VERSION ""

NS_ :

BS_:

BU_: SMART_CORE

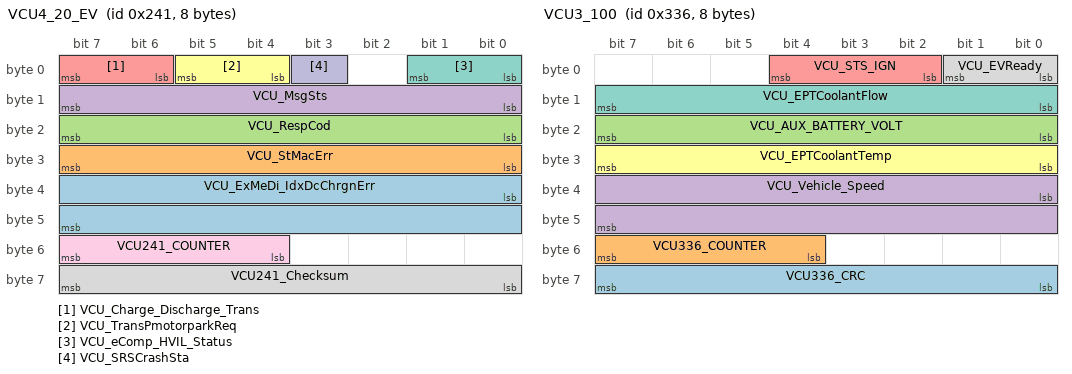
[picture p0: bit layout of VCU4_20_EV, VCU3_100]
BO_ 577 VCU4_20_EV: 8 Vector__XXX
 SG_ VCU_ExMeDi_IdxDcChrgnErr : 32|16@1+ (1,0) [0|65535] ""  SMART_CORE
 SG_ VCU_StMacErr : 24|8@1+ (1,0) [0|255] ""  SMART_CORE
 SG_ VCU_RespCod : 16|8@1+ (1,0) [0|255] ""  SMART_CORE
 SG_ VCU_MsgSts : 8|8@1+ (1,0) [0|255] ""  SMART_CORE
 SG_ VCU_Charge_Discharge_Trans : 6|2@1+ (1,0) [0|3] ""  SMART_CORE
 SG_ VCU_TransPmotorparkReq : 4|2@1+ (1,0) [0|3] "NA"  SMART_CORE
 SG_ VCU_eComp_HVIL_Status : 0|2@1+ (1,0) [0|3] ""  SMART_CORE
 SG_ VCU241_Checksum : 56|8@1+ (1,0) [0|255] ""  SMART_CORE
 SG_ VCU241_COUNTER : 52|4@1+ (1,0) [0|15] ""  SMART_CORE
 SG_ VCU_SRSCrashSta : 3|1@1+ (1,0) [0|1] ""  SMART_CORE

BO_ 822 VCU3_100: 8 Vector__XXX
 SG_ VCU336_CRC : 56|8@1+ (1,0) [0|255] "NA"  SMART_CORE
 SG_ VCU336_COUNTER : 52|4@1+ (1,0) [0|15] "NA"  SMART_CORE
 SG_ VCU_AUX_BATTERY_VOLT : 16|8@1+ (0.1,0) [0|16] "NA"  SMART_CORE
 SG_ VCU_Vehicle_Speed : 32|16@1+ (0.01,0) [0|300] "kmph"  SMART_CORE
 SG_ VCU_STS_IGN : 2|3@1+ (1,0) [0|7] ""  SMART_CORE
 SG_ VCU_EPTCoolantTemp : 24|8@1+ (1,-40) [-40|215] "deg C"  SMART_CORE
 SG_ VCU_EPTCoolantFlow : 8|8@1+ (0.5,0) [0|100] "%"  SMART_CORE
 SG_ VCU_EVReady : 0|2@1+ (1,0) [0|3] "NA"  SMART_CORE

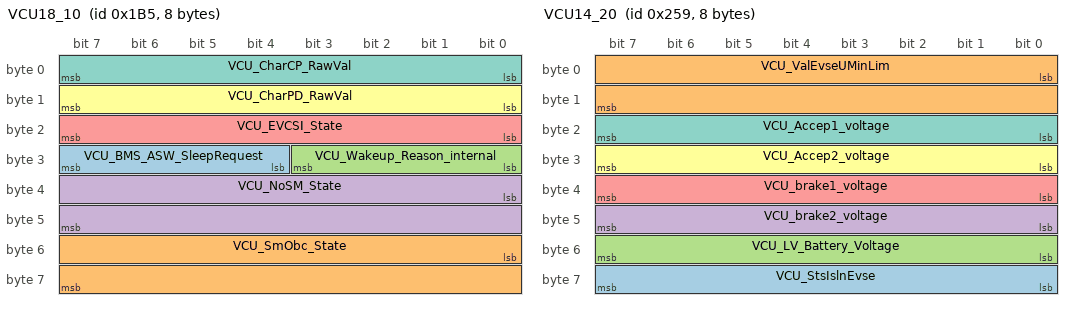
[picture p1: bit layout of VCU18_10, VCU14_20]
BO_ 437 VCU18_10: 8 Vector__XXX
 SG_ VCU_BMS_ASW_SleepRequest : 28|4@1+ (1,0) [0|7] "NA"  SMART_CORE
 SG_ VCU_SmObc_State : 48|16@1+ (1,0) [0|65535] ""  SMART_CORE
 SG_ VCU_Wakeup_Reason_internal : 24|4@1+ (1,0) [0|15] ""  SMART_CORE
 SG_ VCU_NoSM_State : 32|16@1+ (1,0) [0|65535] ""  SMART_CORE
 SG_ VCU_EVCSI_State : 16|8@1+ (1,0) [0|255] ""  SMART_CORE
 SG_ VCU_CharPD_RawVal : 8|8@1+ (0.1,0) [0|20] "V"  SMART_CORE
 SG_ VCU_CharCP_RawVal : 0|8@1+ (0.1,0) [0|20] "V"  SMART_CORE

BO_ 601 VCU14_20: 8 Vector__XXX
 SG_ VCU_StsIslnEvse : 56|8@1+ (1,0) [0|255] ""  SMART_CORE
 SG_ VCU_ValEvseUMinLim : 0|16@1+ (0.1,0) [0|1500] "V"  SMART_CORE
 SG_ VCU_LV_Battery_Voltage : 48|8@1+ (0.1,0) [0|25] "V"  SMART_CORE
 SG_ VCU_brake2_voltage : 40|8@1+ (0.1,0) [0|25] "V"  SMART_CORE
 SG_ VCU_brake1_voltage : 32|8@1+ (0.1,0) [0|25] "V"  SMART_CORE
 SG_ VCU_Accep2_voltage : 24|8@1+ (0.1,0) [0|25] "V"  SMART_CORE
 SG_ VCU_Accep1_voltage : 16|8@1+ (0.1,0) [0|25] "V"  SMART_CORE

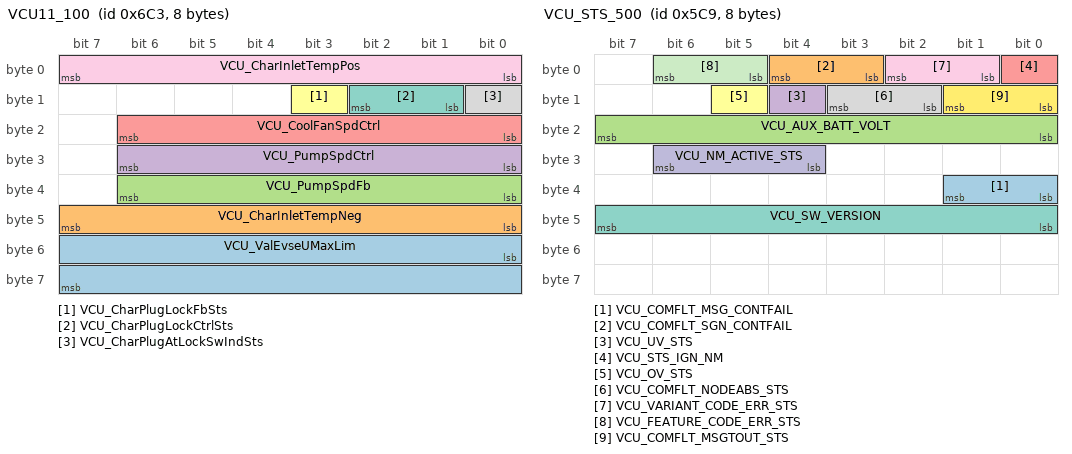
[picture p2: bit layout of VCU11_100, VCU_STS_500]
BO_ 1731 VCU11_100: 8 Vector__XXX
 SG_ VCU_ValEvseUMaxLim : 48|16@1+ (0.1,0) [0|1500] "V"  SMART_CORE
 SG_ VCU_CharInletTempNeg : 40|8@1+ (1,-40) [-40|215] "deg"  SMART_CORE
 SG_ VCU_PumpSpdFb : 32|7@1+ (1,0) [0|100] "%"  SMART_CORE
 SG_ VCU_PumpSpdCtrl : 24|7@1+ (1,0) [0|100] "%"  SMART_CORE
 SG_ VCU_CoolFanSpdCtrl : 16|7@1+ (1,0) [0|100] "%"  SMART_CORE
 SG_ VCU_CharPlugLockFbSts : 11|1@1+ (1,0) [0|1] ""  SMART_CORE
 SG_ VCU_CharPlugLockCtrlSts : 9|2@1+ (1,0) [0|2] ""  SMART_CORE
 SG_ VCU_CharPlugAtLockSwIndSts : 8|1@1+ (1,0) [0|1] ""  SMART_CORE
 SG_ VCU_CharInletTempPos : 0|8@1+ (1,-40) [-40|215] "deg"  SMART_CORE

BO_ 1481 VCU_STS_500: 8 Vector__XXX
 SG_ VCU_COMFLT_MSG_CONTFAIL : 32|2@1+ (1,0) [0|3] ""  SMART_CORE
 SG_ VCU_COMFLT_SGN_CONTFAIL : 3|2@1+ (1,0) [0|3] ""  SMART_CORE
 SG_ VCU_AUX_BATT_VOLT : 16|8@1+ (0.1,0) [0|16] ""  SMART_CORE
 SG_ VCU_UV_STS : 12|1@1+ (1,0) [0|1] ""  SMART_CORE
 SG_ VCU_STS_IGN_NM : 0|1@1+ (1,0) [0|1] ""  SMART_CORE
 SG_ VCU_OV_STS : 13|1@1+ (1,0) [0|1] ""  SMART_CORE
 SG_ VCU_SW_VERSION : 40|8@1+ (1,0) [0|255] ""  SMART_CORE
 SG_ VCU_COMFLT_NODEABS_STS : 10|2@1+ (1,0) [0|3] ""  SMART_CORE
 SG_ VCU_VARIANT_CODE_ERR_STS : 1|2@1+ (1,0) [0|3] ""  SMART_CORE
 SG_ VCU_NM_ACTIVE_STS : 28|3@1+ (1,0) [0|7] ""  SMART_CORE
 SG_ VCU_FEATURE_CODE_ERR_STS : 5|2@1+ (1,0) [0|3] ""  SMART_CORE
 SG_ VCU_COMFLT_MSGTOUT_STS : 8|2@1+ (1,0) [0|3] ""  SMART_CORE

BO_ 988 OBC6_100: 8 Vector__XXX
 SG_ OBC_VIN_MISMATCH_FAULT : 63|1@1+ (1,0) [0|1] ""  SMART_CORE
 SG_ OBC_ECU_RESET_FAULT : 62|1@1+ (1,0) [0|1] ""  SMART_CORE
 SG_ OBC_Low_Temp_Shutdown : 47|1@1+ (1,0) [0|1] ""  SMART_CORE
 SG_ OBC_HVDC_HW_OV : 35|1@1+ (1,0) [0|1] ""  SMART_CORE
 SG_ OBC_CPVol_Out_of_Range : 46|1@1+ (1,0) [0|1] ""  SMART_CORE
 SG_ OBC_CPDuty_Out_of_Range : 37|1@1+ (1,0) [0|1] ""  SMART_CORE
 SG_ OBC_HVDC_HW_OC : 36|1@1+ (1,0) [0|1] ""  SMART_CORE
 SG_ OBC_PRECHARGE_FAULT_CNT : 59|3@1+ (1,0) [0|7] ""  SMART_CORE
 SG_ OBC_PFC_BUS_FAULT_CNT : 56|3@1+ (1,0) [0|7] ""  SMART_CORE
 SG_ OBC_PFC_VOLT_CNTRL_IP : 48|8@1+ (1,-30) [-30|30] ""  SMART_CORE
 SG_ OBC_LIne_OC_SW : 16|1@1+ (1,0) [0|1] ""  SMART_CORE
 SG_ OBC_LLC_CONTROL_INPUT : 40|6@1+ (1,20) [-20|20] ""  SMART_CORE
 SG_ OBC_PLL_TIMELOCK_STS : 34|1@1+ (1,0) [0|1] ""  SMART_CORE
 SG_ OBC_CC_CV_STS : 33|1@1+ (1,0) [0|1] ""  SMART_CORE
 SG_ OBC_BURST_MODE_STS : 32|1@1+ (1,0) [0|1] ""  SMART_CORE
 SG_ OBC_STATE : 28|4@1+ (1,0) [0|1] ""  SMART_CORE
 SG_ OBC_LLC_OC_HW_FLAG : 18|1@1+ (1,0) [0|1] ""  SMART_CORE
 SG_ OBC_PFC_OC_HW_Flag : 17|1@1+ (1,0) [0|1] ""  SMART_CORE
 SG_ OBC_Inductr_current_L2_OC : 39|1@1+ (1,0) [0|1] ""  SMART_CORE
 SG_ OBC_Inductr_current_L1_OC : 38|1@1+ (1,0) [0|1] ""  SMART_CORE
 SG_ OBC_VPROG_OUT_OF_RANGE : 27|1@1+ (1,0) [0|1] ""  SMART_CORE
 SG_ OBC_TEMP_SENSOR_FAIL : 26|1@1+ (1,0) [0|1] ""  SMART_CORE
 SG_ OBC_OVER_TEMP : 25|1@1+ (1,0) [0|1] ""  SMART_CORE
 SG_ OBC_INTERNAL_FAIL : 24|1@1+ (1,0) [0|1] ""  SMART_CORE
 SG_ OBC_HIGH_TEMP : 23|1@1+ (1,0) [0|1] ""  SMART_CORE
 SG_ OBC_IPROG_OUT_OF_RANGE : 22|1@1+ (1,0) [0|1] ""  SMART_CORE
 SG_ OBC_EMI_IP_UV : 21|1@1+ (1,0) [0|1] ""  SMART_CORE
 SG_ OBC_EMI_IP_OV : 20|1@1+ (1,0) [0|1] ""  SMART_CORE
 SG_ OBC_EEPROM_FAIL : 19|1@1+ (1,0) [0|1] ""  SMART_CORE
 SG_ OBC_CAN_BUS_OFF : 15|1@1+ (1,0) [0|1] ""  SMART_CORE
 SG_ OBC_TEMP_DERATE : 14|1@1+ (1,0) [0|1] ""  SMART_CORE
 SG_ OBC_PRE_CHARGE_FAULT : 13|1@1+ (1,0) [0|1] ""  SMART_CORE
 SG_ OBC_PFV_OV : 12|1@1+ (1,0) [0|1] ""  SMART_CORE
 SG_ OBC_PFC_UV : 11|1@1+ (1,0) [0|1] ""  SMART_CORE
 SG_ OBC_PFC_OVER_TEMP : 10|1@1+ (1,0) [0|1] ""  SMART_CORE
 SG_ OBC_OP_UV : 9|1@1+ (1,0) [0|1] ""  SMART_CORE
 SG_ OBC_OP_OV : 8|1@1+ (1,0) [0|1] ""  SMART_CORE
 SG_ OBC_OP_OC : 7|1@1+ (1,0) [0|1] ""  SMART_CORE
 SG_ OBC_LV_UNDER_VOLT : 6|1@1+ (1,0) [0|1] ""  SMART_CORE
 SG_ OBC_LV_OVER_VOLT : 5|1@1+ (1,0) [0|1] ""  SMART_CORE
 SG_ OBC_LLC_OVER_TEMP : 4|1@1+ (1,0) [0|1] ""  SMART_CORE
 SG_ OBC_IP_UNDER_VOLT : 3|1@1+ (1,0) [0|1] ""  SMART_CORE
 SG_ OBC_IP_OVER_VOLT : 2|1@1+ (1,0) [0|1] ""  SMART_CORE
 SG_ OBC_IP_OVER_CURR : 1|1@1+ (1,0) [0|1] ""  SMART_CORE
 SG_ OBC_IP_DERATE : 0|1@1+ (1,0) [0|1] ""  SMART_CORE

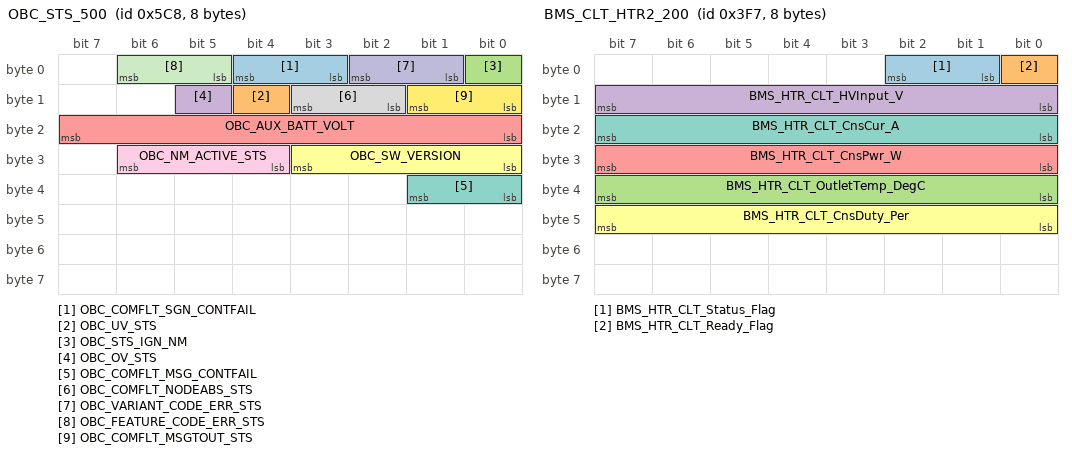
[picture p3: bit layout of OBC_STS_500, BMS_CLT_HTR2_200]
BO_ 1480 OBC_STS_500: 8 Vector__XXX
 SG_ OBC_COMFLT_SGN_CONTFAIL : 3|2@1+ (1,0) [0|3] ""  SMART_CORE
 SG_ OBC_UV_STS : 12|1@1+ (1,0) [0|1] ""  SMART_CORE
 SG_ OBC_STS_IGN_NM : 0|1@1+ (1,0) [0|1] ""  SMART_CORE
 SG_ OBC_OV_STS : 13|1@1+ (1,0) [0|1] ""  SMART_CORE
 SG_ OBC_AUX_BATT_VOLT : 16|8@1+ (0.1,0) [0|16] ""  SMART_CORE
 SG_ OBC_SW_VERSION : 24|4@1+ (1,0) [0|15] ""  SMART_CORE
 SG_ OBC_COMFLT_MSG_CONTFAIL : 32|2@1+ (1,0) [0|3] ""  SMART_CORE
 SG_ OBC_COMFLT_NODEABS_STS : 10|2@1+ (1,0) [0|3] ""  SMART_CORE
 SG_ OBC_NM_ACTIVE_STS : 28|3@1+ (1,0) [0|7] ""  SMART_CORE
 SG_ OBC_VARIANT_CODE_ERR_STS : 1|2@1+ (1,0) [0|3] ""  SMART_CORE
 SG_ OBC_FEATURE_CODE_ERR_STS : 5|2@1+ (1,0) [0|3] ""  SMART_CORE
 SG_ OBC_COMFLT_MSGTOUT_STS : 8|2@1+ (1,0) [0|3] ""  SMART_CORE

BO_ 983 MCU5_100: 8 Vector__XXX
 SG_ MCU_TPI : 8|8@1+ (0.01,0) [0|2] ""  SMART_CORE
 SG_ MCU_MotorCoolingFlowReq : 32|8@1+ (0.5,0) [0|100] "%"  SMART_CORE
 SG_ MCU_Motor_Temp_Indicator : 24|8@1+ (1,-50) [-50|200] "deg C"  SMART_CORE
 SG_ MCU_Inverter_Temp_Indicator : 16|8@1+ (1,-50) [-50|200] "deg C"  SMART_CORE
 SG_ MCU_Inverter_CoolingFlowReq : 0|8@1+ (0.5,0) [0|100] "%"  SMART_CORE

BO_ 280 MCU2_10: 8 Vector__XXX
 SG_ MCU118_COUNTER : 52|4@1+ (1,0) [0|15] ""  SMART_CORE
 SG_ MCU118_Checksum : 56|8@1+ (1,0) [0|255] ""  SMART_CORE
 SG_ MCU_MotorSpeed : 16|16@1+ (1,-32767) [-32760|32760] "RPM"  SMART_CORE
 SG_ MCU_MotorTorqueEstimated : 0|16@1+ (0.0625,-2048) [-2045|2045] "Nm"  SMART_CORE

BO_ 1016 BMS_CLT_HTR3_200: 8 Vector__XXX
 SG_ BMS_HTR_CLT_SoftwareVersion_Num : 56|8@1+ (1,0) [0|255] ""  SMART_CORE
 SG_ BMS_HTR_CLT_Fault_PCBTempSen : 28|1@1+ (1,0) [0|1] ""  SMART_CORE
 SG_ BMS_HTR_CLT_Fault_PCBTempOver : 14|1@1+ (1,0) [0|1] ""  SMART_CORE
 SG_ BMS_HTR_CLT_Fault_OutletTempSen : 27|1@1+ (1,0) [0|1] ""  SMART_CORE
 SG_ BMS_HTR_CLT_Fault_OutletTempOver : 13|1@1+ (1,0) [0|1] ""  SMART_CORE
 SG_ BMS_HTR_CLT_Fault_LVSen : 24|1@1+ (1,0) [0|1] ""  SMART_CORE
 SG_ BMS_HTR_CLT_Fault_LostCtrlMsg : 15|1@1+ (1,0) [0|1] ""  SMART_CORE
 SG_ BMS_HTR_CLT_Fault_IGBTShort : 30|1@1+ (1,0) [0|1] ""  SMART_CORE
 SG_ BMS_HTR_CLT_Fault_IGBTOpen : 29|1@1+ (1,0) [0|1] ""  SMART_CORE
 SG_ BMS_HTR_CLT_Fault_IGBTDriverIC : 31|1@1+ (1,0) [0|1] ""  SMART_CORE
 SG_ BMS_HTR_CLT_Fault_HVSen : 25|1@1+ (1,0) [0|1] ""  SMART_CORE
 SG_ BMS_HTR_CLT_Fault_HVOver : 11|1@1+ (1,0) [0|1] ""  SMART_CORE
 SG_ BMS_HTR_CLT_Fault_HVCurSen : 26|1@1+ (1,0) [0|1] ""  SMART_CORE
 SG_ BMS_HTR_CLT_LIN_Com_Err_Flag : 1|1@1+ (1,0) [0|1] ""  SMART_CORE
 SG_ BMS_HTR_CLT_Fault_LVUnder : 8|1@1+ (1,0) [0|1] ""  SMART_CORE
 SG_ BMS_HTR_CLT_Fault_LVOver : 9|1@1+ (1,0) [0|1] ""  SMART_CORE
 SG_ BMS_HTR_CLT_Fault_HVUnder : 10|1@1+ (1,0) [0|1] ""  SMART_CORE
 SG_ BMS_HTR_CLT_Fault_HVOverCur : 12|1@1+ (1,0) [0|1] ""  SMART_CORE
 SG_ BMS_HTR_CLT_Fault_Flag : 0|1@1+ (1,0) [0|1] ""  SMART_CORE

BO_ 1918 MGM_FOTA_DIAG_RES: 8 Vector__XXX
 SG_ DIAG_MGM_FOTA_RES_DATA : 0|64@1+ (1,0) [0|1.8446744074E+019] ""  SMART_CORE

BO_ 1910 MGM_FOTA_DIAG_REQ: 8 SMART_CORE
 SG_ DIAG_MGM_FOTA_REQ_DATA : 0|64@1+ (1,0) [0|1.8446744074E+019] "" Vector__XXX

BO_ 1015 BMS_CLT_HTR2_200: 8 Vector__XXX
 SG_ BMS_HTR_CLT_Status_Flag : 1|2@1+ (1,1) [0|2] ""  SMART_CORE
 SG_ BMS_HTR_CLT_Ready_Flag : 0|1@1+ (1,0) [0|1] ""  SMART_CORE
 SG_ BMS_HTR_CLT_OutletTemp_DegC : 32|8@1+ (1,0) [0|255] ""  SMART_CORE
 SG_ BMS_HTR_CLT_HVInput_V : 8|8@1+ (1,0) [0|255] ""  SMART_CORE
 SG_ BMS_HTR_CLT_CnsPwr_W : 24|8@1+ (1,0) [0|255] ""  SMART_CORE
 SG_ BMS_HTR_CLT_CnsDuty_Per : 40|8@1+ (1,0) [0|255] ""  SMART_CORE
 SG_ BMS_HTR_CLT_CnsCur_A : 16|8@1+ (1,0) [0|255] ""  SMART_CORE

BO_ 1014 BMS_CLT_HTR1_200: 8 Vector__XXX
 SG_ BMS_HTR_CltTemp_DegC : 16|8@1+ (1,0) [0|255] ""  SMART_CORE
 SG_ BMS_HTR_CltPerf_Perc : 8|8@1- (1,0) [0|255] ""  SMART_CORE
 SG_ BMS_HTR_CltAllowance_Flag : 0|1@1+ (1,0) [0|1] ""  SMART_CORE

BO_ 993 VCU_ACTIVE_EV: 8 Vector__XXX
 SG_ VCU_ACTIVE_RESERVED_EV : 0|64@1+ (1,0) [0|0] "NA"  SMART_CORE

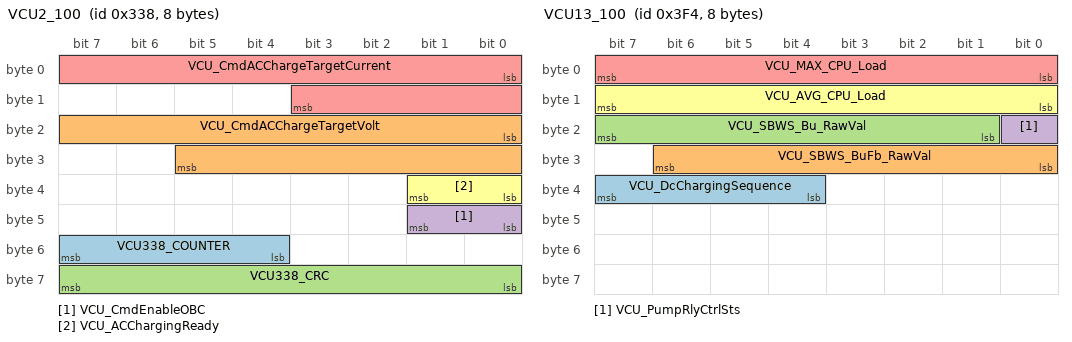
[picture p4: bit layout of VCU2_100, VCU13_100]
BO_ 824 VCU2_100: 8 Vector__XXX
 SG_ VCU338_COUNTER : 52|4@1+ (1,0) [0|15] "NA"  SMART_CORE
 SG_ VCU_CmdACChargeTargetVolt : 16|14@1+ (0.1,0) [0|500] "V"  SMART_CORE
 SG_ VCU338_CRC : 56|8@1+ (1,0) [0|255] "NA"  SMART_CORE
 SG_ VCU_CmdEnableOBC : 40|2@1+ (1,0) [0|3] "NA"  SMART_CORE
 SG_ VCU_CmdACChargeTargetCurrent : 0|12@1+ (0.01,0) [0|35] "A"  SMART_CORE
 SG_ VCU_ACChargingReady : 32|2@1+ (1,0) [0|3] ""  SMART_CORE

BO_ 1474 VCU17_500: 8 Vector__XXX
 SG_ VCU_AVAIL_BAT_HEATER_PWR : 48|8@1+ (50,0) [0|8000] "Watts"  SMART_CORE

BO_ 1736 VCU16_1000: 8 Vector__XXX
 SG_ VCU_EConsDistSample4 : 48|16@1+ (0.001,0) [0|65.535] "Kwh"  SMART_CORE
 SG_ VCU_EConsDistSample3 : 32|16@1+ (0.001,0) [0|65.535] "Kwh"  SMART_CORE
 SG_ VCU_EConsDistSample2 : 16|16@1+ (0.001,0) [0|65.535] "Kwh"  SMART_CORE
 SG_ VCU_EConsDistSample1 : 0|16@1+ (0.001,0) [0|65.535] "Kwh"  SMART_CORE

BO_ 1012 VCU13_100: 8 Vector__XXX
 SG_ VCU_DcChargingSequence : 36|4@1+ (1,0) [0|15] ""  SMART_CORE
 SG_ VCU_SBWS_BuFb_RawVal : 24|7@1+ (1,0) [0|100] "%"  SMART_CORE
 SG_ VCU_SBWS_Bu_RawVal : 17|7@1+ (1,0) [0|100] "%"  SMART_CORE
 SG_ VCU_PumpRlyCtrlSts : 16|1@1+ (1,0) [0|1] ""  SMART_CORE
 SG_ VCU_MAX_CPU_Load : 0|8@1+ (1,0) [0|200] ""  SMART_CORE
 SG_ VCU_AVG_CPU_Load : 8|8@1+ (1,0) [0|200] ""  SMART_CORE

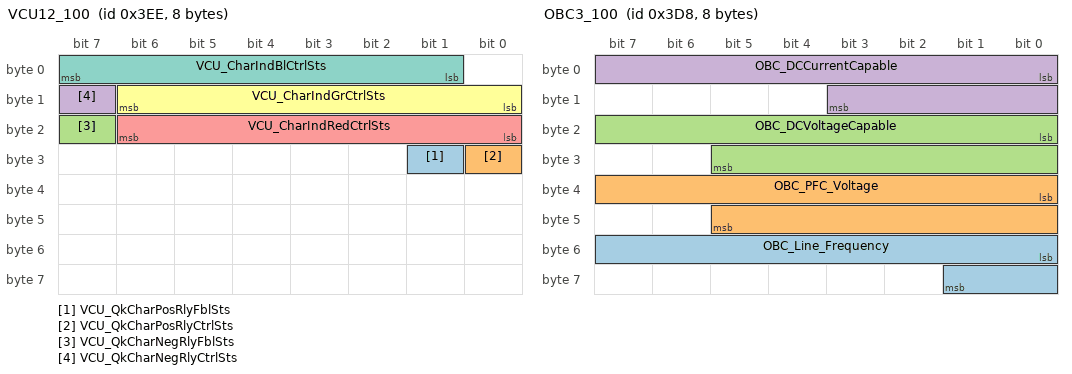
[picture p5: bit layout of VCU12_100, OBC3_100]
BO_ 1006 VCU12_100: 8 Vector__XXX
 SG_ VCU_QkCharPosRlyFblSts : 25|1@1+ (1,0) [0|1] ""  SMART_CORE
 SG_ VCU_QkCharPosRlyCtrlSts : 24|1@1+ (1,0) [0|1] ""  SMART_CORE
 SG_ VCU_QkCharNegRlyFblSts : 23|1@1+ (1,0) [0|1] ""  SMART_CORE
 SG_ VCU_QkCharNegRlyCtrlSts : 15|1@1+ (1,0) [0|1] ""  SMART_CORE
 SG_ VCU_CharIndRedCtrlSts : 16|7@1+ (1,0) [0|100] "%"  SMART_CORE
 SG_ VCU_CharIndGrCtrlSts : 8|7@1+ (1,0) [0|100] "%"  SMART_CORE
 SG_ VCU_CharIndBlCtrlSts : 1|7@1+ (1,0) [0|100] "%"  SMART_CORE

BO_ 984 OBC3_100: 8 Vector__XXX
 SG_ OBC_Line_Frequency : 48|10@1+ (1,0) [40|65] ""  SMART_CORE
 SG_ OBC_PFC_Voltage : 32|14@1+ (0.1,0) [0|500] ""  SMART_CORE
 SG_ OBC_DCVoltageCapable : 16|14@1+ (0.1,0) [0|500] "V"  SMART_CORE
 SG_ OBC_DCCurrentCapable : 0|12@1+ (0.01,0) [0|30] "A"  SMART_CORE

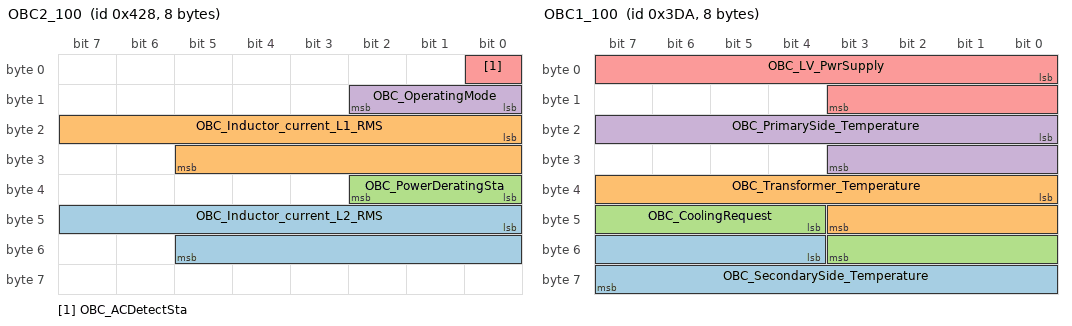
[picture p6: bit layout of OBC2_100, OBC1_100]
BO_ 1064 OBC2_100: 8 Vector__XXX
 SG_ OBC_Inductor_current_L2_RMS : 40|14@1+ (0.01,0) [0|20] ""  SMART_CORE
 SG_ OBC_Inductor_current_L1_RMS : 16|14@1+ (0.01,0) [0|20] ""  SMART_CORE
 SG_ OBC_PowerDeratingSta : 32|3@1+ (1,0) [0|7] "NA"  SMART_CORE
 SG_ OBC_OperatingMode : 8|3@1+ (1,0) [0|7] "NA"  SMART_CORE
 SG_ OBC_ACDetectSta : 0|1@1+ (1,0) [0|1] "NA"  SMART_CORE

BO_ 986 OBC1_100: 8 Vector__XXX
 SG_ OBC_SecondarySide_Temperature : 52|12@1+ (0.1,-55) [-55|150] ""  SMART_CORE
 SG_ OBC_Transformer_Temperature : 32|12@1+ (0.1,-55) [-55|150] "deg C"  SMART_CORE
 SG_ OBC_CoolingRequest : 44|8@1+ (0.5,0) [0|100] "%"  SMART_CORE
 SG_ OBC_PrimarySide_Temperature : 16|12@1+ (0.1,-55) [-55|150] "deg C"  SMART_CORE
 SG_ OBC_LV_PwrSupply : 0|12@1+ (0.01,0) [0|25] ""  SMART_CORE

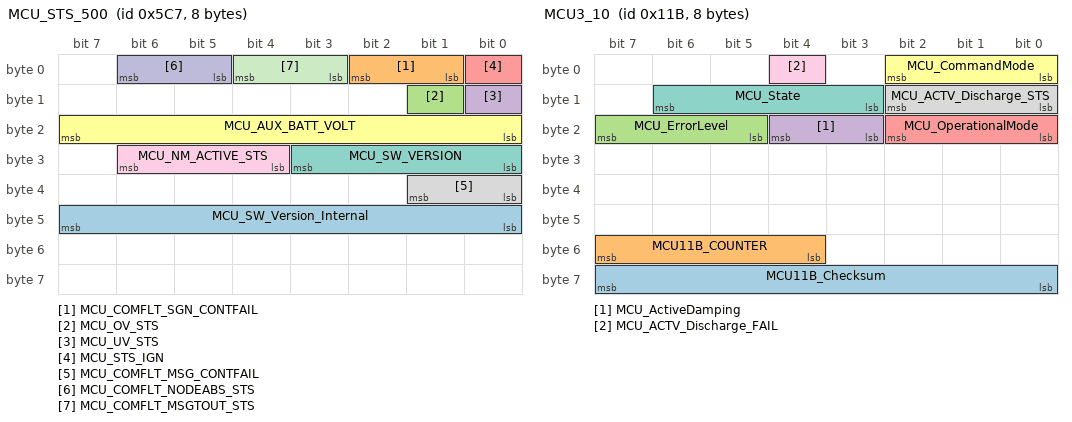
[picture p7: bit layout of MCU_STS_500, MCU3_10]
BO_ 1479 MCU_STS_500: 8 Vector__XXX
 SG_ MCU_SW_Version_Internal : 40|8@1+ (1,0) [0|255] ""  SMART_CORE
 SG_ MCU_COMFLT_SGN_CONTFAIL : 1|2@1+ (1,0) [0|3] ""  SMART_CORE
 SG_ MCU_OV_STS : 9|1@1+ (1,0) [0|1] ""  SMART_CORE
 SG_ MCU_UV_STS : 8|1@1+ (1,0) [0|1] ""  SMART_CORE
 SG_ MCU_STS_IGN : 0|1@1+ (1,0) [0|1] ""  SMART_CORE
 SG_ MCU_AUX_BATT_VOLT : 16|8@1+ (0.1,0) [0|16] ""  SMART_CORE
 SG_ MCU_SW_VERSION : 24|4@1+ (1,0) [0|15] ""  SMART_CORE
 SG_ MCU_COMFLT_MSG_CONTFAIL : 32|2@1+ (1,0) [0|3] ""  SMART_CORE
 SG_ MCU_NM_ACTIVE_STS : 28|3@1+ (1,0) [0|7] ""  SMART_CORE
 SG_ MCU_COMFLT_NODEABS_STS : 5|2@1+ (1,0) [0|3] ""  SMART_CORE
 SG_ MCU_COMFLT_MSGTOUT_STS : 3|2@1+ (1,0) [0|3] ""  SMART_CORE

BO_ 283 MCU3_10: 8 Vector__XXX
 SG_ MCU11B_Checksum : 56|8@1+ (1,0) [0|255] ""  SMART_CORE
 SG_ MCU11B_COUNTER : 52|4@1+ (1,0) [0|15] ""  SMART_CORE
 SG_ MCU_ErrorLevel : 21|3@1+ (1,0) [0|7] "NA"  SMART_CORE
 SG_ MCU_ActiveDamping : 19|2@1+ (1,0) [0|3] "NA"  SMART_CORE
 SG_ MCU_OperationalMode : 16|3@1+ (1,0) [0|7] "NA"  SMART_CORE
 SG_ MCU_CommandMode : 0|3@1+ (1,0) [0|7] "NA"  SMART_CORE
 SG_ MCU_State : 11|4@1+ (1,0) [0|15] ""  SMART_CORE
 SG_ MCU_ACTV_Discharge_STS : 8|3@1+ (1,0) [0|3] ""  SMART_CORE
 SG_ MCU_ACTV_Discharge_FAIL : 4|1@1+ (1,0) [0|1] ""  SMART_CORE

BO_ 982 MCU1_100: 8 Vector__XXX
 SG_ MCU_HighPowerCurrent : 48|14@1+ (0.25,-2046) [-2046|2048] "A"  SMART_CORE
 SG_ MCU_HighPowerVoltage : 32|11@1+ (1,0) [0|2046] "V"  SMART_CORE
 SG_ MCU_TractionTorqueAvail_quasi : 16|15@1+ (0.0625,0) [0|2045] "Nm"  SMART_CORE
 SG_ MCU_RegenTorqueAvail_quasi : 0|15@1+ (0.0625,0) [0|2045] "Nm"  SMART_CORE

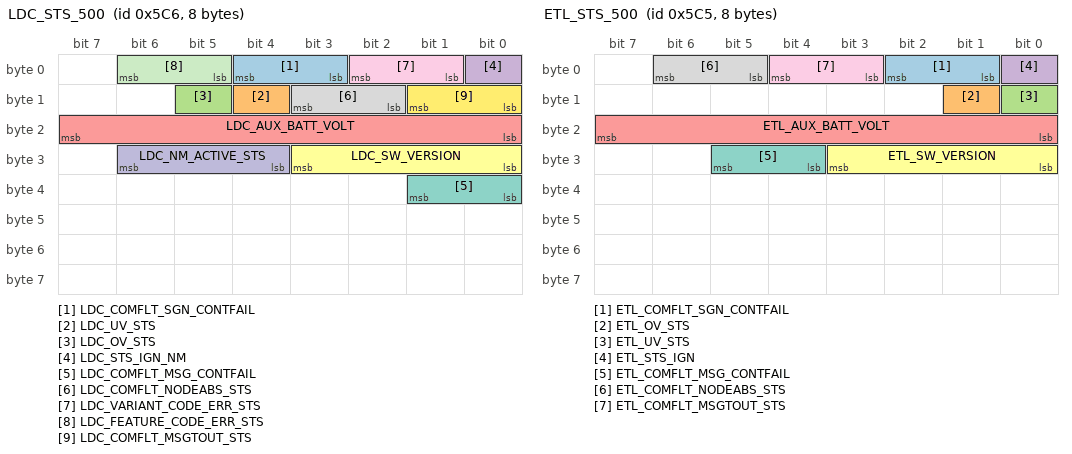
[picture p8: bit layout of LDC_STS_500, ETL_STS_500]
BO_ 1478 LDC_STS_500: 8 Vector__XXX
 SG_ LDC_COMFLT_SGN_CONTFAIL : 3|2@1+ (1,0) [0|3] ""  SMART_CORE
 SG_ LDC_UV_STS : 12|1@1+ (1,0) [0|1] ""  SMART_CORE
 SG_ LDC_OV_STS : 13|1@1+ (1,0) [0|1] ""  SMART_CORE
 SG_ LDC_STS_IGN_NM : 0|1@1+ (1,0) [0|1] ""  SMART_CORE
 SG_ LDC_AUX_BATT_VOLT : 16|8@1+ (0.1,0) [0|16] ""  SMART_CORE
 SG_ LDC_SW_VERSION : 24|4@1+ (1,0) [0|15] ""  SMART_CORE
 SG_ LDC_COMFLT_MSG_CONTFAIL : 32|2@1+ (1,0) [0|3] ""  SMART_CORE
 SG_ LDC_COMFLT_NODEABS_STS : 10|2@1+ (1,0) [0|3] ""  SMART_CORE
 SG_ LDC_VARIANT_CODE_ERR_STS : 1|2@1+ (1,0) [0|3] ""  SMART_CORE
 SG_ LDC_NM_ACTIVE_STS : 28|3@1+ (1,0) [0|7] ""  SMART_CORE
 SG_ LDC_FEATURE_CODE_ERR_STS : 5|2@1+ (1,0) [0|3] ""  SMART_CORE
 SG_ LDC_COMFLT_MSGTOUT_STS : 8|2@1+ (1,0) [0|3] ""  SMART_CORE

BO_ 1477 ETL_STS_500: 8 Vector__XXX
 SG_ ETL_COMFLT_SGN_CONTFAIL : 1|2@1+ (1,0) [0|3] ""  SMART_CORE
 SG_ ETL_OV_STS : 9|1@1+ (1,0) [0|1] ""  SMART_CORE
 SG_ ETL_UV_STS : 8|1@1+ (1,0) [0|1] ""  SMART_CORE
 SG_ ETL_STS_IGN : 0|1@1+ (1,0) [0|1] ""  SMART_CORE
 SG_ ETL_AUX_BATT_VOLT : 16|8@1+ (0.1,0) [0|16] ""  SMART_CORE
 SG_ ETL_SW_VERSION : 24|4@1+ (1,0) [0|15] ""  SMART_CORE
 SG_ ETL_COMFLT_MSG_CONTFAIL : 28|2@1+ (1,0) [0|3] ""  SMART_CORE
 SG_ ETL_COMFLT_NODEABS_STS : 5|2@1+ (1,0) [0|3] ""  SMART_CORE
 SG_ ETL_COMFLT_MSGTOUT_STS : 3|2@1+ (1,0) [0|3] ""  SMART_CORE

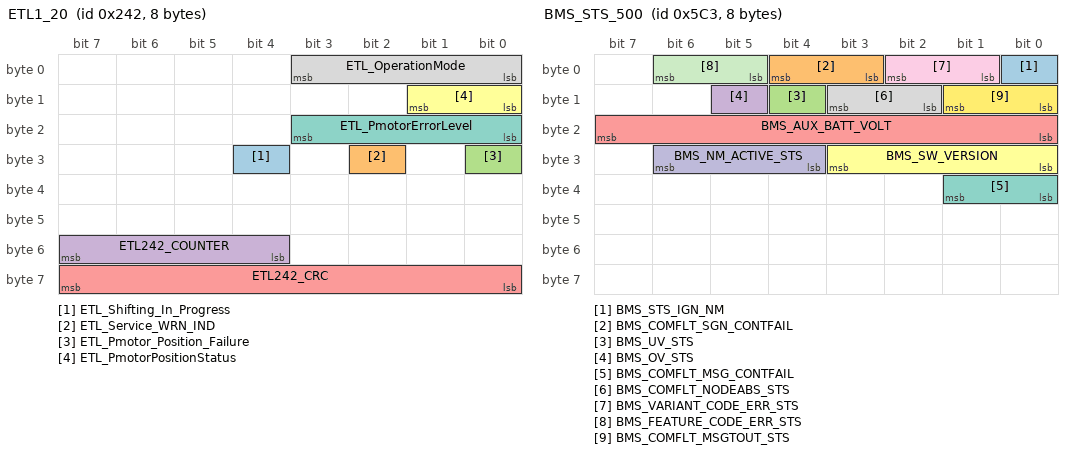
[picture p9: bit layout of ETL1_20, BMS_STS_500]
BO_ 578 ETL1_20: 8 Vector__XXX
 SG_ ETL_Shifting_In_Progress : 28|1@1+ (1,0) [0|1] ""  SMART_CORE
 SG_ ETL_Service_WRN_IND : 26|1@1+ (1,0) [0|1] ""  SMART_CORE
 SG_ ETL_Pmotor_Position_Failure : 24|1@1+ (1,0) [0|1] ""  SMART_CORE
 SG_ ETL242_COUNTER : 52|4@1+ (1,0) [0|14] "NA"  SMART_CORE
 SG_ ETL242_CRC : 56|8@1+ (1,0) [0|255] "NA"  SMART_CORE
 SG_ ETL_PmotorPositionStatus : 8|2@1+ (1,0) [0|3] "NA"  SMART_CORE
 SG_ ETL_PmotorErrorLevel : 16|4@1+ (1,0) [0|15] "NA"  SMART_CORE
 SG_ ETL_OperationMode : 0|4@1+ (1,0) [0|15] "NA"  SMART_CORE

BO_ 1475 BMS_STS_500: 8 Vector__XXX
 SG_ BMS_STS_IGN_NM : 0|1@1+ (1,0) [0|1] ""  SMART_CORE
 SG_ BMS_COMFLT_SGN_CONTFAIL : 3|2@1+ (1,0) [0|3] ""  SMART_CORE
 SG_ BMS_UV_STS : 12|1@1+ (1,0) [0|1] ""  SMART_CORE
 SG_ BMS_OV_STS : 13|1@1+ (1,0) [0|1] ""  SMART_CORE
 SG_ BMS_AUX_BATT_VOLT : 16|8@1+ (0.1,0) [0|16] ""  SMART_CORE
 SG_ BMS_SW_VERSION : 24|4@1+ (1,0) [0|15] ""  SMART_CORE
 SG_ BMS_COMFLT_MSG_CONTFAIL : 32|2@1+ (1,0) [0|3] ""  SMART_CORE
 SG_ BMS_COMFLT_NODEABS_STS : 10|2@1+ (1,0) [0|3] ""  SMART_CORE
 SG_ BMS_VARIANT_CODE_ERR_STS : 1|2@1+ (1,0) [0|3] ""  SMART_CORE
 SG_ BMS_NM_ACTIVE_STS : 28|3@1+ (1,0) [0|7] ""  SMART_CORE
 SG_ BMS_FEATURE_CODE_ERR_STS : 5|2@1+ (1,0) [0|3] ""  SMART_CORE
 SG_ BMS_COMFLT_MSGTOUT_STS : 8|2@1+ (1,0) [0|3] ""  SMART_CORE

BO_ 1002 BMS17_100: 8 Vector__XXX
 SG_ BMS_Regen_AH : 32|16@1+ (0.01,0) [0|300] "AH"  SMART_CORE
 SG_ BMS_KiloWattHour : 16|16@1+ (0.01,0) [0|50] "KWH"  SMART_CORE
 SG_ BMS_AmpereHour : 0|16@1+ (0.01,0) [0|300] "Ah"  SMART_CORE

BO_ 980 BMS7_100: 8 Vector__XXX
 SG_ BMS_Batt_Overcurrent_Sta : 48|2@1+ (1,0) [0|3] "NA"  SMART_CORE
 SG_ BMS_DischargePowerAvailable_2 : 16|16@1+ (0.01,0) [0|200] "Kw"  SMART_CORE
 SG_ BMS_DischargePowerAvailable_10 : 0|16@1+ (0.01,0) [0|200] "Kw"  SMART_CORE
 SG_ BMS_BatteryPackSOE : 32|12@1+ (0.01,0) [0|45] "Kwh"  SMART_CORE

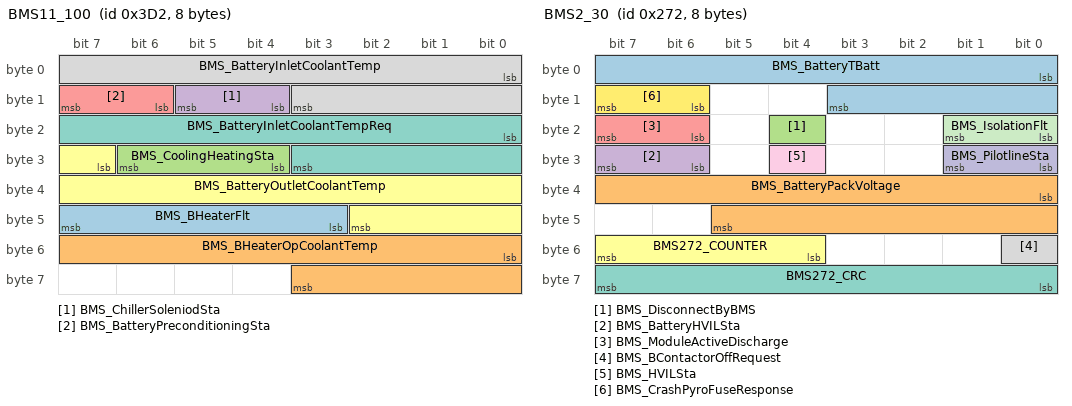
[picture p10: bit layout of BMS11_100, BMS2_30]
BO_ 978 BMS11_100: 8 Vector__XXX
 SG_ BMS_BHeaterFlt : 43|5@1+ (1,0) [0|32] ""  SMART_CORE
 SG_ BMS_BHeaterOpCoolantTemp : 48|12@1+ (0.1,-40) [-40|200] "deg C"  SMART_CORE
 SG_ BMS_CoolingHeatingSta : 28|3@1+ (1,0) [0|7] ""  SMART_CORE
 SG_ BMS_ChillerSoleniodSta : 12|2@1+ (1,0) [0|3] ""  SMART_CORE
 SG_ BMS_BatteryPreconditioningSta : 14|2@1+ (1,0) [0|3] ""  SMART_CORE
 SG_ BMS_BatteryOutletCoolantTemp : 31|12@1+ (0.1,-40) [-40|125] "deg C"  SMART_CORE
 SG_ BMS_BatteryInletCoolantTempReq : 16|12@1+ (0.1,-40) [-40|125] "deg C"  SMART_CORE
 SG_ BMS_BatteryInletCoolantTemp : 0|12@1+ (0.1,-40) [-40|125] "deg C"  SMART_CORE

BO_ 626 BMS2_30: 8 Vector__XXX
 SG_ BMS_BatteryTBatt : 0|12@1+ (0.1,-40) [-40|125] "deg C"  SMART_CORE
 SG_ BMS_BatteryPackVoltage : 32|14@1+ (0.1,0) [0|460] "V"  SMART_CORE
 SG_ BMS_DisconnectByBMS : 20|1@1+ (1,0) [0|1] ""  SMART_CORE
 SG_ BMS_BatteryHVILSta : 30|2@1+ (1,0) [0|3] "NA"  SMART_CORE
 SG_ BMS_ModuleActiveDischarge : 22|2@1+ (1,0) [0|3] ""  SMART_CORE
 SG_ BMS272_COUNTER : 52|4@1+ (1,0) [0|0] "NA"  SMART_CORE
 SG_ BMS272_CRC : 56|8@1+ (1,0) [0|0] "NA"  SMART_CORE
 SG_ BMS_BContactorOffRequest : 48|1@1+ (1,0) [0|1] "NA"  SMART_CORE
 SG_ BMS_HVILSta : 28|1@1+ (1,0) [0|1] "NA"  SMART_CORE
 SG_ BMS_PilotlineSta : 24|2@1+ (1,0) [0|3] "NA"  SMART_CORE
 SG_ BMS_IsolationFlt : 16|2@1+ (1,0) [0|3] "NA"  SMART_CORE
 SG_ BMS_CrashPyroFuseResponse : 14|2@1+ (1,0) [0|3] ""  SMART_CORE

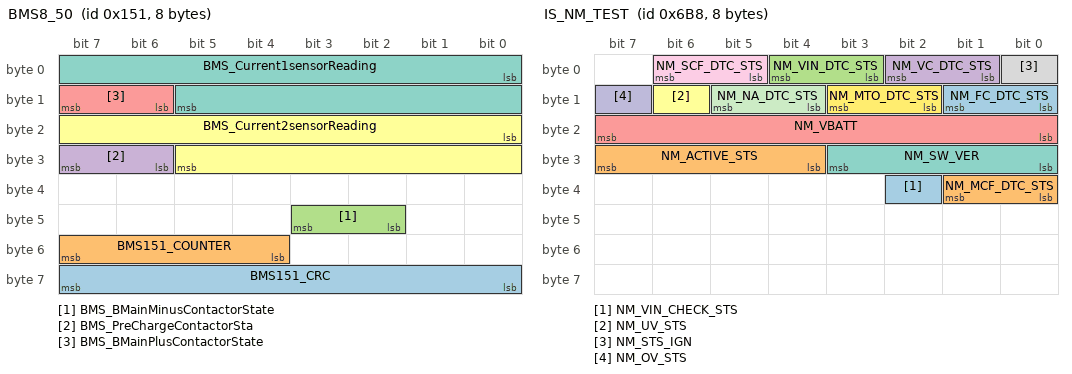
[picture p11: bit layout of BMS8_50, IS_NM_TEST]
BO_ 337 BMS8_50: 8 Vector__XXX
 SG_ BMS151_CRC : 56|8@1+ (1,0) [0|0] "NA"  SMART_CORE
 SG_ BMS151_COUNTER : 52|4@1+ (1,0) [0|0] "NA"  SMART_CORE
 SG_ BMS_BMainMinusContactorState : 42|2@1+ (1,0) [0|3] "NA"  SMART_CORE
 SG_ BMS_PreChargeContactorSta : 30|2@1+ (1,0) [0|3] ""  SMART_CORE
 SG_ BMS_BMainPlusContactorState : 14|2@1+ (1,0) [0|3] "NA"  SMART_CORE
 SG_ BMS_Current2sensorReading : 16|14@1+ (0.1,-600) [-600|600] "A"  SMART_CORE
 SG_ BMS_Current1sensorReading : 0|14@1+ (0.1,-600) [-600|600] "A"  SMART_CORE

BO_ 1720 IS_NM_TEST: 8 SMART_CORE
 SG_ NM_VIN_CHECK_STS : 34|1@1+ (1,0) [0|1] "" Vector__XXX
 SG_ NM_MCF_DTC_STS : 32|2@1+ (1,0) [0|3] "" Vector__XXX
 SG_ NM_VIN_DTC_STS : 3|2@1+ (1,0) [0|3] "" Vector__XXX
 SG_ NM_VC_DTC_STS : 1|2@1+ (1,0) [0|3] "" Vector__XXX
 SG_ NM_VBATT : 16|8@1+ (0.1,0) [0|25] "Volt" Vector__XXX
 SG_ NM_UV_STS : 14|1@1+ (1,0) [0|1] "" Vector__XXX
 SG_ NM_SW_VER : 24|4@1+ (1,0) [0|15] "" Vector__XXX
 SG_ NM_STS_IGN : 0|1@1+ (1,0) [0|1] "" Vector__XXX
 SG_ NM_SCF_DTC_STS : 5|2@1+ (1,0) [0|3] "" Vector__XXX
 SG_ NM_OV_STS : 15|1@1+ (1,0) [0|1] "" Vector__XXX
 SG_ NM_NA_DTC_STS : 12|2@1+ (1,0) [0|3] "" Vector__XXX
 SG_ NM_MTO_DTC_STS : 10|2@1+ (1,0) [0|3] "" Vector__XXX
 SG_ NM_FC_DTC_STS : 8|2@1+ (1,0) [0|3] "" Vector__XXX
 SG_ NM_ACTIVE_STS : 28|4@1+ (1,0) [0|15] "" Vector__XXX

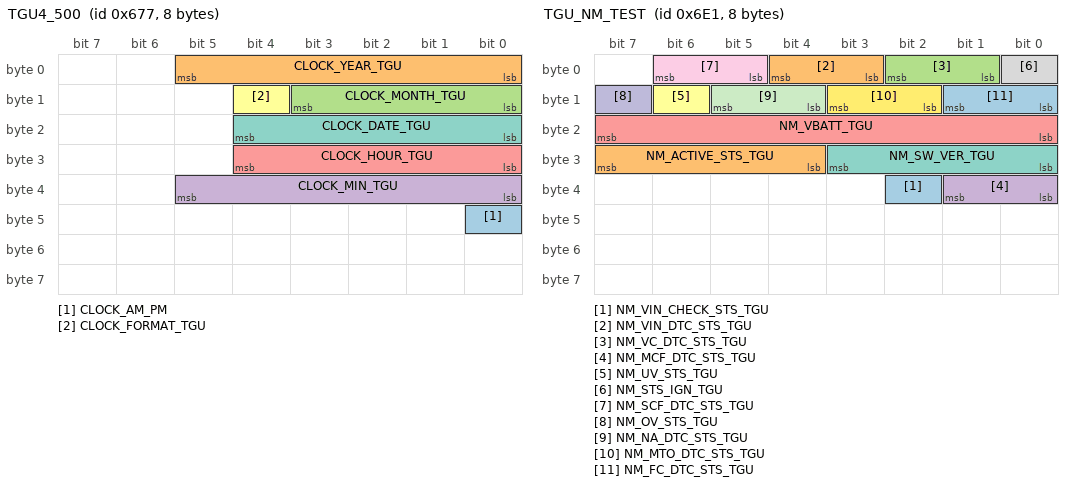
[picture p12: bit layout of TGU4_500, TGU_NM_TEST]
BO_ 1655 TGU4_500: 8 SMART_CORE
 SG_ CLOCK_AM_PM : 40|1@1+ (1,0) [0|1] "" Vector__XXX
 SG_ CLOCK_YEAR_TGU : 0|6@1+ (1,2000) [2016|2063] "" Vector__XXX
 SG_ CLOCK_MONTH_TGU : 8|4@1+ (1,0) [0|12] "" Vector__XXX
 SG_ CLOCK_MIN_TGU : 32|6@1+ (1,0) [0|59] "Minute" Vector__XXX
 SG_ CLOCK_HOUR_TGU : 24|5@1+ (1,0) [0|23] "Hour" Vector__XXX
 SG_ CLOCK_FORMAT_TGU : 12|1@1+ (1,0) [0|1] "" Vector__XXX
 SG_ CLOCK_DATE_TGU : 16|5@1+ (1,0) [0|31] "" Vector__XXX

BO_ 339 TGU2_100: 8 SMART_CORE
 SG_ TGU_CHARGINGENDTIME_FORMAT m1 : 3|1@1+ (1,0) [-1|0] "" Vector__XXX
 SG_ TGU_CHARGINGSTARTTIME_FORMAT m0 : 4|1@1+ (1,0) [0|1] "" Vector__XXX
 SG_ TGU_CHRG_STRT_TIME_HOURS m0 : 5|5@1+ (1,0) [0|24] "" Vector__XXX
 SG_ TGU_ENERGYCONS m0 : 48|8@1+ (1,0) [0|255] "" Vector__XXX
 SG_ TGU_EV_CHRG_PARAM_INDEX M : 0|2@1+ (1,0) [0|3] "" Vector__XXX
 SG_ TGU_CHARGINGSTARTTIME_DATE m0 : 16|16@1+ (1,0) [0|31] "" Vector__XXX
 SG_ TGU_CHRG_START_TIME_MIN m0 : 10|6@1+ (1,0) [0|59] "" Vector__XXX
 SG_ TGU_CHARGINGSTARTTIME_MONTH m0 : 32|8@1+ (1,0) [0|12] "" Vector__XXX
 SG_ TGU_CHARGINGSTARTTIME_YEAR m0 : 40|6@1+ (1,2000) [2016|2063] "" Vector__XXX
 SG_ TGU_CHARGINGENDTIME_DATE m1 : 16|16@1+ (1,0) [0|31] "" Vector__XXX
 SG_ TGU_CHARGINGENDTIME_HOURS m1 : 5|5@1+ (1,0) [0|23] "" Vector__XXX
 SG_ TGU_CHARGINGENDTIME_MIN m1 : 10|6@1+ (1,0) [0|59] "" Vector__XXX
 SG_ TGU_CHARGINGENDTIME_MONTH m1 : 32|8@1+ (1,0) [0|12] "" Vector__XXX
 SG_ TGU_CHRGING_DURATION_MIN m1 : 56|6@1+ (1,0) [0|59] "" Vector__XXX
 SG_ TGU_CHARGINGENDTIME_YEAR m1 : 40|6@1+ (1,2000) [2016|2063] "" Vector__XXX
 SG_ TGU_CHRGING_DURATION_HOURS m1 : 48|5@1+ (1,0) [0|24] "" Vector__XXX

BO_ 338 TGU1_100: 8 SMART_CORE
 SG_ TGU_TRIPSTARTTIME_FORMAT m3 : 4|1@1+ (1,0) [0|1] "" Vector__XXX
 SG_ TGU_TRIPENDTIME_FORMAT m4 : 4|1@1+ (1,0) [0|1] "" Vector__XXX
 SG_ TGU_TRIPSTARTTIME_YEAR m3 : 40|6@1+ (1,2000) [2016|2063] "" Vector__XXX
 SG_ TGU_TRIPSTARTTIME_MIN m3 : 10|6@1+ (1,0) [0|59] "" Vector__XXX
 SG_ TGU_TRIP_START_TIME_HOURS m3 : 5|5@1+ (1,0) [0|24] "" Vector__XXX
 SG_ TGU_TRIPENDTIME_YEAR m4 : 40|6@1+ (1,2000) [2016|2063] "" Vector__XXX
 SG_ TGU_TRIPENDTIME_MONTH m4 : 32|8@1+ (1,0) [0|12] "" Vector__XXX
 SG_ TGU_TRIPENDTIME_MIN m4 : 10|6@1+ (1,0) [0|59] "" Vector__XXX
 SG_ TGU_TRIPENDTIME_DATE m4 : 16|16@1+ (1,0) [0|31] "" Vector__XXX
 SG_ TGU_TRIPEFFICIENCY m1 : 6|2@1+ (1,0) [0|3] "" Vector__XXX
 SG_ TGU_TRIPAVGVEHICLESPEED m1 : 24|8@1+ (1,0) [0|255] "" Vector__XXX
 SG_ TGU_TRIP_TOP_SPEED m1 : 32|8@1+ (1,0) [0|254] "" Vector__XXX
 SG_ TGU_TRIP_START_TIME_MONTH m3 : 32|8@1+ (1,0) [0|12] "" Vector__XXX
 SG_ TGU_TRIP_START_TIME_DATE m3 : 16|16@1+ (1,0) [0|31] "" Vector__XXX
 SG_ TGU_TRIP_END_TIME_HOURS m4 : 5|5@1+ (1,0) [0|24] "" Vector__XXX
 SG_ TGU_TRIP_DURATION_MIN m4 : 51|6@1- (1,0) [0|59] "" Vector__XXX
 SG_ TGU_TRIP_DURATION_HOURS m4 : 46|5@1+ (1,0) [0|24] "" Vector__XXX
 SG_ TGU_TRIP_DISTANCE m1 : 8|16@1+ (1,0) [0|650] "" Vector__XXX
 SG_ TGU_TREES_SAVED m0 : 40|16@1+ (1,0) [0|9999] "" Vector__XXX
 SG_ TGU_CO2 m2 : 8|32@1+ (1,0) [0|999999] "" Vector__XXX
 SG_ TGU_EV_KILOMETERS m0 : 8|32@1+ (1,0) [0|999999] "" Vector__XXX
 SG_ TGU_FRESHDATAFLAG m0 : 4|1@1+ (1,0) [0|1] "" Vector__XXX
 SG_ TGU_EV_PARAM_INDEX M : 0|3@1+ (1,0) [-4|3] "" Vector__XXX

BO_ 1761 TGU_NM_TEST: 8 SMART_CORE
 SG_ NM_VIN_CHECK_STS_TGU : 34|1@1+ (1,0) [0|1] "" Vector__XXX
 SG_ NM_VIN_DTC_STS_TGU : 3|2@1+ (1,0) [0|3] "" Vector__XXX
 SG_ NM_VC_DTC_STS_TGU : 1|2@1+ (1,0) [0|3] "" Vector__XXX
 SG_ NM_MCF_DTC_STS_TGU : 32|2@1+ (1,0) [0|3] "" Vector__XXX
 SG_ NM_VBATT_TGU : 16|8@1+ (0.1,0) [0|25] "Volt" Vector__XXX
 SG_ NM_UV_STS_TGU : 14|1@1+ (1,0) [0|1] "" Vector__XXX
 SG_ NM_SW_VER_TGU : 24|4@1+ (1,0) [0|15] "" Vector__XXX
 SG_ NM_STS_IGN_TGU : 0|1@1+ (1,0) [0|1] "" Vector__XXX
 SG_ NM_SCF_DTC_STS_TGU : 5|2@1+ (1,0) [0|3] "" Vector__XXX
 SG_ NM_OV_STS_TGU : 15|1@1+ (1,0) [0|1] "" Vector__XXX
 SG_ NM_NA_DTC_STS_TGU : 12|2@1+ (1,0) [0|3] "" Vector__XXX
 SG_ NM_MTO_DTC_STS_TGU : 10|2@1+ (1,0) [0|3] "" Vector__XXX
 SG_ NM_FC_DTC_STS_TGU : 8|2@1+ (1,0) [0|3] "" Vector__XXX
 SG_ NM_ACTIVE_STS_TGU : 28|4@1+ (1,0) [0|15] "" Vector__XXX

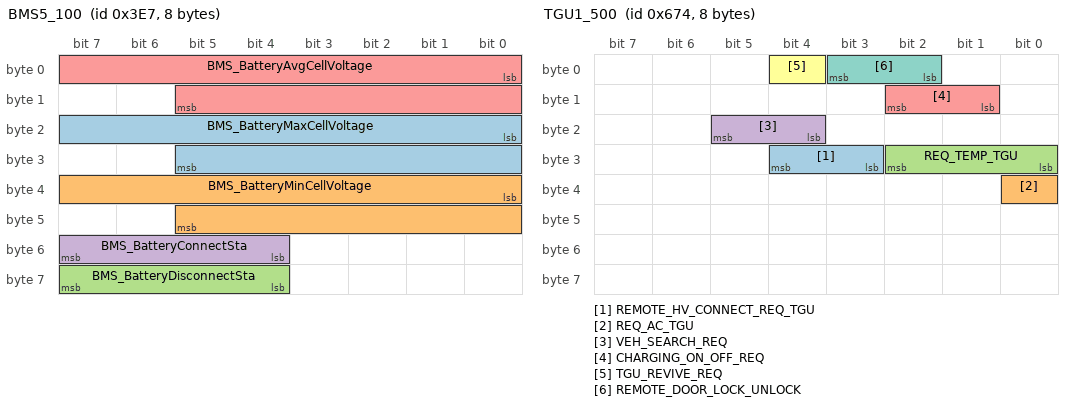
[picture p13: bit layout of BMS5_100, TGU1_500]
BO_ 999 BMS5_100: 8 Vector__XXX
 SG_ BMS_BatteryMaxCellVoltage : 16|14@1+ (1,0) [0|5000] "mV"  SMART_CORE
 SG_ BMS_BatteryMinCellVoltage : 32|14@1+ (1,0) [0|5000] "mV"  SMART_CORE
 SG_ BMS_BatteryDisconnectSta : 60|4@1+ (1,0) [0|15] ""  SMART_CORE
 SG_ BMS_BatteryConnectSta : 52|4@1+ (1,0) [0|15] "NA"  SMART_CORE
 SG_ BMS_BatteryAvgCellVoltage : 0|14@1+ (1,0) [0|5000] "mV"  SMART_CORE

BO_ 1000 BMS4_100: 8 Vector__XXX
 SG_ BMS_BatteryPackSOH : 32|10@1+ (0.1,0) [0|100] "%"  SMART_CORE
 SG_ BMS_BatteryPackRSOC : 16|10@1+ (0.1,0) [0|100] "%"  SMART_CORE
 SG_ BMS_BatteryPackASOC : 0|10@1+ (0.1,0) [0|100] "%"  SMART_CORE

BO_ 2005 TGU_DIAG_REQ: 8 Vector__XXX
 SG_ DIAG_TGU_REQ_DATA : 0|64@1+ (1,0) [0|1.8446744074E+019] ""  SMART_CORE

BO_ 2013 TGU_DIAG_RES: 8 SMART_CORE
 SG_ DIAG_TGU_RES_DATA : 0|64@1+ (1,0) [0|1.8446744074E+019] "" Vector__XXX

BO_ 1652 TGU1_500: 8 SMART_CORE
 SG_ REMOTE_HV_CONNECT_REQ_TGU : 27|2@1+ (1,0) [0|3] "" Vector__XXX
 SG_ REQ_AC_TGU : 32|1@1+ (1,0) [0|1] "" Vector__XXX
 SG_ REQ_TEMP_TGU : 24|3@1+ (1,0) [0|7] "" Vector__XXX
 SG_ VEH_SEARCH_REQ : 20|2@1+ (1,0) [0|3] "" Vector__XXX
 SG_ CHARGING_ON_OFF_REQ : 9|2@1+ (1,0) [0|3] "" Vector__XXX
 SG_ TGU_REVIVE_REQ : 4|1@1+ (1,0) [0|1] "" Vector__XXX
 SG_ REMOTE_DOOR_LOCK_UNLOCK : 2|2@1+ (1,0) [0|3] "" Vector__XXX

BO_ 374 AMT5_20: 8 Vector__XXX
 SG_ ENGINE_STOP_AMT : 14|1@1+ (1,0) [0|1] ""  SMART_CORE
 SG_ TGS_MODE_AMT : 10|2@1+ (1,0) [0|3] ""  SMART_CORE
 SG_ TCU_SHIFT_MODE : 8|2@1+ (1,0) [0|3] ""  SMART_CORE
 SG_ GEAR_ACTUAL_AMT : 0|4@1+ (1,0) [0|15] ""  SMART_CORE

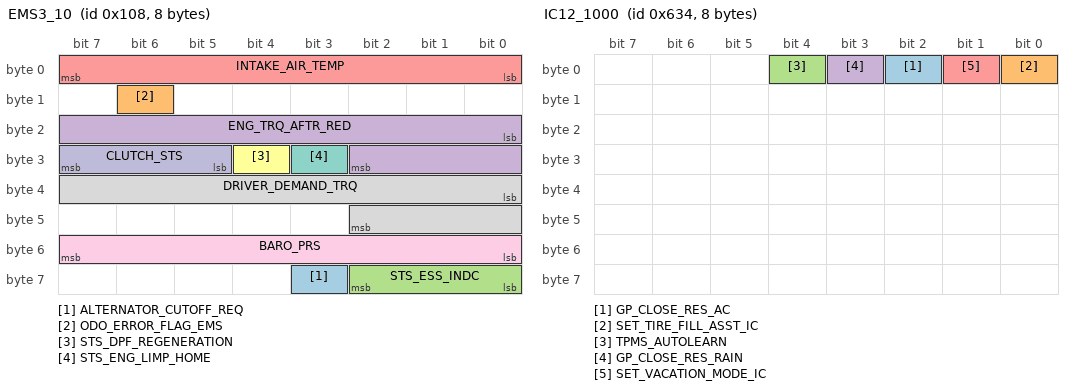
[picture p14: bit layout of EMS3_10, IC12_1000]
BO_ 264 EMS3_10: 8 Vector__XXX
 SG_ ALTERNATOR_CUTOFF_REQ : 59|1@1+ (1,0) [0|1] ""  SMART_CORE
 SG_ ODO_ERROR_FLAG_EMS : 14|1@1+ (1,0) [0|1] ""  SMART_CORE
 SG_ STS_ESS_INDC : 56|3@1+ (1,0) [0|7] ""  SMART_CORE
 SG_ ENG_TRQ_AFTR_RED : 16|11@1+ (1,-1024) [-1024|1022] "Nm"  SMART_CORE
 SG_ INTAKE_AIR_TEMP : 0|8@1+ (1,-40) [-40|214] "DegC"  SMART_CORE
 SG_ STS_DPF_REGENERATION : 28|1@1+ (1,0) [0|1] ""  SMART_CORE
 SG_ STS_ENG_LIMP_HOME : 27|1@1+ (1,0) [0|1] ""  SMART_CORE
 SG_ DRIVER_DEMAND_TRQ : 32|11@1+ (1,-1024) [-1024|1022] "Nm"  SMART_CORE
 SG_ BARO_PRS : 48|8@1+ (1,0) [0|254] "Kpa"  SMART_CORE
 SG_ CLUTCH_STS : 29|3@1+ (1,0) [0|7] ""  SMART_CORE

BO_ 1919 MGM_DIAG_RES: 8 Vector__XXX
 SG_ DIAG_MGM_RES_DATA : 0|64@1+ (1,0) [0|1.8446744074E+019] ""  SMART_CORE

BO_ 1911 MGM_DIAG_REQ: 8 SMART_CORE
 SG_ DIAG_MGM_REQ_DATA : 0|64@1+ (1,0) [0|1.8446744074E+019] ""  SMART_CORE

BO_ 1980 LDC_DIAG_RES: 8 Vector__XXX
 SG_ DIAG_LDC_RES_DATA : 0|64@1+ (1,0) [0|1.8446744074E+019] "NA"  SMART_CORE

BO_ 2008 MCU_DIAG_RES: 8 Vector__XXX
 SG_ DIAG_MCU_RES_DATA : 0|64@1+ (1,0) [0|0] ""  SMART_CORE

BO_ 579 VCU_EVCAN_WAKEUP: 8 Vector__XXX
 SG_ VCU_EVCAN_WAKEUPREASONRESERVED2 : 24|40@1+ (1,0) [0|5] "NA"  SMART_CORE
 SG_ VCU_EVCAN_WAKEUPREASONRESERVED1 : 0|8@1+ (1,0) [0|5] "NA"  SMART_CORE
 SG_ VCU_EVCAN_WAKEUPREASON : 8|16@1+ (1,0) [0|5] "NA"  SMART_CORE

BO_ 936 VCU_EVCAN_SLEEP: 8 Vector__XXX
 SG_ VCU_EVCAN_SLEEPRESERVED : 0|64@1+ (1,0) [0|0] "NA"  SMART_CORE

BO_ 1933 ETL_DIAG_RES: 8 Vector__XXX
 SG_ DIAG_ETL_RES_DATA : 0|64@1+ (1,0) [0|1.8446744074E+019] "NA"  SMART_CORE

BO_ 1981 OBC_DIAG_RES: 8 Vector__XXX
 SG_ DIAG_OBC_RES_DATA : 0|64@1+ (1,0) [0|1.8446744074E+019] "NA"  SMART_CORE

BO_ 1976 BMS_DIAG_RES: 8 Vector__XXX
 SG_ DIAG_BMS_RES_DATA : 0|64@1+ (1,0) [0|1.8446744074E+019] "NA"  SMART_CORE

BO_ 1972 LDC_DIAG_REQ: 8 SMART_CORE
 SG_ DIAG_LDC_REQ_DATA : 0|64@1+ (1,0) [0|1.8446744074E+019] "NA" Vector__XXX

BO_ 1925 ETL_DIAG_REQ: 8 SMART_CORE
 SG_ DIAG_ETL_REQ_DATA : 0|64@1+ (1,0) [0|1.8446744074E+019] "NA" Vector__XXX

BO_ 1973 OBC_DIAG_REQ: 8 SMART_CORE
 SG_ DIAG_OBC_REQ_DATA : 0|64@1+ (1,0) [0|1.8446744074E+019] "NA" Vector__XXX

BO_ 2000 MCU_DIAG_REQ: 8 SMART_CORE
 SG_ DIAG_MCU_REQ_DATA : 0|64@1+ (1,0) [0|1.8446744074E+019] "NA" Vector__XXX

BO_ 1968 BMS_DIAG_REQ: 8 SMART_CORE
 SG_ DIAG_BMS_REQ_DATA : 0|64@1+ (1,0) [0|1.8446744074E+019] "NA" Vector__XXX

BO_ 336 BMS18_50: 8 Vector__XXX
 SG_ BMS_TotalCycle_Time : 48|16@1+ (1,0) [0|65535] "Min"  SMART_CORE
 SG_ BMS_DischargeCycle_Time : 32|16@1+ (1,0) [0|65535] "Min"  SMART_CORE
 SG_ BMS_ChargeCycle_Time : 16|16@1+ (1,0) [0|65535] "Min"  SMART_CORE
 SG_ BMS_CycleNumber : 0|16@1+ (1,0) [0|65534] ""  SMART_CORE

BO_ 285 BMS16_10: 8 Vector__XXX
 SG_ BMS_BattPack_PwrLimitErr_Common : 39|1@1+ (1,0) [0|1] ""  SMART_CORE
 SG_ BMS_Bat_I_OvrExtCurr_Flt_Dischrg : 41|1@1+ (1,0) [0|1] ""  SMART_CORE
 SG_ BMS_Bat_I_OverCurr_Flt_Discharge : 42|1@1+ (1,0) [0|1] ""  SMART_CORE
 SG_ BMS_BattOverVolt_Cutoff_Charge : 6|1@1+ (1,0) [0|1] ""  SMART_CORE
 SG_ BMS_ClntInlet_High_Temp_Charge : 15|1@1+ (1,0) [0|1] ""  SMART_CORE
 SG_ BMS_ClntInlet_Low_Temp_Charge : 14|1@1+ (1,0) [0|1] ""  SMART_CORE
 SG_ BMS_ClntOutlet_Low_Temp_Charge : 22|1@1+ (1,0) [0|1] ""  SMART_CORE
 SG_ BMS_Clntoutlet_High_Temp_Charge : 23|1@1+ (1,0) [0|1] ""  SMART_CORE
 SG_ BMS_BattOver_Temp_Cutoff_common : 31|1@1+ (1,0) [0|1] ""  SMART_CORE
 SG_ BMS_BattUnder_Temp_Cutoff_common : 30|1@1+ (1,0) [0|1] ""  SMART_CORE
 SG_ BMS_ClntSen_Thres_Fault_Charge : 21|1@1+ (1,0) [0|1] ""  SMART_CORE
 SG_ BMS_ReverseCurrDetect_Charge : 20|1@1+ (1,0) [0|1] ""  SMART_CORE
 SG_ BMS_PLP_Stop_Charge : 19|1@1+ (1,0) [0|1] ""  SMART_CORE
 SG_ BMS_CellUnderVolt_Cutoff_Common : 29|1@1+ (1,0) [0|1] ""  SMART_CORE
 SG_ BMS_BattUnderVolt_Cutoff_Common : 28|1@1+ (1,0) [0|1] ""  SMART_CORE
 SG_ BMS_ModuleOverTemp_Cutoff_Common : 27|1@1+ (1,0) [0|1] ""  SMART_CORE
 SG_ BMS_MdleUnderTemp_Cutoff_Common : 26|1@1+ (1,0) [0|1] ""  SMART_CORE
 SG_ BMS_ShortCircuitCurr_Flt_Common : 38|1@1+ (1,0) [0|1] ""  SMART_CORE
 SG_ BMS_Sensor_Failure_Common : 37|1@1+ (1,0) [0|1] ""  SMART_CORE
 SG_ BMS_Ibatt_392_25sec_Common : 36|1@1+ (1,0) [0|1] ""  SMART_CORE
 SG_ BMS_PilotLine_Detect_Common : 35|1@1+ (1,0) [0|1] ""  SMART_CORE
 SG_ BMS_Revive_Common : 34|1@1+ (1,0) [0|1] ""  SMART_CORE
 SG_ BMS_HeaterSys_Flt_Common : 47|1@1+ (1,0) [0|1] ""  SMART_CORE
 SG_ BMS_Clnt_TempSens_Flt_Common : 46|1@1+ (1,0) [0|1] ""  SMART_CORE
 SG_ BMS_Heater_Flt_Common : 45|1@1+ (1,0) [0|1] ""  SMART_CORE
 SG_ BMS_IsoFLt_Red_Discharge : 44|1@1+ (1,0) [0|1] ""  SMART_CORE
 SG_ BMS_LowSOC_Cutoff_Discharge : 43|1@1+ (1,0) [0|1] ""  SMART_CORE
 SG_ BMS_Bat_I_ExtCurr_Flt_Dischrg : 40|1@1+ (1,0) [0|1] ""  SMART_CORE
 SG_ BMS_MTM_ActvLimit_Common : 33|1@1+ (1,0) [0|1] ""  SMART_CORE
 SG_ BMS_ClntSys_Flt_Common : 32|1@1+ (1,0) [0|1] ""  SMART_CORE
 SG_ BMS_Pump_DryRun_Err_Common : 25|1@1+ (1,0) [0|1] ""  SMART_CORE
 SG_ BMS_CrashDtct_P_F_Open_Common : 24|1@1+ (1,0) [0|1] ""  SMART_CORE
 SG_ BMS_HVIL_Err_Dischrg : 55|1@1+ (1,0) [0|1] ""  SMART_CORE
 SG_ BMS_No_Cntctr_Close : 54|1@1+ (1,0) [0|1] ""  SMART_CORE
 SG_ BMS_CntctrOpen_Rqst_VCU_Dischrg : 52|1@1+ (1,0) [0|1] ""  SMART_CORE
 SG_ BMS_CntctrOpen_Rqst_VCU_Chrg : 53|1@1+ (1,0) [0|1] ""  SMART_CORE
 SG_ BMS_InitCntctrOpen_Dischrg : 51|1@1+ (1,0) [0|1] ""  SMART_CORE
 SG_ BMS_InitCntctrOpen_Charge : 50|1@1+ (1,0) [0|1] ""  SMART_CORE
 SG_ BMS_FSBIM_bAcvDrtdMode : 49|1@1+ (1,0) [0|1] ""  SMART_CORE
 SG_ BMS_FSPLP_bAcvDrtdMode : 48|1@1+ (1,0) [0|1] ""  SMART_CORE
 SG_ BMS_ILC_AcvDrtdCdn : 60|1@1+ (1,0) [0|1] ""  SMART_CORE
 SG_ BMS_IDMStsIsInErr_Yellow : 61|1@1+ (1,0) [0|1] ""  SMART_CORE
 SG_ BMS_FSPLP_bAcvPackOverUDrtd : 63|1@1+ (1,0) [0|1] ""  SMART_CORE
 SG_ BMS_BIM_bAcvHighRateDchaDrdt2 : 59|1@1+ (1,0) [0|1] ""  SMART_CORE
 SG_ BMS_FSPLP_bAcvPackUnderUDrtd : 62|1@1+ (1,0) [0|1] ""  SMART_CORE
 SG_ BMS_BIMbAcvReqDrtdMode : 58|1@1+ (1,0) [0|1] ""  SMART_CORE
 SG_ BMS_BTFD_bAcvReqDrtdMode : 57|1@1+ (1,0) [0|1] ""  SMART_CORE
 SG_ BMS_CUM_bAcvOwDrtd : 56|1@1+ (1,0) [0|1] ""  SMART_CORE
 SG_ BMS_CellOverVolt_Cutoff_Charge : 7|1@1+ (1,0) [0|1] ""  SMART_CORE
 SG_ BMS_Reason_HV_Disconnected : 16|3@1+ (1,0) [0|7] ""  SMART_CORE
 SG_ BMS_Reason_HV_Disconnect_Request : 8|6@1+ (1,0) [0|28] ""  SMART_CORE
 SG_ BMS_Reason_Derating : 0|6@1+ (1,0) [0|30] ""  SMART_CORE

BO_ 1954 ESCL_DIAG_REQ: 8 SMART_CORE
 SG_ DIAG_ESCL_REQ_DATA : 0|64@1+ (1,0) [0|1.84467440737096E+019] "" Vector__XXX

BO_ 1962 ESCL_DIAG_RES: 8 Vector__XXX
 SG_ DIAG_ESCL_RES_DATA : 0|64@1+ (1,0) [0|1.84467440737096E+019] ""  SMART_CORE

BO_ 920 HLCU1_100: 8 Vector__XXX
 SG_ STS_HIGHBEAM_BOOSTER : 0|1@1+ (1,0) [0|1] ""  SMART_CORE
 SG_ HEADLAMP_AUTO_LEVEL : 1|1@1+ (1,0) [0|1] ""  SMART_CORE

BO_ 921 HLCU2_100: 8 Vector__XXX
 SG_ STS_HIGHBEAM_BOOSTER_1 : 0|1@1+ (1,0) [0|1] ""  SMART_CORE

BO_ 667 HLCU2_NSM: 8 Vector__XXX
 SG_ RESERVED_HLCU : 0|64@1+ (1,0) [0|0] ""  SMART_CORE

BO_ 654 IS_NSM: 8 SMART_CORE
 SG_ RESERVED_IS : 0|64@1+ (1,0) [0|0] "" Vector__XXX

BO_ 662 APA_NSM: 8 Vector__XXX
 SG_ RESERVED_APA : 0|64@1+ (1,0) [0|0] ""  SMART_CORE

BO_ 771 FATC2_200: 8 Vector__XXX
 SG_ PASSIVE_VENT_FATC_STS : 36|1@1+ (1,0) [0|1] ""  SMART_CORE
 SG_ DISP_AMBT_TEMP_FATC : 0|8@1+ (1,-40) [-40|215] "deg C."  SMART_CORE

BO_ 809 WLC_NSM: 8 Vector__XXX
 SG_ RESERVED_WLC : 0|64@1+ (1,0) [0|0] ""  SMART_CORE

BO_ 1711 WLC3_2000: 8 Vector__XXX
 SG_ FOD_ALERT : 8|1@1+ (1,0) [0|1] ""  SMART_CORE
 SG_ TIME_TO_CHARGE : 0|8@1+ (1,0) [0|255] "min"  SMART_CORE

BO_ 768 FATC1_200: 8 Vector__XXX
 SG_ STS_IONIZER : 60|1@1+ (1,0) [0|1] ""  SMART_CORE
 SG_ AC_SWT_STS : 48|1@1+ (1,0) [0|1] ""  SMART_CORE
 SG_ AUTO_RECIRC : 46|1@1+ (1,0) [0|1] ""  SMART_CORE
 SG_ AUTO_DEFROST : 63|1@1+ (1,0) [0|1] ""  SMART_CORE
 SG_ STS_REAR_AC : 51|1@1+ (1,0) [0|1] ""  SMART_CORE
 SG_ MEM_DISP : 8|4@1+ (1,0) [0|15] ""  SMART_CORE
 SG_ FRONT_LEFT_SET_TEMP : 32|8@1+ (0.5,-40) [-40|87.5] "Deg C"  SMART_CORE
 SG_ FRESH_RECIRC : 54|2@1+ (1,0) [0|3] ""  SMART_CORE
 SG_ FATC_ECON : 44|2@1+ (1,0) [0|3] ""  SMART_CORE
 SG_ FATC_AUTO : 40|2@1+ (1,0) [0|3] ""  SMART_CORE
 SG_ FRONT_RIGHT_SET_TEMP : 24|8@1+ (0.5,-40) [-40|87] "Deg C"  SMART_CORE
 SG_ DISP_OFF : 56|2@1+ (1,0) [0|3] ""  SMART_CORE
 SG_ DISP_MODE : 16|4@1+ (1,0) [0|15] ""  SMART_CORE
 SG_ DISP_DUAL : 42|2@1+ (1,0) [0|3] ""  SMART_CORE
 SG_ DISP_AC : 49|2@1+ (1,0) [0|3] ""  SMART_CORE
 SG_ INCAR_TEMP : 0|8@1+ (1,-40) [-40|214] "Deg C"  SMART_CORE
 SG_ DISP_BLOWER : 20|4@1+ (1,0) [0|15] ""  SMART_CORE

BO_ 1588 IC12_1000: 8 SMART_CORE
 SG_ GP_CLOSE_RES_AC : 2|1@1+ (1,0) [0|1] "" Vector__XXX
 SG_ SET_TIRE_FILL_ASST_IC : 0|1@1+ (1,0) [0|1] "" Vector__XXX
 SG_ TPMS_AUTOLEARN : 4|1@1+ (1,0) [0|1] "" Vector__XXX
 SG_ GP_CLOSE_RES_RAIN : 3|1@1+ (1,0) [0|1] "" Vector__XXX
 SG_ SET_VACATION_MODE_IC : 1|1@1+ (1,0) [0|1] "" Vector__XXX

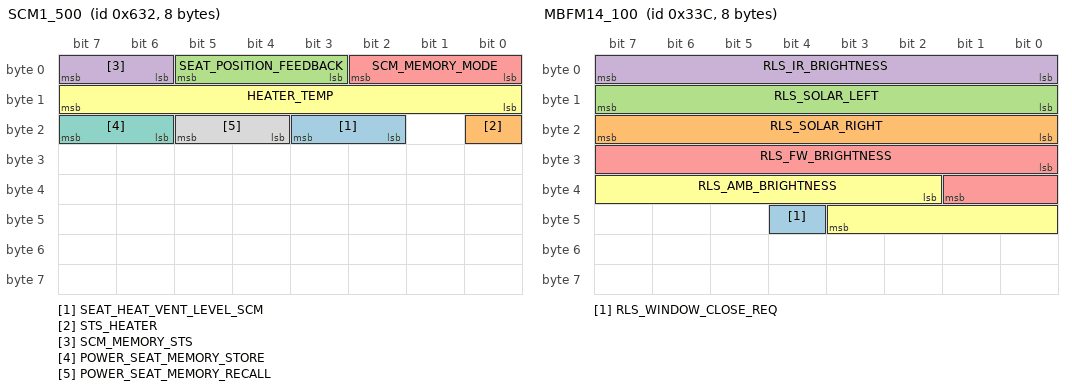
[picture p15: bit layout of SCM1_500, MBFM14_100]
BO_ 1586 SCM1_500: 8 Vector__XXX
 SG_ SEAT_HEAT_VENT_LEVEL_SCM : 18|2@1+ (1,0) [0|3] ""  SMART_CORE
 SG_ STS_HEATER : 16|1@1+ (1,0) [0|1] ""  SMART_CORE
 SG_ SEAT_POSITION_FEEDBACK : 3|3@1+ (1,0) [0|7] ""  SMART_CORE
 SG_ SCM_MEMORY_STS : 6|2@1+ (1,0) [0|3] ""  SMART_CORE
 SG_ SCM_MEMORY_MODE : 0|3@1+ (1,0) [0|7] ""  SMART_CORE
 SG_ HEATER_TEMP : 8|8@1+ (1,-40) [-40|214] "deg C."  SMART_CORE
 SG_ POWER_SEAT_MEMORY_STORE : 22|2@1+ (1,0) [0|3] ""  SMART_CORE
 SG_ POWER_SEAT_MEMORY_RECALL : 20|2@1+ (1,0) [0|3] ""  SMART_CORE

BO_ 828 MBFM14_100: 8 Vector__XXX
 SG_ RLS_WINDOW_CLOSE_REQ : 44|1@1+ (1,0) [0|1] ""  SMART_CORE
 SG_ RLS_SOLAR_RIGHT : 16|8@1+ (5,0) [0|1200] "w/m2"  SMART_CORE
 SG_ RLS_SOLAR_LEFT : 8|8@1+ (5,0) [0|1200] "w/m2"  SMART_CORE
 SG_ RLS_IR_BRIGHTNESS : 0|8@1+ (400,0) [0|101200] "Lux"  SMART_CORE
 SG_ RLS_FW_BRIGHTNESS : 24|10@1+ (6,0) [0|6126] "Lux"  SMART_CORE
 SG_ RLS_AMB_BRIGHTNESS : 34|10@1+ (20,0) [0|20460] "Lux"  SMART_CORE

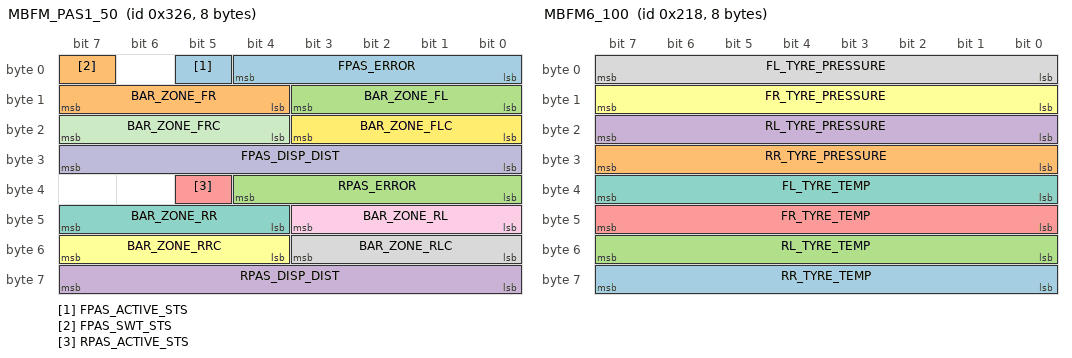
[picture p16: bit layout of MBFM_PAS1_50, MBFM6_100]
BO_ 806 MBFM_PAS1_50: 8 Vector__XXX
 SG_ FPAS_ACTIVE_STS : 5|1@1+ (1,0) [0|1] ""  SMART_CORE
 SG_ FPAS_SWT_STS : 7|1@1+ (1,0) [0|0] "NA"  SMART_CORE
 SG_ RPAS_ERROR : 32|5@1+ (1,0) [0|31] ""  SMART_CORE
 SG_ RPAS_DISP_DIST : 56|8@1+ (1,0) [0|255] ""  SMART_CORE
 SG_ RPAS_ACTIVE_STS : 37|1@1+ (1,0) [0|1] ""  SMART_CORE
 SG_ BAR_ZONE_RRC : 52|4@1+ (1,0) [0|15] ""  SMART_CORE
 SG_ BAR_ZONE_RR : 44|4@1+ (1,0) [0|15] ""  SMART_CORE
 SG_ BAR_ZONE_RLC : 48|4@1+ (1,0) [0|15] ""  SMART_CORE
 SG_ BAR_ZONE_RL : 40|4@1+ (1,0) [0|15] ""  SMART_CORE
 SG_ FPAS_DISP_DIST : 24|8@1+ (1,0) [0|255] ""  SMART_CORE
 SG_ BAR_ZONE_FRC : 20|4@1+ (1,0) [0|15] ""  SMART_CORE
 SG_ BAR_ZONE_FLC : 16|4@1+ (1,0) [0|15] ""  SMART_CORE
 SG_ FPAS_ERROR : 0|5@1+ (1,0) [0|31] ""  SMART_CORE
 SG_ BAR_ZONE_FR : 12|4@1+ (1,0) [0|15] ""  SMART_CORE
 SG_ BAR_ZONE_FL : 8|4@1+ (1,0) [0|15] ""  SMART_CORE

BO_ 2029 MBFM_DIAG_RES: 8 Vector__XXX
 SG_ DIAG_MBFM_RES_DATA : 0|64@1+ (1,0) [0|1.8446744074E+019] ""  SMART_CORE

BO_ 536 MBFM6_100: 8 Vector__XXX
 SG_ RR_TYRE_TEMP : 56|8@1+ (1,-40) [-40|214] "deg C"  SMART_CORE
 SG_ RR_TYRE_PRESSURE : 24|8@1+ (0.25,0) [0|63.5] "Psi"  SMART_CORE
 SG_ RL_TYRE_TEMP : 48|8@1+ (1,-40) [-40|214] "deg C"  SMART_CORE
 SG_ RL_TYRE_PRESSURE : 16|8@1+ (0.25,0) [0|63.5] "Psi"  SMART_CORE
 SG_ FR_TYRE_TEMP : 40|8@1+ (1,-40) [-40|214] "deg C"  SMART_CORE
 SG_ FR_TYRE_PRESSURE : 8|8@1+ (0.25,0) [0|63.5] "Psi"  SMART_CORE
 SG_ FL_TYRE_TEMP : 32|8@1+ (1,-40) [-40|214] "deg C"  SMART_CORE
 SG_ FL_TYRE_PRESSURE : 0|8@1+ (0.25,0) [0|63.5] "Psi"  SMART_CORE

BO_ 1056 CCM3_200: 8 Vector__XXX
 SG_ CABIN_HVAC_STS_CCM : 34|2@1+ (1,0) [0|3] ""  SMART_CORE
 SG_ HEATER_INPUT_DC_VOLT : 48|16@1+ (1,0) [0|510] "V"  SMART_CORE
 SG_ CABIN_HEATER_POWER_CONSUMPTION : 24|8@1+ (50,0) [0|10000] "watts"  SMART_CORE
 SG_ AC_OFF_CODE : 0|8@1+ (1,0) [0|202] ""  SMART_CORE
 SG_ REMOTE_HVAC_STS_CCM : 32|2@1+ (1,0) [0|3] ""  SMART_CORE

BO_ 940 CCM_ACTIVE: 8 Vector__XXX
 SG_ RESERVED_CCM_ACTIVE : 0|64@1+ (1,0) [0|1.8446744074E+019] ""  SMART_CORE

BO_ 1001 BMS3_100: 8 Vector__XXX
 SG_ BMS_ChargeVoltageLimit : 48|14@1+ (0.1,0) [0|430] "V"  SMART_CORE
 SG_ BMS_ChargeCurrentLimit : 32|14@1+ (0.1,0) [0|400] "A"  SMART_CORE
 SG_ BMS_DischargeCurrentlimit : 0|14@1+ (0.1,0) [0|500] "A"  SMART_CORE

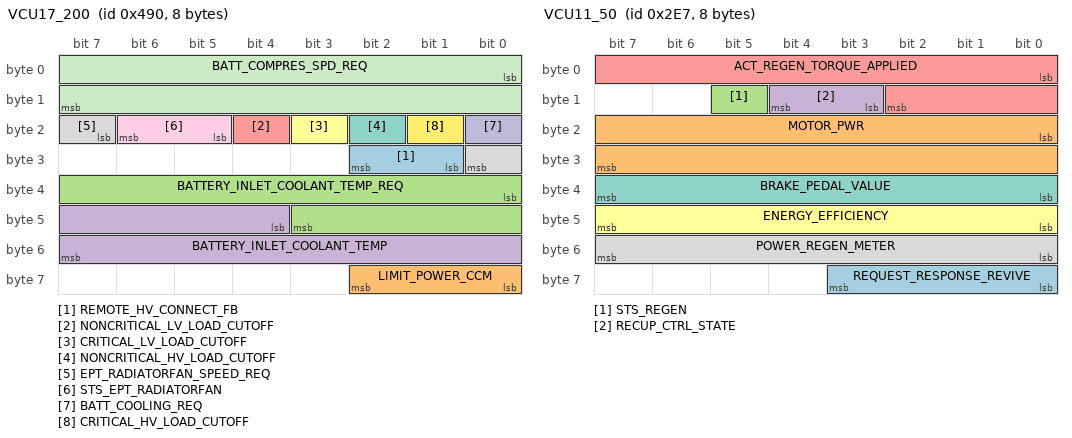
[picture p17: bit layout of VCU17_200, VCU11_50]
BO_ 1168 VCU17_200: 8 Vector__XXX
 SG_ REMOTE_HV_CONNECT_FB : 25|2@1+ (1,0) [0|3] ""  SMART_CORE
 SG_ LIMIT_POWER_CCM : 56|3@1+ (1,0) [0|7] ""  SMART_CORE
 SG_ BATTERY_INLET_COOLANT_TEMP_REQ : 32|12@1+ (0.1,-40) [-40|125] "Deg C"  SMART_CORE
 SG_ BATTERY_INLET_COOLANT_TEMP : 44|12@1+ (0.1,-40) [-40|125] "Deg C"  SMART_CORE
 SG_ NONCRITICAL_LV_LOAD_CUTOFF : 20|1@1+ (1,0) [0|1] ""  SMART_CORE
 SG_ CRITICAL_LV_LOAD_CUTOFF : 19|1@1+ (1,0) [0|1] ""  SMART_CORE
 SG_ NONCRITICAL_HV_LOAD_CUTOFF : 18|1@1+ (1,0) [0|1] ""  SMART_CORE
 SG_ EPT_RADIATORFAN_SPEED_REQ : 23|2@1+ (1,0) [0|3] "NA"  SMART_CORE
 SG_ STS_EPT_RADIATORFAN : 21|2@1+ (1,0) [0|3] "NA"  SMART_CORE
 SG_ BATT_COOLING_REQ : 16|1@1+ (1,0) [0|1] ""  SMART_CORE
 SG_ BATT_COMPRES_SPD_REQ : 0|16@1+ (1,0) [0|65534] "RPM"  SMART_CORE
 SG_ CRITICAL_HV_LOAD_CUTOFF : 17|1@1+ (1,0) [0|1] ""  SMART_CORE

BO_ 1865 CCM_DIAG_RES: 8 Vector__XXX
 SG_ DIAG_CCM_RES_DATA : 0|64@1+ (1,0) [0|1.8446744074E+019] ""  SMART_CORE

BO_ 1857 CCM_DIAG_REQ: 8 SMART_CORE
 SG_ DIAG_CCM_REQ_DATA : 0|64@1+ (1,0) [0|1.8446744074E+019] "" Vector__XXX

BO_ 965 IS_ACTIVE: 8 SMART_CORE
 SG_ RESERVED_2 : 0|64@1+ (1,0) [0|1.84467440737096E+019] "" Vector__XXX

BO_ 159 VCU_WAKEUP: 8 Vector__XXX
 SG_ VCU_WAKEUP_REASON : 8|16@1+ (1,0) [0|65535] ""  SMART_CORE

BO_ 942 VCU_SLEEP: 8 Vector__XXX
 SG_ RESERVED_2 : 0|64@1+ (1,0) [0|1.84467440737096E+019] ""  SMART_CORE

BO_ 943 VCU_ACTIVE: 8 Vector__XXX
 SG_ VCU_ACTIVE_RESERVED : 0|64@1+ (1,0) [0|0] "NA"  SMART_CORE

BO_ 954 FATC_ACTIVE: 8 Vector__XXX
 SG_ RESERVED_4 : 0|64@1+ (1,0) [0|1.8446744074E+019] ""  SMART_CORE

BO_ 564 IC_ACTIVE: 8 SMART_CORE
 SG_ RESERVED_2 : 0|64@1+ (1,0) [0|1.84467440737096E+019] "" Vector__XXX

BO_ 743 VCU11_50: 8 Vector__XXX
 SG_ REQUEST_RESPONSE_REVIVE : 56|4@1+ (1,0) [0|15] ""  SMART_CORE
 SG_ MOTOR_PWR : 16|16@1+ (5,-163840) [-163840|163835] "W"  SMART_CORE
 SG_ STS_REGEN : 13|1@1+ (1,0) [0|1] ""  SMART_CORE
 SG_ RECUP_CTRL_STATE : 11|2@1+ (1,0) [0|3] ""  SMART_CORE
 SG_ ACT_REGEN_TORQUE_APPLIED : 0|11@1+ (1,-1023) [-1023|1024] "Nm"  SMART_CORE
 SG_ ENERGY_EFFICIENCY : 40|8@1+ (0.1,0) [0|25] "km/kWh"  SMART_CORE
 SG_ BRAKE_PEDAL_VALUE : 32|8@1+ (1,0) [0|100] "%"  SMART_CORE
 SG_ POWER_REGEN_METER : 48|8@1+ (1,-100) [-100|100] "%"  SMART_CORE

BO_ 1416 IS6_500: 8 SMART_CORE
 SG_ WLC_ENABLE_SETTING_IS : 23|1@1+ (1,0) [0|1] "" Vector__XXX
 SG_ IRVM_AUTO_DIMMING_IS : 41|1@1+ (1,0) [0|1] "" Vector__XXX
 SG_ SUNROOF_WINDOW_OPEN_IS : 18|1@1+ (1,0) [0|1] "" Vector__XXX
 SG_ POWER_SEAT_RECALL_IS : 10|2@1+ (1,0) [0|3] "" Vector__XXX
 SG_ SET_AUTO_BRAKE_LAMP_IS : 24|2@1+ (1,0) [0|0] "" Vector__XXX
 SG_ DYNAMIC_TRAJ_LINES_RPAS : 22|1@1+ (1,0) [0|0] "" Vector__XXX
 SG_ DYNAMIC_TRAJ_LINE_FPAS_APA : 21|1@1+ (1,0) [0|0] "" Vector__XXX
 SG_ AUTO_TOPVIEW_ON_PAS_FRONT : 20|1@1+ (1,0) [0|0] "" Vector__XXX
 SG_ RVC_TTS : 17|1@1+ (1,0) [0|0] "" Vector__XXX
 SG_ SET_PARKBRAKE_AUTO_ACT_IS : 13|1@1+ (1,0) [0|0] "" Vector__XXX
 SG_ AVM_CONTROL_IS : 12|1@1+ (1,0) [0|0] "" Vector__XXX
 SG_ FOGLAMP_CONTROL_IS : 6|2@1+ (1,0) [0|0] "" Vector__XXX
 SG_ AUTO_TOPVIEW_ON_PAS_REAR : 19|1@1+ (1,0) [0|0] "" Vector__XXX
 SG_ SET_SERVICE_MODE_IS : 48|1@1+ (1,0) [0|0] "" Vector__XXX
 SG_ STS_PROFILE_LOCK_IS : 15|1@1+ (1,0) [0|1] "" Vector__XXX
 SG_ SET_SMART_ENERGY_IS : 32|2@1+ (1,0) [0|3] "" Vector__XXX
 SG_ HEADLAMP_CONTROL_IS : 4|2@1+ (1,0) [0|0] "" Vector__XXX
 SG_ AMBIENT_LIGHT_CONTROL_IS : 2|2@1+ (1,0) [0|0] "" Vector__XXX
 SG_ SUNROOF_CONTROL_IS : 0|2@1+ (1,0) [0|0] "" Vector__XXX
 SG_ PWR_WINDOW_CONTROL_IS : 26|2@1+ (1,0) [0|3] "" Vector__XXX
 SG_ DOOR_LOCK_CONTROL_IS : 8|2@1+ (1,0) [0|0] "" Vector__XXX
 SG_ SET_REMOTE_ENG_STARTSTOP : 40|1@1+ (1,0) [0|1] "" Vector__XXX
 SG_ SET_WALK_AWAY_LCK_IS : 16|1@1+ (1,0) [0|1] "" Vector__XXX
 SG_ SET_APPROACH_UNLCK_IS : 14|1@1+ (1,0) [0|1] "" Vector__XXX

BO_ 812 MCM_NSM: 8 SMART_CORE
 SG_ RESERVED_MCM : 0|64@1+ (1,0) [0|0] ""  SMART_CORE

BO_ 250 MCM_PKE_SP: 8 SMART_CORE
 SG_ IMMOVAL6 : 0|64@1+ (1,0) [0|1.8446744074] "" Vector__XXX

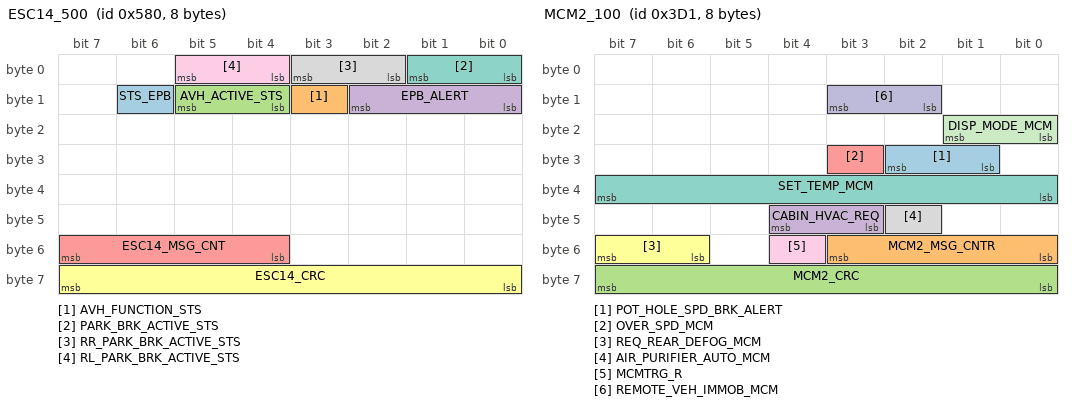
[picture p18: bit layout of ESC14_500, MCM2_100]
BO_ 1408 ESC14_500: 8 Vector__XXX
 SG_ STS_EPB : 14|1@1+ (1,0) [0|1] ""  SMART_CORE
 SG_ AVH_FUNCTION_STS : 11|1@1+ (1,0) [0|1] ""  SMART_CORE
 SG_ AVH_ACTIVE_STS : 12|2@1+ (1,0) [0|3] ""  SMART_CORE
 SG_ EPB_ALERT : 8|3@1+ (1,0) [0|7] ""  SMART_CORE
 SG_ ESC14_MSG_CNT : 52|4@1+ (1,0) [0|15] ""  SMART_CORE
 SG_ ESC14_CRC : 56|8@1+ (1,0) [0|255] ""  SMART_CORE
 SG_ PARK_BRK_ACTIVE_STS : 0|2@1+ (1,0) [0|3] ""  SMART_CORE
 SG_ RR_PARK_BRK_ACTIVE_STS : 2|2@1+ (1,0) [0|3] ""  SMART_CORE
 SG_ RL_PARK_BRK_ACTIVE_STS : 4|2@1+ (1,0) [0|3] ""  SMART_CORE

BO_ 977 MCM2_100: 8 SMART_CORE
 SG_ POT_HOLE_SPD_BRK_ALERT : 25|2@1+ (1,0) [0|3] "" Vector__XXX
 SG_ MCM2_MSG_CNTR : 48|4@1+ (1,0) [0|0] "" Vector__XXX
 SG_ MCM2_CRC : 56|8@1+ (1,0) [0|0] "" Vector__XXX
 SG_ CABIN_HVAC_REQ : 43|2@1+ (1,0) [0|3] "" Vector__XXX
 SG_ OVER_SPD_MCM : 27|1@1+ (1,0) [0|1] "" Vector__XXX
 SG_ REQ_REAR_DEFOG_MCM : 54|2@1+ (1,0) [0|3] "" Vector__XXX
 SG_ SET_TEMP_MCM : 32|8@1+ (0.5,-40) [-40|87] "" Vector__XXX
 SG_ AIR_PURIFIER_AUTO_MCM : 42|1@1+ (1,0) [0|0] "" Vector__XXX
 SG_ MCMTRG_R : 52|1@1+ (1,0) [0|1] "" Vector__XXX
 SG_ REMOTE_VEH_IMMOB_MCM : 10|2@1+ (1,0) [0|0] "" Vector__XXX
 SG_ DISP_MODE_MCM : 16|2@1+ (1,0) [0|3] "" Vector__XXX

BO_ 958 ESCL_ACTIVE: 8 Vector__XXX
 SG_ RESERVED_2 : 0|64@1+ (1,0) [0|1.84467440737096E+019] ""  SMART_CORE

BO_ 976 ESCL_NSM: 8 Vector__XXX
 SG_ RESERVED_ESCL : 0|64@1+ (1,0) [0|1.84467440737096E+019] ""  SMART_CORE

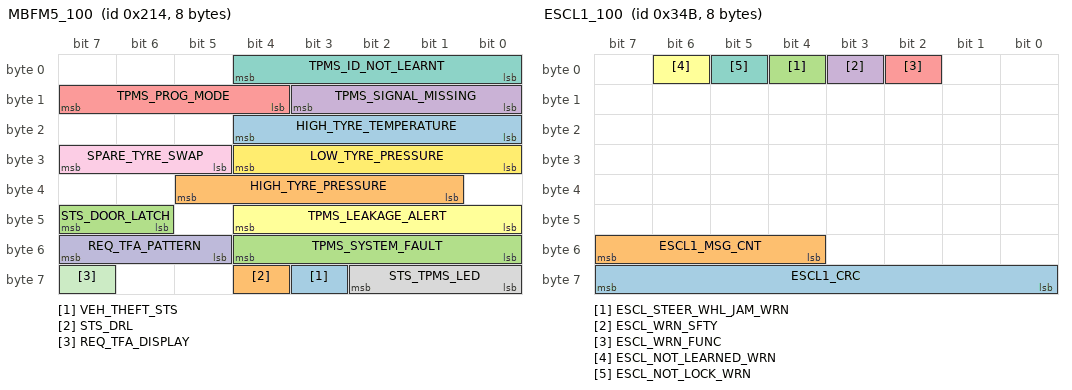
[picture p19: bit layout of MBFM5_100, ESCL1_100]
BO_ 532 MBFM5_100: 8 Vector__XXX
 SG_ VEH_THEFT_STS : 59|1@1+ (1,0) [0|1] ""  SMART_CORE
 SG_ STS_DRL : 60|1@1+ (1,0) [0|1] ""  SMART_CORE
 SG_ TPMS_SYSTEM_FAULT : 48|5@1+ (1,0) [0|31] ""  SMART_CORE
 SG_ TPMS_SIGNAL_MISSING : 8|4@1+ (1,0) [0|15] ""  SMART_CORE
 SG_ TPMS_PROG_MODE : 12|4@1+ (1,0) [0|15] ""  SMART_CORE
 SG_ TPMS_LEAKAGE_ALERT : 40|5@1+ (1,0) [0|31] ""  SMART_CORE
 SG_ TPMS_ID_NOT_LEARNT : 0|5@1+ (1,0) [0|31] ""  SMART_CORE
 SG_ STS_TPMS_LED : 56|3@1+ (1,0) [0|3] ""  SMART_CORE
 SG_ SPARE_TYRE_SWAP : 29|3@1+ (1,0) [0|4] ""  SMART_CORE
 SG_ REQ_TFA_PATTERN : 53|3@1+ (1,0) [0|5] ""  SMART_CORE
 SG_ REQ_TFA_DISPLAY : 63|1@1+ (1,0) [0|1] ""  SMART_CORE
 SG_ LOW_TYRE_PRESSURE : 24|5@1+ (1,0) [0|31] ""  SMART_CORE
 SG_ HIGH_TYRE_TEMPERATURE : 16|5@1+ (1,0) [0|31] ""  SMART_CORE
 SG_ HIGH_TYRE_PRESSURE : 33|5@1+ (1,0) [0|31] ""  SMART_CORE
 SG_ STS_DOOR_LATCH : 46|2@1+ (1,0) [0|3] ""  SMART_CORE

BO_ 843 ESCL1_100: 8 Vector__XXX
 SG_ ESCL1_CRC : 56|8@1+ (1,0) [0|255] ""  SMART_CORE
 SG_ ESCL1_MSG_CNT : 52|4@1+ (1,0) [0|15] ""  SMART_CORE
 SG_ ESCL_STEER_WHL_JAM_WRN : 4|1@1+ (1,0) [0|1] ""  SMART_CORE
 SG_ ESCL_WRN_SFTY : 3|1@1+ (1,0) [0|1] ""  SMART_CORE
 SG_ ESCL_WRN_FUNC : 2|1@1+ (1,0) [0|1] ""  SMART_CORE
 SG_ ESCL_NOT_LEARNED_WRN : 6|1@1+ (1,0) [0|1] ""  SMART_CORE
 SG_ ESCL_NOT_LOCK_WRN : 5|1@1+ (1,0) [0|1] ""  SMART_CORE

CM_ BO_ 577 "CGW Critical Signals 01";
CM_ SG_ 577 VCU_ExMeDi_IdxDcChrgnErr "For diagnostic and troubleshooting purposes the ExMeDi component computes an error index.
Information given in Value description contains only bit level information,  not exact value";
CM_ SG_ 577 VCU_StMacErr "State Machine Error";
CM_ SG_ 577 VCU_RespCod "Response Code";
CM_ SG_ 577 VCU_MsgSts "Message Status";
CM_ SG_ 577 VCU_Charge_Discharge_Trans "Signal for telling transition from charge to discharge and vice versa";
CM_ SG_ 577 VCU_TransPmotorparkReq "transmission parking request";
CM_ SG_ 577 VCU_eComp_HVIL_Status "Compressor HVIL Status";
CM_ SG_ 577 VCU241_Checksum "Checksum";
CM_ SG_ 577 VCU241_COUNTER "Message Counter";
CM_ SG_ 577 VCU_SRSCrashSta "Crash Information from SRS Unit";
CM_ BO_ 822 "VCU Normal Signals 01";
CM_ SG_ 822 VCU336_CRC "CRC, CHECKSUM ERROR as per SAEJ1850";
CM_ SG_ 822 VCU336_COUNTER "Message Counter";
CM_ SG_ 822 VCU_AUX_BATTERY_VOLT "Aux Battery voltage";
CM_ SG_ 822 VCU_Vehicle_Speed "Vehicle Speed";
CM_ SG_ 822 VCU_STS_IGN "Status of Ignition Key KL15";
CM_ SG_ 822 VCU_EPTCoolantTemp "EPT Coolant Temp";
CM_ SG_ 822 VCU_EPTCoolantFlow "Actual EPT Coolant Flow";
CM_ SG_ 822 VCU_EVReady "Electric Powertrain System Ready for driving.";
CM_ SG_ 437 VCU_BMS_ASW_SleepRequest "This signal will be used for initiating sleep for BMS after VCU triggers MCU , ETL relay off";
CM_ SG_ 437 VCU_SmObc_State "State manager of OBC- Internal state for AC Charging";
CM_ SG_ 437 VCU_Wakeup_Reason_internal "VCU wake up source(Purpose)";
CM_ SG_ 437 VCU_NoSM_State "VCU Normal state- Internal PUPD State";
CM_ SG_ 437 VCU_EVCSI_State "Electric vehicle charging state identifier -- Internal state for DC Charging";
CM_ SG_ 437 VCU_CharPD_RawVal "Porximity detection Raw Value";
CM_ SG_ 437 VCU_CharCP_RawVal "Charging Control Pilot Raw Value";
CM_ SG_ 601 VCU_StsIslnEvse "EVSE Isolation Status";
CM_ SG_ 601 VCU_ValEvseUMinLim "EVSE Minimum Voltage value from EVSE Station";
CM_ SG_ 601 VCU_LV_Battery_Voltage "LV battery voltage measurement";
CM_ SG_ 601 VCU_brake2_voltage "Brake pedal2 volttge";
CM_ SG_ 601 VCU_brake1_voltage "Brake pedal1 voltage";
CM_ SG_ 601 VCU_Accep2_voltage "Accelerator pedal2 voltage";
CM_ SG_ 601 VCU_Accep1_voltage "Accelerator pedal1 voltage";
CM_ SG_ 1731 VCU_ValEvseUMaxLim "EVSE Maximum Voltage limit value from Station";
CM_ SG_ 1731 VCU_CharInletTempNeg "Charging Inlet Temperature at DC Negative";
CM_ SG_ 1731 VCU_PumpSpdFb "VCU Cooling Pump Feedback";
CM_ SG_ 1731 VCU_PumpSpdCtrl "VCU Cooling Pump Control speed";
CM_ SG_ 1731 VCU_CoolFanSpdCtrl "VCU Cooling Fan Control speed";
CM_ SG_ 1731 VCU_CharPlugLockFbSts "Charging Plug Lock Feedback Status";
CM_ SG_ 1731 VCU_CharPlugLockCtrlSts "Charing Plug Lock Control Status";
CM_ SG_ 1731 VCU_CharPlugAtLockSwIndSts "Charging Plug Auto Lock Switch indication Lamp Status";
CM_ SG_ 1731 VCU_CharInletTempPos "Charging Inlet Temperature at DC Positive";
CM_ SG_ 1481 VCU_COMFLT_MSG_CONTFAIL "Message Content Failure";
CM_ SG_ 1481 VCU_COMFLT_SGN_CONTFAIL "Signal Content failure";
CM_ SG_ 1481 VCU_AUX_BATT_VOLT "Aux Battery Voltage";
CM_ SG_ 1481 VCU_UV_STS "NM Undervoltage STS";
CM_ SG_ 1481 VCU_STS_IGN_NM "This is NM IGN status not the actual KL15. It will come with delay of approx 500ms";
CM_ SG_ 1481 VCU_OV_STS "NM Overvoltage STS";
CM_ SG_ 1481 VCU_SW_VERSION "VCU Software Version";
CM_ SG_ 1481 VCU_COMFLT_NODEABS_STS "Node Absent";
CM_ SG_ 1481 VCU_VARIANT_CODE_ERR_STS "VCU Variant Code DTC Status";
CM_ SG_ 1481 VCU_NM_ACTIVE_STS "MCU NM Status";
CM_ SG_ 1481 VCU_FEATURE_CODE_ERR_STS "MCU Feature Code DTC Status";
CM_ SG_ 1481 VCU_COMFLT_MSGTOUT_STS "Key Message Timeout";
CM_ SG_ 988 OBC_Low_Temp_Shutdown "OBC_Low_Temp_Shutdown";
CM_ SG_ 988 OBC_HVDC_HW_OV "OBC Hardware Over Voltage fault";
CM_ SG_ 988 OBC_CPVol_Out_of_Range "OBC_Control Pilot Voltage Out of Range";
CM_ SG_ 988 OBC_CPDuty_Out_of_Range "Hardware Output Over voltage fault";
CM_ SG_ 988 OBC_HVDC_HW_OC "Hardware Output Over Current fault";
CM_ SG_ 988 OBC_PFC_BUS_FAULT_CNT "PFC bus fault count";
CM_ SG_ 988 OBC_PFC_VOLT_CNTRL_IP "PFC Voltage control input";
CM_ SG_ 988 OBC_LIne_OC_SW "Line Overcurrent flag
";
CM_ SG_ 988 OBC_Inductr_current_L2_OC "Inductor2_overcurrent flag";
CM_ SG_ 988 OBC_Inductr_current_L1_OC "Inductor1_overcurrent flag";
CM_ SG_ 988 OBC_VPROG_OUT_OF_RANGE "VPROG Out of Range";
CM_ SG_ 988 OBC_TEMP_SENSOR_FAIL "OBC temperature sensor failure";
CM_ SG_ 988 OBC_OVER_TEMP "OBC Over Temperature";
CM_ SG_ 988 OBC_INTERNAL_FAIL "OBC Internal Failure";
CM_ SG_ 988 OBC_HIGH_TEMP "OBC High Temperature";
CM_ SG_ 988 OBC_IPROG_OUT_OF_RANGE "IPROG Out of Range";
CM_ SG_ 988 OBC_EMI_IP_UV "EMI input under voltage";
CM_ SG_ 988 OBC_EMI_IP_OV "IPC Communication Error";
CM_ SG_ 988 OBC_EEPROM_FAIL "EEPROM Fail";
CM_ SG_ 988 OBC_CAN_BUS_OFF "OBC CAN BUS OFF";
CM_ SG_ 988 OBC_TEMP_DERATE "Temperature Derate";
CM_ SG_ 988 OBC_PRE_CHARGE_FAULT "Precharge Fault";
CM_ SG_ 988 OBC_PFV_OV "PFC Over Voltage";
CM_ SG_ 988 OBC_PFC_UV "PFC Under Voltage";
CM_ SG_ 988 OBC_PFC_OVER_TEMP "PFC Over Temperature";
CM_ SG_ 988 OBC_OP_UV "output Undervoltage";
CM_ SG_ 988 OBC_OP_OV "output Overvoltage";
CM_ SG_ 988 OBC_OP_OC "Output Overcurrent";
CM_ SG_ 988 OBC_LV_UNDER_VOLT "LV Under Voltage";
CM_ SG_ 988 OBC_LV_OVER_VOLT "LV Over Voltage";
CM_ SG_ 988 OBC_LLC_OVER_TEMP "LLC Over Temperature";
CM_ SG_ 988 OBC_IP_UNDER_VOLT "IP Under Voltage";
CM_ SG_ 988 OBC_IP_OVER_VOLT "IP Over Voltage";
CM_ SG_ 988 OBC_IP_OVER_CURR "IP Over Current";
CM_ SG_ 988 OBC_IP_DERATE "Input Derate";
CM_ SG_ 1480 OBC_COMFLT_SGN_CONTFAIL "Signal Content Failure";
CM_ SG_ 1480 OBC_UV_STS "NM Undervoltage STS";
CM_ SG_ 1480 OBC_STS_IGN_NM "Status of IGN";
CM_ SG_ 1480 OBC_OV_STS "NM Overvoltage STS";
CM_ SG_ 1480 OBC_AUX_BATT_VOLT "Aux Battery Voltage";
CM_ SG_ 1480 OBC_SW_VERSION "OBC Software Version";
CM_ SG_ 1480 OBC_COMFLT_MSG_CONTFAIL "Message Content Failure";
CM_ SG_ 1480 OBC_COMFLT_NODEABS_STS "Node Absent";
CM_ SG_ 1480 OBC_NM_ACTIVE_STS "NM Status";
CM_ SG_ 1480 OBC_VARIANT_CODE_ERR_STS "Variant Code DTC Status";
CM_ SG_ 1480 OBC_FEATURE_CODE_ERR_STS "Feature Code DTC Status";
CM_ SG_ 1480 OBC_COMFLT_MSGTOUT_STS "Key Message Timeout";
CM_ BO_ 983 "MCU Normal Signals 04";
CM_ SG_ 983 MCU_TPI "Thermal performance indicator for MCU.
TPI=2 -> No derating
TPI>=1 & TPI <2 -> derating warning 
TPI < 1 -> derating in progress";
CM_ SG_ 983 MCU_MotorCoolingFlowReq "Flow Request from motor.";
CM_ SG_ 983 MCU_Motor_Temp_Indicator "Temperature from different points of motor 
(coil etc) will be converted that to percentage format";
CM_ SG_ 983 MCU_Inverter_Temp_Indicator "MCU Thermal Indicator Inverter.";
CM_ SG_ 983 MCU_Inverter_CoolingFlowReq "Pump Flow request from MCU based on MCU cooling requirements";
CM_ BO_ 280 "MCU Critical Signals 02";
CM_ SG_ 280 MCU118_COUNTER "Message Counter";
CM_ SG_ 280 MCU118_Checksum "Checksum";
CM_ SG_ 280 MCU_MotorSpeed "MCU Motor Speed in RPM";
CM_ SG_ 280 MCU_MotorTorqueEstimated "Motorization estimated electric torque at the motor output shaft with higher resolution
";
CM_ SG_ 1016 BMS_HTR_CLT_SoftwareVersion_Num "Software Version of the CLT Heater
";
CM_ SG_ 1016 BMS_HTR_CLT_Fault_PCBTempSen "PCB Temperature Sensor Failure
";
CM_ SG_ 1016 BMS_HTR_CLT_Fault_PCBTempOver "PCB Over Temperature Protection - Condition : PCB Temperature = 90?(TBD) ( Rlease : PCB Temperature = 85?(TBD))
";
CM_ SG_ 1016 BMS_HTR_CLT_Fault_OutletTempSen "Outlet Temperature Sensor Failure
";
CM_ SG_ 1016 BMS_HTR_CLT_Fault_OutletTempOver "Outlet Over Temperature Protection - Condition : Outlet Temperature = 70?(TBD) ( Rlease : Outlet Temperature = 45?(TBD)) - The reason why the outlet temp warning is 70 ? is that the outlet temp target is 60 ? at the maximum.
";
CM_ SG_ 1016 BMS_HTR_CLT_Fault_LVSen "LV Sensor Failure
";
CM_ SG_ 1016 BMS_HTR_CLT_Fault_LostCtrlMsg "Receiving 'ECU_CLT_Ctrl_Msg' frame (ID 0x22) delayed over 4 sec(TBD)
";
CM_ SG_ 1016 BMS_HTR_CLT_Fault_IGBTShort "IGBT Short Failure (Short Load)
";
CM_ SG_ 1016 BMS_HTR_CLT_Fault_IGBTOpen "IGBT Open Failure ( Open Load)
";
CM_ SG_ 1016 BMS_HTR_CLT_Fault_IGBTDriverIC "Detected fault signal from the IGBT Driver
";
CM_ SG_ 1016 BMS_HTR_CLT_Fault_HVSen "HV Sensor Failure
";
CM_ SG_ 1016 BMS_HTR_CLT_Fault_HVOver "HV Over Voltage Protection - Condition : HV = 460V( Release : HV = 450V)
";
CM_ SG_ 1016 BMS_HTR_CLT_Fault_HVCurSen "HV Current Sensor Failure
";
CM_ SG_ 1016 BMS_HTR_CLT_LIN_Com_Err_Flag "Checksum, PID, DATA .Framing errs on LIN(Sticky flag)
";
CM_ SG_ 1016 BMS_HTR_CLT_Fault_LVUnder "LV Under Voltage Protection - Condition : LV = 8V ( Release : LV = 9V)
";
CM_ SG_ 1016 BMS_HTR_CLT_Fault_LVOver "LV Over Voltage Protection - Condition : LV = 17V( Release : LV = 16V)
";
CM_ SG_ 1016 BMS_HTR_CLT_Fault_HVUnder "HV Under Voltage Protection - Condition : HV = 90V ( Release : HV = 100V)
";
CM_ SG_ 1016 BMS_HTR_CLT_Fault_HVOverCur "HV Over Current Protection - Condition : HV Current = 40A (heater stops heating and retries operation again after 30
";
CM_ SG_ 1016 BMS_HTR_CLT_Fault_Flag "Heater has a fault or failure code(Sum of bit#8 ~ bit#31)
";
CM_ BO_ 993 "VCU EVCAN Active Frame";
CM_ SG_ 993 VCU_ACTIVE_RESERVED_EV "VCU EVCAN Active Reserved";
CM_ BO_ 824 "VCU Critical Signals 03";
CM_ SG_ 824 VCU338_COUNTER "Message Counter";
CM_ SG_ 824 VCU_CmdACChargeTargetVolt "Charging Target Voltage (from VCU Request to OBC / Charging Stand)";
CM_ SG_ 824 VCU338_CRC "CRC, CHECKSUM ERROR as per SAEJ1850";
CM_ SG_ 824 VCU_CmdEnableOBC "VCU sends Enable signal to OBC to start power delivery";
CM_ SG_ 824 VCU_CmdACChargeTargetCurrent "Charging Target Current (from VCU Request to OBC / Charging Stand)";
CM_ SG_ 824 VCU_ACChargingReady "This message provides VCU status for charging.";
CM_ SG_ 1474 VCU_AVAIL_BAT_HEATER_PWR "Available battery heater power";
CM_ SG_ 1736 VCU_EConsDistSample4 "Energy consumption for sample distance 4";
CM_ SG_ 1736 VCU_EConsDistSample3 "Energy consumption for sample distance 3";
CM_ SG_ 1736 VCU_EConsDistSample2 "Energy consumption for sample distance 2";
CM_ SG_ 1736 VCU_EConsDistSample1 "Energy consumption for sample distance 1";
CM_ SG_ 1012 VCU_DcChargingSequence "DC Charging Sequence Status";
CM_ SG_ 1012 VCU_SBWS_BuFb_RawVal "SBWS back up feedback(PWM) raw value";
CM_ SG_ 1012 VCU_SBWS_Bu_RawVal "SBWS back up(PWM) raw value";
CM_ SG_ 1012 VCU_PumpRlyCtrlSts "Cooling Pump relay control status";
CM_ SG_ 1012 VCU_MAX_CPU_Load "Internal test signal for maximum CPU load";
CM_ SG_ 1012 VCU_AVG_CPU_Load "Test signal for average CPU Load";
CM_ SG_ 1006 VCU_QkCharPosRlyFblSts "VCU Qick Charging Positive Relay Feedback Status";
CM_ SG_ 1006 VCU_QkCharPosRlyCtrlSts "VCU Qick Charging Positive Relay Control Status";
CM_ SG_ 1006 VCU_QkCharNegRlyFblSts "VCU Qick Charging Negative Relay Feedback Status";
CM_ SG_ 1006 VCU_QkCharNegRlyCtrlSts "VCU Qick Charging Negative Relay Control Status";
CM_ SG_ 1006 VCU_CharIndRedCtrlSts "Charging Indicaiton Lamp(Red Led) Control Status(PWM)";
CM_ SG_ 1006 VCU_CharIndGrCtrlSts "Charging Indicaiton Lamp(Green Led) Control Status(PWM)";
CM_ SG_ 1006 VCU_CharIndBlCtrlSts "Charging Indicaiton Lamp(Blue Led) Control Status(PWM)";
CM_ BO_ 984 "OBC Normal Signals 02";
CM_ SG_ 984 OBC_PFC_Voltage "OBC PFC Voltage";
CM_ SG_ 984 OBC_DCVoltageCapable "OBC Voltage capability";
CM_ SG_ 984 OBC_DCCurrentCapable "OBC DC Current capability";
CM_ BO_ 1064 "OBC Normal Signals 01";
CM_ SG_ 1064 OBC_PowerDeratingSta "OBV Power Derating Status";
CM_ SG_ 1064 OBC_OperatingMode "OBC System controller status information";
CM_ SG_ 1064 OBC_ACDetectSta "OBC Main (AC) Source Detection";
CM_ SG_ 986 OBC_Transformer_Temperature "OBC Temperature value";
CM_ SG_ 986 OBC_CoolingRequest "OBC Cooling Request signal";
CM_ SG_ 986 OBC_PrimarySide_Temperature "OBC temperature";
CM_ SG_ 986 OBC_LV_PwrSupply "LV power Supply";
CM_ SG_ 1479 MCU_SW_Version_Internal "MCU software version internal";
CM_ SG_ 1479 MCU_COMFLT_SGN_CONTFAIL "Signal Content Failure";
CM_ SG_ 1479 MCU_OV_STS "NM Overvoltage STS";
CM_ SG_ 1479 MCU_UV_STS "NM Undervoltage STS";
CM_ SG_ 1479 MCU_STS_IGN "Status of IGN";
CM_ SG_ 1479 MCU_AUX_BATT_VOLT "Aux Battery Voltage";
CM_ SG_ 1479 MCU_SW_VERSION "MCU Software Version";
CM_ SG_ 1479 MCU_COMFLT_MSG_CONTFAIL "Message Content Failure";
CM_ SG_ 1479 MCU_NM_ACTIVE_STS "MCU NM Status";
CM_ SG_ 1479 MCU_COMFLT_NODEABS_STS "NODE ABSENT Status";
CM_ SG_ 1479 MCU_COMFLT_MSGTOUT_STS "Key Message Timeout";
CM_ SG_ 283 MCU11B_Checksum "Checksum";
CM_ SG_ 283 MCU11B_COUNTER "Message Counter";
CM_ SG_ 283 MCU_ErrorLevel "MCU Error Levels";
CM_ SG_ 283 MCU_ActiveDamping "Active Damping ";
CM_ SG_ 283 MCU_OperationalMode "Operation mode of MCU";
CM_ SG_ 283 MCU_CommandMode "Input command mode of MCU";
CM_ SG_ 283 MCU_State "MCU state";
CM_ SG_ 283 MCU_ACTV_Discharge_STS "HV Active Discharging Status";
CM_ SG_ 283 MCU_ACTV_Discharge_FAIL "HV Active Discharging Failure Status";
CM_ BO_ 982 "MCU Critical Signals 01";
CM_ SG_ 982 MCU_HighPowerCurrent "Motor High Power current";
CM_ SG_ 982 MCU_HighPowerVoltage "Motor High Power Voltage";
CM_ SG_ 982 MCU_TractionTorqueAvail_quasi "Available quasistatic traction torque";
CM_ SG_ 982 MCU_RegenTorqueAvail_quasi "Available quasistatic regen torque";
CM_ SG_ 1478 LDC_COMFLT_SGN_CONTFAIL "Signal Content Failure";
CM_ SG_ 1478 LDC_UV_STS "NM Undervoltage STS";
CM_ SG_ 1478 LDC_OV_STS "NM Overrvoltage STS";
CM_ SG_ 1478 LDC_STS_IGN_NM "Status of IGN";
CM_ SG_ 1478 LDC_AUX_BATT_VOLT "Aux Battery Voltage";
CM_ SG_ 1478 LDC_SW_VERSION "LDC Software Version";
CM_ SG_ 1478 LDC_COMFLT_MSG_CONTFAIL "Message Content Failure";
CM_ SG_ 1478 LDC_COMFLT_NODEABS_STS "Node Abssent";
CM_ SG_ 1478 LDC_VARIANT_CODE_ERR_STS "Variant Code DTC Status";
CM_ SG_ 1478 LDC_NM_ACTIVE_STS "NM Status";
CM_ SG_ 1478 LDC_FEATURE_CODE_ERR_STS "Feature Code DTC Status";
CM_ SG_ 1478 LDC_COMFLT_MSGTOUT_STS "Key Message Timeout";
CM_ SG_ 1477 ETL_COMFLT_SGN_CONTFAIL "Signal Content Failure";
CM_ SG_ 1477 ETL_OV_STS "NM Overrvoltage STS";
CM_ SG_ 1477 ETL_UV_STS "NM Undervoltage STS";
CM_ SG_ 1477 ETL_STS_IGN "Status of IGN";
CM_ SG_ 1477 ETL_AUX_BATT_VOLT "Aux Battery Voltage";
CM_ SG_ 1477 ETL_SW_VERSION "ETL Software Version";
CM_ SG_ 1477 ETL_COMFLT_MSG_CONTFAIL "Message Content Failure";
CM_ SG_ 1477 ETL_COMFLT_NODEABS_STS "Node Absent";
CM_ SG_ 1477 ETL_COMFLT_MSGTOUT_STS "Key Message Timeout";
CM_ BO_ 578 "ETL Critical Signals 01";
CM_ SG_ 578 ETL_Shifting_In_Progress "Shifting in Progress";
CM_ SG_ 578 ETL_Service_WRN_IND "Service warning";
CM_ SG_ 578 ETL_Pmotor_Position_Failure "Parking Motor Position Failure Status";
CM_ SG_ 578 ETL242_COUNTER "Message Counter";
CM_ SG_ 578 ETL242_CRC "CRC, CHECKSUM ERROR as per SAEJ1850";
CM_ SG_ 578 ETL_PmotorPositionStatus "Parking Motor Position Status";
CM_ SG_ 578 ETL_PmotorErrorLevel "EGP internal state error ";
CM_ SG_ 578 ETL_OperationMode "EGP operation Mode";
CM_ SG_ 1475 BMS_STS_IGN_NM "Status of IGN NM";
CM_ SG_ 1475 BMS_COMFLT_SGN_CONTFAIL "Signal  Content Failure";
CM_ SG_ 1475 BMS_UV_STS "NM Undervoltage STS";
CM_ SG_ 1475 BMS_OV_STS "NM Overvoltage STS";
CM_ SG_ 1475 BMS_AUX_BATT_VOLT "Aux Battery Voltage";
CM_ SG_ 1475 BMS_SW_VERSION "BMS Software Version";
CM_ SG_ 1475 BMS_COMFLT_MSG_CONTFAIL "Message Content Failure";
CM_ SG_ 1475 BMS_COMFLT_NODEABS_STS "Node Absent";
CM_ SG_ 1475 BMS_VARIANT_CODE_ERR_STS "BMS Variant Code DTC Status";
CM_ SG_ 1475 BMS_NM_ACTIVE_STS "NM Status";
CM_ SG_ 1475 BMS_FEATURE_CODE_ERR_STS "Feature Code DTC Status";
CM_ SG_ 1475 BMS_COMFLT_MSGTOUT_STS "Key Message Timeout";
CM_ SG_ 1002 BMS_Regen_AH "REGEN AMPERE HOUR";
CM_ SG_ 1002 BMS_KiloWattHour "BMS KILOWATTHOUR";
CM_ SG_ 1002 BMS_AmpereHour "BMS Ampere Hour";
CM_ BO_ 980 "BMS Normal Signals 05";
CM_ SG_ 980 BMS_Batt_Overcurrent_Sta "Battery Overcurrent Status";
CM_ SG_ 980 BMS_DischargePowerAvailable_2 "Battery Discharge power avaible for next 2sec";
CM_ SG_ 980 BMS_DischargePowerAvailable_10 "Battery available Discharge power  for next 10sec";
CM_ SG_ 980 BMS_BatteryPackSOE "Battery Remaning Capacity";
CM_ BO_ 978 "BMS Normal Signals 09";
CM_ SG_ 978 BMS_BHeaterFlt "Battery Heater fault information";
CM_ SG_ 978 BMS_BHeaterOpCoolantTemp "Battery Heater Output Coolant temperature";
CM_ SG_ 978 BMS_CoolingHeatingSta "setting the cooling/Heating request to On or OFF completely";
CM_ SG_ 978 BMS_ChillerSoleniodSta "Status of Chiller Soleniod";
CM_ SG_ 978 BMS_BatteryPreconditioningSta "HV Battery Preconditioning status";
CM_ SG_ 978 BMS_BatteryOutletCoolantTemp "HV Battery Outlet Coolant  temperature  information";
CM_ SG_ 978 BMS_BatteryInletCoolantTempReq "Coolant inlet temperature request";
CM_ SG_ 978 BMS_BatteryInletCoolantTemp "HV Battery Inlet Coolant temperature";
CM_ BO_ 626 "BMS Critical Signals 02";
CM_ SG_ 626 BMS_BatteryTBatt "Estimated Battery Temperature";
CM_ SG_ 626 BMS_BatteryPackVoltage "Battery Pack Voltage";
CM_ SG_ 626 BMS_DisconnectByBMS "Disconnect by BMS";
CM_ SG_ 626 BMS_BatteryHVILSta "Battery HVIL status'";
CM_ SG_ 626 BMS_ModuleActiveDischarge "Module Active Discharge Request";
CM_ SG_ 626 BMS272_COUNTER "Message Counter";
CM_ SG_ 626 BMS272_CRC "CRC, CHECKSUM ERROR as per SAEJ1850";
CM_ SG_ 626 BMS_BContactorOffRequest "Request VCU  to open contactor from BMS";
CM_ SG_ 626 BMS_HVILSta "High voltage interlock loop status (MCU, PDU, OBC & Battery pack)";
CM_ SG_ 626 BMS_PilotlineSta "PilotLine Status";
CM_ SG_ 626 BMS_IsolationFlt "Isolation faults status";
CM_ SG_ 626 BMS_CrashPyroFuseResponse "Pyro Fuse ststus over CAN";
CM_ BO_ 337 "BMS Normal Signals 06";
CM_ SG_ 337 BMS151_CRC "CRC, CHECKSUM ERROR as per SAEJ1850";
CM_ SG_ 337 BMS151_COUNTER "Message Counter";
CM_ SG_ 337 BMS_BMainMinusContactorState "Battery Main Minus Contactor State";
CM_ SG_ 337 BMS_PreChargeContactorSta "HV Battery Precharge relay ON/OFF status";
CM_ SG_ 337 BMS_BMainPlusContactorState "Battery Main Plus Contactor State";
CM_ SG_ 337 BMS_Current2sensorReading "HES Current Sensor Reading";
CM_ SG_ 337 BMS_Current1sensorReading "IVT Current sensor readings";
CM_ BO_ 999 "BMS Normal Signals 03";
CM_ SG_ 999 BMS_BatteryMaxCellVoltage "Battery Max Cell Voltage";
CM_ SG_ 999 BMS_BatteryMinCellVoltage "Battery Min Cell Voltage";
CM_ SG_ 999 BMS_BatteryDisconnectSta "HV Battery Disconnect status (after request from VCU)";
CM_ SG_ 999 BMS_BatteryConnectSta "HV Battery connect status (after request from VCU)";
CM_ SG_ 999 BMS_BatteryAvgCellVoltage "Battery Average Cell Voltage";
CM_ BO_ 1000 "BMS Normal Signals 02";
CM_ SG_ 1000 BMS_BatteryPackSOH "HV Battery SOH";
CM_ SG_ 1000 BMS_BatteryPackRSOC "Battery Pack RSOC (Relative)  -> Display on cluster (0~100%)";
CM_ SG_ 1000 BMS_BatteryPackASOC "Battery Pack ASOC (Absolute)";
CM_ SG_ 2013 DIAG_TGU_RES_DATA "Keyword 2000 Diagnostic Message Response Data";
CM_ BO_ 1652 "Telematics";
CM_ SG_ 1652 VEH_SEARCH_REQ "TGU commands to Search Vehicle";
CM_ SG_ 1652 CHARGING_ON_OFF_REQ "CHARGING ENABLE DISABLE REQUEST";
CM_ SG_ 1652 TGU_REVIVE_REQ "REVIVE REQUEST";
CM_ SG_ 1652 REMOTE_DOOR_LOCK_UNLOCK "DOOR REMOTE LOCK/UNLOCK";
CM_ SG_ 374 TGS_MODE_AMT "Mode Switch State";
CM_ SG_ 264 ALTERNATOR_CUTOFF_REQ "S201 Cluster controls Alternator cutoff, during vehicle launch EMS would request cluster for ALT cutoff.
SIgnal implementation required only for S201 DCM71.";
CM_ SG_ 264 CLUTCH_STS "'Clutch press states";
CM_ BO_ 1980 "OBCLDC Diagnostic Response";
CM_ SG_ 1980 DIAG_LDC_RES_DATA "Diagnostic Res from LDC to Tool";
CM_ SG_ 2008 DIAG_MCU_RES_DATA "MCU Diagnostic Response";
CM_ BO_ 579 "VCU EVCAN Wakeup Frame.It would be sent spontaneously after every 20ms for 60ms (3 times)";
CM_ SG_ 579 VCU_EVCAN_WAKEUPREASONRESERVED2 "VCU EV CAN Wakeup Reason";
CM_ SG_ 579 VCU_EVCAN_WAKEUPREASONRESERVED1 "VCU EV CAN Wakeup Reason";
CM_ SG_ 579 VCU_EVCAN_WAKEUPREASON "VCU EV CAN Wakeup Reason";
CM_ BO_ 936 "VCU EVCAN Sleep Frame";
CM_ SG_ 936 VCU_EVCAN_SLEEPRESERVED "VCU EVCAN Sleep Reserved";
CM_ BO_ 1933 "ETL Diagnotic Response";
CM_ SG_ 1933 DIAG_ETL_RES_DATA "Diagnostic Res from ETL  to Tool";
CM_ BO_ 1981 "OBCLDC Diagnostic Response";
CM_ SG_ 1981 DIAG_OBC_RES_DATA "Diagnostic Res from OBC to Tool";
CM_ BO_ 1976 "BMS Diagnostic Response";
CM_ SG_ 1976 DIAG_BMS_RES_DATA "Diagnostic Res from BMS to Tool";
CM_ BO_ 1972 "OBCLDC Diagnostic Request";
CM_ SG_ 1972 DIAG_LDC_REQ_DATA "Diagnostic Req from Tool to LDC";
CM_ BO_ 1925 "ETL Diagnostic Request";
CM_ SG_ 1925 DIAG_ETL_REQ_DATA "Diagnostic Req from Tool to ETL";
CM_ BO_ 1973 "OBCLDC Diagnostic Request";
CM_ SG_ 1973 DIAG_OBC_REQ_DATA "Diagnostic Req from Tool to OBC";
CM_ BO_ 2000 "MCU Diagnostic Request";
CM_ SG_ 2000 DIAG_MCU_REQ_DATA "Diagnostic Req from Tool to MCU";
CM_ BO_ 1968 "BMS Diagnostic Request";
CM_ SG_ 1968 DIAG_BMS_REQ_DATA "Diagnostic Req from Tool to BMS";
CM_ SG_ 336 BMS_TotalCycle_Time "BMS CYCLE TIME 
>Cycle time is the summation of charge cycle time and discharge cycle time
>Cycle time should be calculated at the instant when the cumulative charge cycle number and the discharge cycle get incremented by 1 
";
CM_ SG_ 336 BMS_DischargeCycle_Time "BMSDischargeCycle time
>Discharge cycle time set point is when IGN connected 
>Discharge cycle time finish point is till next charge plug connected or till BMS sleep

";
CM_ SG_ 336 BMS_ChargeCycle_Time "BMS Charge cycle time
>Charge cycle time set point is when charge plug is connected
>Charge cycle time finish point is end of charge concurrence/unplugging of the charger
";
CM_ SG_ 336 BMS_CycleNumber "BMS CYCLE NUMBER ";
CM_ SG_ 285 BMS_BattPack_PwrLimitErr_Common "Battery Pack Power limit Error";
CM_ SG_ 285 BMS_Bat_I_OvrExtCurr_Flt_Dischrg "Battery over extreme current fault during discharge ( I between 392 to 500 A )";
CM_ SG_ 285 BMS_Bat_I_OverCurr_Flt_Discharge "Battery over current fault during discharge ( I = 392 A )";
CM_ SG_ 285 BMS_BattOverVolt_Cutoff_Charge "Battery Over Voltage Cutoff at Charge
";
CM_ SG_ 285 BMS_ClntInlet_High_Temp_Charge "Coolant Inlet High Temp at charging

";
CM_ SG_ 285 BMS_ClntInlet_Low_Temp_Charge "Coolant Inlet Low Temp at Charging";
CM_ SG_ 285 BMS_ClntOutlet_Low_Temp_Charge "Coolant Outlet Low temp while Charging
";
CM_ SG_ 285 BMS_Clntoutlet_High_Temp_Charge "Coolant Outlet High Temp while Charging";
CM_ SG_ 285 BMS_BattOver_Temp_Cutoff_common "Battery Over Temp cutoff
";
CM_ SG_ 285 BMS_BattUnder_Temp_Cutoff_common "Battery Under temp cutoff";
CM_ SG_ 285 BMS_ClntSen_Thres_Fault_Charge "Coolant Sensor Threshold fault during charging";
CM_ SG_ 285 BMS_ReverseCurrDetect_Charge "Reverse current detected while charging
";
CM_ SG_ 285 BMS_PLP_Stop_Charge "Pack Level protection: Stop Charge";
CM_ SG_ 285 BMS_CellUnderVolt_Cutoff_Common "Cell under Voltage Cutoff";
CM_ SG_ 285 BMS_BattUnderVolt_Cutoff_Common "Battery Under Voltage Cutoff";
CM_ SG_ 285 BMS_ModuleOverTemp_Cutoff_Common "Module Over temp cutoff";
CM_ SG_ 285 BMS_MdleUnderTemp_Cutoff_Common "Module Under Temperature cutoff ";
CM_ SG_ 285 BMS_ShortCircuitCurr_Flt_Common "Short Circuit Current Fault";
CM_ SG_ 285 BMS_Sensor_Failure_Common "Sesor Failure";
CM_ SG_ 285 BMS_Ibatt_392_25sec_Common "Ibatt=392 for 25 sec";
CM_ SG_ 285 BMS_PilotLine_Detect_Common "Pilot Line Detection fault";
CM_ SG_ 285 BMS_Revive_Common "Revive fault
";
CM_ SG_ 285 BMS_HeaterSys_Flt_Common "Heater System Fault";
CM_ SG_ 285 BMS_Clnt_TempSens_Flt_Common "Coolant Temperature Sensor Fault";
CM_ SG_ 285 BMS_Heater_Flt_Common "Heater Fault";
CM_ SG_ 285 BMS_IsoFLt_Red_Discharge "Isolation Fault Red during Discharge";
CM_ SG_ 285 BMS_LowSOC_Cutoff_Discharge "Low SOC Cutoff during Dishcharging";
CM_ SG_ 285 BMS_Bat_I_ExtCurr_Flt_Dischrg "Battery extreme current fault during discharge ( Greater than 500 A )";
CM_ SG_ 285 BMS_MTM_ActvLimit_Common "Module Temperature Monitoring active limit";
CM_ SG_ 285 BMS_ClntSys_Flt_Common "Coolant system fault
";
CM_ SG_ 285 BMS_Pump_DryRun_Err_Common "Pump Dry run Error";
CM_ SG_ 285 BMS_CrashDtct_P_F_Open_Common "Crash detected: Pyro fuse Open";
CM_ SG_ 285 BMS_HVIL_Err_Dischrg "BMS HVIL ERROR_discharge";
CM_ SG_ 285 BMS_No_Cntctr_Close "No contactor close";
CM_ SG_ 285 BMS_CntctrOpen_Rqst_VCU_Dischrg "Request Vcu to open conatctors in discharge";
CM_ SG_ 285 BMS_CntctrOpen_Rqst_VCU_Chrg "Request Vcu to open conatctors in charge ";
CM_ SG_ 285 BMS_InitCntctrOpen_Dischrg "BMS initiate conatctor open_discharge";
CM_ SG_ 285 BMS_InitCntctrOpen_Charge "BMS initiate conatctor open_charge";
CM_ SG_ 285 BMS_FSBIM_bAcvDrtdMode "Derate due to FusA- battery current monitoring function";
CM_ SG_ 285 BMS_FSPLP_bAcvDrtdMode "Derate due to pack level protection function";
CM_ SG_ 285 BMS_ILC_AcvDrtdCdn "Derate due to Current limit coordination";
CM_ SG_ 285 BMS_IDMStsIsInErr_Yellow "Derate due to DC isolation monitoring ";
CM_ SG_ 285 BMS_FSPLP_bAcvPackOverUDrtd "Derate due to pack level protection - Over current ";
CM_ SG_ 285 BMS_BIM_bAcvHighRateDchaDrdt2 "Dearte due to high rate discharge";
CM_ SG_ 285 BMS_FSPLP_bAcvPackUnderUDrtd "Derate due to pack level protection function - Under current ";
CM_ SG_ 285 BMS_BTFD_bAcvReqDrtdMode "Derate due to battery thermal fault handling";
CM_ SG_ 285 BMS_CUM_bAcvOwDrtd "Derate due to Cell volatge monitoring";
CM_ SG_ 285 BMS_CellOverVolt_Cutoff_Charge "Cell Over Volatge cutoff while Charging";
CM_ SG_ 285 BMS_Reason_HV_Disconnected "Reason for HV DisconnectReason for HV Disconnect";
CM_ SG_ 285 BMS_Reason_HV_Disconnect_Request "Reason for HV Disconnect RequestReason for HV Disconnect Request";
CM_ SG_ 285 BMS_Reason_Derating "Reason for derated modeReason for derated mode";
CM_ SG_ 920 STS_HIGHBEAM_BOOSTER "Highbeam booster status";
CM_ SG_ 920 HEADLAMP_AUTO_LEVEL "Head Lamp Auto Level  ";
CM_ SG_ 921 STS_HIGHBEAM_BOOSTER_1 "Highbeam booster status";
CM_ SG_ 771 DISP_AMBT_TEMP_FATC "Outside Temperature";
CM_ SG_ 1711 FOD_ALERT "User alert in case of FOD ( Foreign Object Detection)";
CM_ SG_ 1711 TIME_TO_CHARGE "Time to Charge";
CM_ SG_ 768 AUTO_RECIRC "It will indicate the about the status of auto recirculation mode.";
CM_ SG_ 768 AUTO_DEFROST "Auto defrost signal will indicate whether it is enable or disble. When there will be moisture in the window then hot air will be released according to the ambient temperature to defrost it.";
CM_ SG_ 1588 GP_CLOSE_RES_AC "Glasspanel smart close response for AC";
CM_ SG_ 1588 GP_CLOSE_RES_RAIN "Glasspanel smart close response for Rain";
CM_ BO_ 1586 "Seat Control Module";
CM_ SG_ 1586 SEAT_HEAT_VENT_LEVEL_SCM "seat heat/ vent level 
";
CM_ SG_ 1586 STS_HEATER "Heater ON / OFF Status";
CM_ SG_ 1586 SEAT_POSITION_FEEDBACK "Feedback signal ";
CM_ SG_ 1586 SCM_MEMORY_STS "Memory status based on SCM Memory Mode signal (Status will be update to fail or succeed)";
CM_ SG_ 1586 SCM_MEMORY_MODE "SCM Memory and Operation Mode";
CM_ SG_ 1586 HEATER_TEMP "Seat Heater Temperature";
CM_ SG_ 1586 POWER_SEAT_MEMORY_STORE "Power Seat Memory Store

3 seat positions  can be stored in 3 memories M (1, 2 and 3)";
CM_ SG_ 1586 POWER_SEAT_MEMORY_RECALL "Power Seat Memory Restore

Seat position  can be Restored based on stored position in memory";
CM_ SG_ 828 RLS_FW_BRIGHTNESS "RLS Forward Brightness";
CM_ SG_ 828 RLS_AMB_BRIGHTNESS "RLS Ambient Brightness";
CM_ SG_ 806 FPAS_ACTIVE_STS "FPAS Function Active Status";
CM_ SG_ 806 RPAS_ERROR "Bit 0 : Rear left corner
Bit 1 : Rear left center
Bit 2 : Rear right center
Bit 3 : Rear right corner
Bit 4 : ECU fault (RPAS not functional)

0 - No error
1 - Error";
CM_ SG_ 806 RPAS_DISP_DIST "RPAS Display distance";
CM_ SG_ 806 RPAS_ACTIVE_STS "RPAS Function Active Status";
CM_ SG_ 806 BAR_ZONE_RRC "RPAS Bar Zone value for RRC";
CM_ SG_ 806 BAR_ZONE_RR "RPAS Bar Zone value for RR";
CM_ SG_ 806 BAR_ZONE_RLC "RPAS Bar Zone value for RLC";
CM_ SG_ 806 BAR_ZONE_RL "RPAS Bar Zone value for RL";
CM_ SG_ 806 FPAS_DISP_DIST "FPAS Display distance";
CM_ SG_ 806 BAR_ZONE_FRC "FPAS Bar Zone value for FRC";
CM_ SG_ 806 BAR_ZONE_FLC "FPAS Bar Zone value for FLC";
CM_ SG_ 806 FPAS_ERROR "Bit 0 : Frent left corner
Bit 1 : Frent left center
Bit 2 : Frent right center
Bit 3 : Frent right corner
Bit 4 : ECU fault (FPAS not functional)

0 - No error
1 - Error";
CM_ SG_ 806 BAR_ZONE_FR "FPAS Bar Zone value for FR";
CM_ SG_ 806 BAR_ZONE_FL "FPAS Bar Zone value for FL";
CM_ SG_ 2029 DIAG_MBFM_RES_DATA "Keyword 2000 Diagnostic Message Response Data";
CM_ SG_ 1056 HEATER_INPUT_DC_VOLT "Input DC voltage";
CM_ BO_ 1001 "BMS Normal Signals 01";
CM_ SG_ 1001 BMS_ChargeVoltageLimit "Charge Voltage Limit of Battery Pack";
CM_ SG_ 1001 BMS_ChargeCurrentLimit "Charge current request from BMS  (AC / DC Charging Limitation of PACK)";
CM_ SG_ 1001 BMS_DischargeCurrentlimit "HV Battery allowable discharge current limit ";
CM_ SG_ 1168 EPT_RADIATORFAN_SPEED_REQ "EPT COOLING RADIATOR FAN SPEED REQUEST";
CM_ SG_ 1168 STS_EPT_RADIATORFAN "EPT COOLING RADIATOR FAN ON/ OFF REQUEST";
CM_ SG_ 1168 BATT_COOLING_REQ "BATTERY COOLING REQUEST";
CM_ SG_ 1168 BATT_COMPRES_SPD_REQ "BATTERY COMPRESSOR SPEED REQUEST TO ETC";
CM_ SG_ 159 VCU_WAKEUP_REASON "Reason for wake-up.
Need to defined
";
CM_ SG_ 943 VCU_ACTIVE_RESERVED "VCU EVCAN Active Reserved";
CM_ SG_ 743 REQUEST_RESPONSE_REVIVE "Response for Revive Request";
CM_ SG_ 743 MOTOR_PWR "Motor Power";
CM_ SG_ 743 RECUP_CTRL_STATE "Recuperation Inhibition to be updated even if Recup is disabled because of internal or NM faults. Indicates recuperation cannot happen in the vehicle as long as this is 1.";
CM_ SG_ 1416 SUNROOF_WINDOW_OPEN_IS "Sunroof & Window open during door unlock feature turn ON or OFF";
CM_ SG_ 1416 POWER_SEAT_RECALL_IS "Power Seat Recall ";
CM_ SG_ 250 IMMOVAL6 "MCM to PKE Handshaking Message";
CM_ SG_ 1408 AVH_FUNCTION_STS "AVH Function available status";
CM_ SG_ 1408 AVH_ACTIVE_STS "AVH function active status";
CM_ SG_ 1408 EPB_ALERT "Electronic Park Brake Alerts";
CM_ SG_ 1408 PARK_BRK_ACTIVE_STS "Electronic Park Brake Active Status";
CM_ SG_ 1408 RR_PARK_BRK_ACTIVE_STS "Rear Right Electronic Park Brake Active Status";
CM_ SG_ 1408 RL_PARK_BRK_ACTIVE_STS "Rear Left Electronic Park Brake Active Status";
CM_ SG_ 977 CABIN_HVAC_REQ "CABIN COOLING/ HEATING REQUEST";
CM_ SG_ 977 MCMTRG_R "Trigger from MCM to PKE,to wakeup pke to initiate authentication";
CM_ SG_ 532 TPMS_SYSTEM_FAULT "TPMS Malfunction Indication - Sensor Low Battery/ Transmitter Fault

Bit description
0      Front Left tyre
1      Front Right tyre
2      Rear Right tyre
3      Rear Left tyre
4      TPMS Receiver Fault

0 : Normal
1 : Faulty";
CM_ SG_ 532 TPMS_SIGNAL_MISSING "Bit Position Description :-
Bit 0 : FL tyre
Bit 1 : FR tyre
Bit 2 : RR tyre
Bit 3 : RL tyre

Value Description :-
0 : Normal
1 : Signal missing";
CM_ SG_ 532 TPMS_LEAKAGE_ALERT "Bit Position Description :-
Bit 0 : FL tyre
Bit 1 : FR tyre
Bit 2 : RR tyre
Bit 3 : RL tyre
Bit 4 : Spare tyre

Value Description :-
0 : Normal
1 : Leakage";
CM_ BO_ 843 "ESCL MESSAGE";
CM_ SG_ 843 ESCL1_CRC "CRC-Checksum over all signals for E2E-Protection";
CM_ SG_ 843 ESCL1_MSG_CNT "Message counter for E2E protection";
CM_ SG_ 843 ESCL_STEER_WHL_JAM_WRN "ESCL_Prompt_Rotate_Steer_Wheel - Prompt Drive to Rotate Steering Wheel
";
CM_ SG_ 843 ESCL_WRN_SFTY "Warning of Safety Failure";
CM_ SG_ 843 ESCL_WRN_FUNC "ESCL_Warn_function - Warning of Functional Failure";
BA_DEF_ SG_  "SignalType" STRING ;
BA_DEF_ SG_  "SignalCategory" HEX 10 15;
BA_DEF_ SG_  "GenSigTimeoutTime_IS" INT 0 65535;
BA_DEF_ SG_  "CmxSigDefaultRaw" HEX 0 2147483647;
BA_DEF_ SG_  "GwSigLatencyTime" INT 0 65535;
BA_DEF_ SG_  "GwSigMissingSourceType" ENUM  "Undef","OldValue","DefaultValue","InitialValue";
BA_DEF_ SG_  "GenSigEnvVarType" ENUM  "int","float","undef";
BA_DEF_ SG_  "GenSigEVName" STRING ;
BA_DEF_ SG_  "GenSigStartValue" INT 0 0;
BA_DEF_ SG_  "GenSigSendType" ENUM  "Cyclic","OnWrite","OnWriteWithRepetition","OnChange","OnChangeWithRepetition","IfActive","IfActiveWithRepetition","NoSigSendType";
BA_DEF_ SG_  "GenSigInactiveValue" INT 0 0;
BA_DEF_ SG_  "SigCreator" STRING ;
BA_DEF_ BO_  "NWM-Botschaft" ENUM  "nein","ja";
BA_DEF_ BO_  "GenMsgNrOfRepetitions" INT 1 999999;
BA_DEF_ BO_  "MsgCreator" STRING ;
BA_DEF_ BO_  "GenMsgTimeOut" INT 0 0;
BA_DEF_ BO_  "DiagState" ENUM  "No","Yes";
BA_DEF_ BO_  "DiagRequest" ENUM  "No","Yes";
BA_DEF_ BO_  "DiagResponse" ENUM  "No","Yes";
BA_DEF_ BO_  "TpTxIndex" INT 0 255;
BA_DEF_ BO_  "GenMsgILSupport" ENUM  "No","Yes";
BA_DEF_ BO_  "GenMsgNrOfRepetition" INT 0 3;
BA_DEF_ BO_  "GenMsgDelayTime" INT 0 0;
BA_DEF_ BO_  "GenMsgCycleTimeFast" INT 0 500;
BA_DEF_ BO_  "GenMsgStartDelayTime" INT 0 140;
BA_DEF_ BO_  "GenMsgSendType" ENUM  "Cyclic","Spontaneous","not_used","not_used","not_used","Cyclic","not_used","IfActive","NoMsgSendType";
BA_DEF_ BO_  "GenMsgCycleTime" INT 0 0;
BA_DEF_REL_ BU_SG_REL_  "GenSigTimeoutTime" INT 30 3500;
BA_DEF_DEF_  "SignalType" "";
BA_DEF_DEF_  "SignalCategory" 10;
BA_DEF_DEF_  "GenSigTimeoutTime_IS" 0;
BA_DEF_DEF_  "CmxSigDefaultRaw" 0;
BA_DEF_DEF_  "GwSigLatencyTime" 40;
BA_DEF_DEF_  "GwSigMissingSourceType" "Undef";
BA_DEF_DEF_  "GenSigEnvVarType" "undef";
BA_DEF_DEF_  "GenSigEVName" "";
BA_DEF_DEF_  "GenSigStartValue" 0;
BA_DEF_DEF_  "GenSigSendType" "Cyclic";
BA_DEF_DEF_  "GenSigInactiveValue" 0;
BA_DEF_DEF_  "SigCreator" "M&M-IVN";
BA_DEF_DEF_  "NWM-Botschaft" "nein";
BA_DEF_DEF_  "GenMsgNrOfRepetitions" 1;
BA_DEF_DEF_  "MsgCreator" "M&M-IVN";
BA_DEF_DEF_  "GenMsgTimeOut" 0;
BA_DEF_DEF_  "DiagState" "No";
BA_DEF_DEF_  "DiagRequest" "No";
BA_DEF_DEF_  "DiagResponse" "No";
BA_DEF_DEF_  "TpTxIndex" 0;
BA_DEF_DEF_  "GenMsgILSupport" "Yes";
BA_DEF_DEF_  "GenMsgNrOfRepetition" 0;
BA_DEF_DEF_  "GenMsgDelayTime" 0;
BA_DEF_DEF_  "GenMsgCycleTimeFast" 0;
BA_DEF_DEF_  "GenMsgStartDelayTime" 0;
BA_DEF_DEF_  "GenMsgSendType" "Cyclic";
BA_DEF_DEF_  "GenMsgCycleTime" 0;
BA_DEF_DEF_REL_ "GenSigTimeoutTime" 1400;
BA_ "GenMsgCycleTime" BO_ 577 20;
BA_ "GenMsgCycleTime" BO_ 822 100;
BA_ "GenMsgCycleTime" BO_ 437 10;
BA_ "GenMsgCycleTime" BO_ 601 20;
BA_ "GenMsgCycleTime" BO_ 1731 100;
BA_ "GenMsgCycleTime" BO_ 1481 500;
BA_ "GenMsgCycleTime" BO_ 988 100;
BA_ "GenMsgCycleTime" BO_ 1480 500;
BA_ "GenMsgCycleTime" BO_ 983 100;
BA_ "GenMsgCycleTime" BO_ 280 10;
BA_ "GenMsgCycleTime" BO_ 1016 200;
BA_ "DiagResponse" BO_ 1918 1;
BA_ "GenMsgSendType" BO_ 1918 1;
BA_ "DiagRequest" BO_ 1910 1;
BA_ "GenMsgSendType" BO_ 1910 1;
BA_ "GenMsgCycleTime" BO_ 1015 200;
BA_ "GenMsgCycleTime" BO_ 1014 200;
BA_ "GenMsgCycleTime" BO_ 993 100;
BA_ "GenMsgCycleTime" BO_ 824 100;
BA_ "GenMsgCycleTime" BO_ 1474 500;
BA_ "GenMsgCycleTime" BO_ 1736 1000;
BA_ "GenMsgCycleTime" BO_ 1012 100;
BA_ "GenMsgCycleTime" BO_ 1006 100;
BA_ "GenMsgCycleTime" BO_ 984 100;
BA_ "GenMsgCycleTime" BO_ 1064 100;
BA_ "GenMsgCycleTime" BO_ 986 100;
BA_ "GenMsgCycleTime" BO_ 1479 500;
BA_ "GenMsgCycleTime" BO_ 283 10;
BA_ "GenMsgCycleTime" BO_ 982 100;
BA_ "GenMsgCycleTime" BO_ 1478 500;
BA_ "GenMsgCycleTime" BO_ 1477 500;
BA_ "GenMsgCycleTime" BO_ 578 20;
BA_ "GenMsgCycleTime" BO_ 1475 500;
BA_ "GenMsgCycleTime" BO_ 1002 100;
BA_ "GenMsgCycleTime" BO_ 980 100;
BA_ "GenMsgCycleTime" BO_ 978 100;
BA_ "GenMsgTimeOut" BO_ 626 10;
BA_ "GenMsgCycleTime" BO_ 626 30;
BA_ "GenMsgCycleTime" BO_ 337 50;
BA_ "GenMsgCycleTime" BO_ 1720 10;
BA_ "GenMsgCycleTime" BO_ 1655 500;
BA_ "GenMsgCycleTime" BO_ 339 100;
BA_ "GenMsgCycleTime" BO_ 338 100;
BA_ "GenMsgCycleTime" BO_ 1761 100;
BA_ "GenMsgCycleTime" BO_ 999 100;
BA_ "GenMsgCycleTime" BO_ 1000 100;
BA_ "GenMsgSendType" BO_ 2005 1;
BA_ "GenMsgSendType" BO_ 2013 1;
BA_ "GenMsgTimeOut" BO_ 1652 2500;
BA_ "GenMsgCycleTime" BO_ 1652 500;
BA_ "GenMsgCycleTime" BO_ 374 20;
BA_ "GenMsgTimeOut" BO_ 264 100;
BA_ "GenMsgCycleTime" BO_ 264 10;
BA_ "DiagResponse" BO_ 1919 1;
BA_ "GenMsgSendType" BO_ 1919 1;
BA_ "DiagRequest" BO_ 1911 1;
BA_ "GenMsgSendType" BO_ 1911 1;
BA_ "DiagState" BO_ 1980 1;
BA_ "GenMsgSendType" BO_ 1980 1;
BA_ "GenMsgSendType" BO_ 2008 1;
BA_ "GenMsgCycleTime" BO_ 579 20;
BA_ "GenMsgSendType" BO_ 936 1;
BA_ "DiagState" BO_ 1933 1;
BA_ "GenMsgSendType" BO_ 1933 1;
BA_ "DiagState" BO_ 1981 1;
BA_ "GenMsgSendType" BO_ 1981 1;
BA_ "DiagState" BO_ 1976 1;
BA_ "GenMsgSendType" BO_ 1976 1;
BA_ "DiagState" BO_ 1972 1;
BA_ "DiagRequest" BO_ 1972 1;
BA_ "GenMsgSendType" BO_ 1972 1;
BA_ "DiagState" BO_ 1925 1;
BA_ "DiagRequest" BO_ 1925 1;
BA_ "GenMsgSendType" BO_ 1925 1;
BA_ "DiagState" BO_ 1973 1;
BA_ "DiagRequest" BO_ 1973 1;
BA_ "GenMsgSendType" BO_ 1973 1;
BA_ "DiagState" BO_ 2000 1;
BA_ "DiagRequest" BO_ 2000 1;
BA_ "GenMsgSendType" BO_ 2000 1;
BA_ "DiagState" BO_ 1968 1;
BA_ "DiagRequest" BO_ 1968 1;
BA_ "GenMsgSendType" BO_ 1968 1;
BA_ "GenMsgCycleTime" BO_ 336 50;
BA_ "GenMsgCycleTime" BO_ 285 10;
BA_ "DiagRequest" BO_ 1954 1;
BA_ "GenMsgSendType" BO_ 1954 1;
BA_ "DiagResponse" BO_ 1962 1;
BA_ "GenMsgSendType" BO_ 1962 1;
BA_ "GenMsgCycleTime" BO_ 920 100;
BA_ "GenMsgCycleTime" BO_ 921 100;
BA_ "GenMsgCycleTime" BO_ 667 100;
BA_ "GenMsgCycleTime" BO_ 654 100;
BA_ "GenMsgCycleTime" BO_ 662 100;
BA_ "GenMsgCycleTime" BO_ 771 200;
BA_ "GenMsgCycleTime" BO_ 809 100;
BA_ "GenMsgCycleTime" BO_ 1711 2000;
BA_ "GenMsgCycleTime" BO_ 768 200;
BA_ "GenMsgCycleTime" BO_ 1588 1000;
BA_ "GenMsgCycleTime" BO_ 1586 500;
BA_ "GenMsgCycleTime" BO_ 828 100;
BA_ "GenMsgCycleTime" BO_ 806 50;
BA_ "DiagResponse" BO_ 2029 1;
BA_ "GenMsgSendType" BO_ 2029 1;
BA_ "GenMsgCycleTime" BO_ 536 100;
BA_ "GenMsgCycleTime" BO_ 1056 200;
BA_ "GenMsgCycleTime" BO_ 940 100;
BA_ "GenMsgCycleTime" BO_ 1001 100;
BA_ "GenMsgCycleTime" BO_ 1168 200;
BA_ "DiagResponse" BO_ 1865 1;
BA_ "GenMsgSendType" BO_ 1865 1;
BA_ "DiagRequest" BO_ 1857 1;
BA_ "GenMsgILSupport" BO_ 1857 0;
BA_ "GenMsgDelayTime" BO_ 1857 5;
BA_ "GenMsgSendType" BO_ 1857 1;
BA_ "GenMsgCycleTime" BO_ 965 100;
BA_ "GenMsgCycleTime" BO_ 159 20;
BA_ "GenMsgNrOfRepetition" BO_ 942 1;
BA_ "GenMsgSendType" BO_ 942 1;
BA_ "GenMsgCycleTime" BO_ 943 100;
BA_ "GenMsgCycleTime" BO_ 954 100;
BA_ "GenMsgCycleTime" BO_ 564 100;
BA_ "GenMsgCycleTime" BO_ 743 50;
BA_ "GenMsgCycleTime" BO_ 1416 500;
BA_ "GenMsgCycleTime" BO_ 812 100;
BA_ "GenMsgSendType" BO_ 250 1;
BA_ "GenMsgCycleTime" BO_ 1408 500;
BA_ "GenMsgCycleTime" BO_ 977 100;
BA_ "GenMsgCycleTime" BO_ 958 100;
BA_ "GenMsgCycleTime" BO_ 976 100;
BA_ "GenMsgCycleTime" BO_ 532 100;
BA_ "GenMsgCycleTime" BO_ 843 100;
BA_ "GenSigStartValue" SG_ 822 VCU_EPTCoolantTemp 40;
BA_ "GenSigStartValue" SG_ 1731 VCU_CharInletTempNeg 40;
BA_ "GenSigStartValue" SG_ 1731 VCU_CharInletTempPos 40;
BA_ "GenSigStartValue" SG_ 988 OBC_PFC_VOLT_CNTRL_IP 30;
BA_ "GenSigStartValue" SG_ 983 MCU_Motor_Temp_Indicator 50;
BA_ "GenSigStartValue" SG_ 983 MCU_Inverter_Temp_Indicator 50;
BA_ "GenSigStartValue" SG_ 280 MCU_MotorSpeed 7;
BA_ "GenSigStartValue" SG_ 280 MCU_MotorTorqueEstimated 48;
BA_ "GenSigStartValue" SG_ 1015 BMS_HTR_CLT_HVInput_V 8;
BA_ "GenSigStartValue" SG_ 984 OBC_Line_Frequency 40;
BA_ "GenSigStartValue" SG_ 986 OBC_SecondarySide_Temperature 550;
BA_ "GenSigStartValue" SG_ 986 OBC_Transformer_Temperature 550;
BA_ "GenSigStartValue" SG_ 986 OBC_PrimarySide_Temperature 550;
BA_ "GenSigStartValue" SG_ 982 MCU_HighPowerCurrent 8184;
BA_ "GenSigStartValue" SG_ 978 BMS_BHeaterOpCoolantTemp 680;
BA_ "GenSigStartValue" SG_ 978 BMS_BatteryOutletCoolantTemp 680;
BA_ "GenSigStartValue" SG_ 978 BMS_BatteryInletCoolantTempReq 680;
BA_ "GenSigStartValue" SG_ 978 BMS_BatteryInletCoolantTemp 680;
BA_ "GenSigStartValue" SG_ 626 BMS_BatteryTBatt 680;
BA_ "GenSigStartValue" SG_ 337 BMS_Current2sensorReading 6000;
BA_ "GenSigStartValue" SG_ 337 BMS_Current1sensorReading 6000;
BA_ "GenSigStartValue" SG_ 1655 CLOCK_YEAR_TGU 16;
BA_ "GenSigStartValue" SG_ 339 TGU_CHARGINGSTARTTIME_YEAR 16;
BA_ "GenSigStartValue" SG_ 339 TGU_CHARGINGENDTIME_YEAR 16;
BA_ "GenSigStartValue" SG_ 338 TGU_TRIPSTARTTIME_YEAR 16;
BA_ "GenSigStartValue" SG_ 338 TGU_TRIPENDTIME_YEAR 16;
BA_ "GenSigStartValue" SG_ 999 BMS_BatteryMaxCellVoltage 3650;
BA_ "GenSigStartValue" SG_ 999 BMS_BatteryMinCellVoltage 3650;
BA_ "GenSigSendType" SG_ 2005 DIAG_TGU_REQ_DATA 7;
BA_ "GenSigSendType" SG_ 2013 DIAG_TGU_RES_DATA 7;
BA_ "GenSigSendType" SG_ 374 TGS_MODE_AMT 7;
BA_ "GenSigEnvVarType" SG_ 374 TGS_MODE_AMT 0;
BA_ "SignalType" SG_ 374 TGS_MODE_AMT "ENM";
BA_ "SignalType" SG_ 374 GEAR_ACTUAL_AMT "ENM";
BA_ "GenSigSendType" SG_ 264 INTAKE_AIR_TEMP 7;
BA_ "GenSigStartValue" SG_ 264 INTAKE_AIR_TEMP 40;
BA_ "GenSigStartValue" SG_ 264 DRIVER_DEMAND_TRQ 1024;
BA_ "GenSigStartValue" SG_ 771 DISP_AMBT_TEMP_FATC 40;
BA_ "CmxSigDefaultRaw" SG_ 771 DISP_AMBT_TEMP_FATC 255;
BA_ "GenSigSendType" SG_ 768 INCAR_TEMP 7;
BA_ "GenSigStartValue" SG_ 1586 HEATER_TEMP 40;
BA_ "GenSigSendType" SG_ 2029 DIAG_MBFM_RES_DATA 7;
BA_ "GenSigSendType" SG_ 965 RESERVED_2 7;
BA_ "GenSigSendType" SG_ 942 RESERVED_2 7;
BA_ "GenSigSendType" SG_ 564 RESERVED_2 7;
BA_ "GenSigStartValue" SG_ 743 MOTOR_PWR 32768;
BA_ "GenSigStartValue" SG_ 743 POWER_REGEN_METER 100;
BA_ "GenSigSendType" SG_ 958 RESERVED_2 7;
VAL_ 577 VCU_ExMeDi_IdxDcChrgnErr 10 "SCC_StackError" 9 "Active battery charging stop request" 8 "Inlet temperature exceeded indicator" 7 "Current set-point error after delay" 6 "Voltage set-point error after delay" 5 "EVCE_DataInconsistencyError" 4 "Timeout indicator for the charging session" 3 "Battery statusTriggered emergencyPowerdown" 2 "reportedstatusofEVSE triggered critical error." 1 "Ext Mean Diagn ErrorStateMachineCritical" 0 "Ext Mean Diagn ErrorStateMachineStatus" ;
VAL_ 577 VCU_RespCod 23 "FAILED_MeteringSignatureNotValid" 22 "FAILED_PowerDeliveryNotApplied" 21 "FAILED_EVSEPresentVoltageToLow" 20 "FAILED_TariffSelectionInvalid" 19 "FAILED_ChargingProfileInvalid" 18 "FAILED_WrongChargeParameter" 17 "FAILED_WrongEnergyTransferType" 16 "FAILED_ChallengeInvalid" 15 "FAILED_ContractCanceled" 14 "FAILED_CertChainError" 13 "FAILED_NoCertificateAvailable" 12 "FAILED_CertificateExpired" 11 "FAILED_ServiceSelectionInvalid" 10 "FAILED_PaymentSelectionInvalid" 9 "FAILED_ServiceIDInvalid" 8 "FAILED_UnknownSession" 7 "FAILED_SignatureError" 6 " FAILED_SequenceError" 5 "FAILED" 4 "OK_OldSessionJoined" 3 "OK_NewSessionEstablished" 2 "OK_CertificateExpiresSoon" 1 "OK" 0 "None" ;
VAL_ 577 VCU_MsgSts 32 "SLAC Failed" 31 "SLAC OK" 30 "Close communication Failed

" 29 "Close communication OK" 28 "SessionStop Failed

" 27 "SessionStop OK" 26 "WeldingDetection Failed

" 25 "WeldingDetection OK" 24 "CurrentDemand Failed" 23 "CurrentDemand OK" 22 "PowerDelivery Failed

" 21 "PowerDelivery OK" 20 "Precharge Failed" 19 " Precharge OK

" 18 "CableCheckFailed

" 17 "CableCheck OK" 16 "ChargeParameterDiscovery Failed" 15 "ChargeParameterDiscovery OK

" 14 "ContractAuthentication Failed" 13 "ContractAuthentication OK" 12 "ServicePaymentSelection Failed" 11 "ServicePaymentSelection OK" 10 " ServiceDiscovery Failed" 9 "ServiceDiscovery OK

" 8 "SessionSetup Failed" 7 "SessionSetup OK

" 6 "SupportedAppProtocol Failed" 5 "SupportedAppProtocol OK" 4 "TCP Failed" 3 "TCP OK" 2 "SDP Failed" 1 "SDP OK" 0 "None" ;
VAL_ 577 VCU_Charge_Discharge_Trans 3 "Signal Invalid" 2 "Charge to Discharge" 1 "Discharge to charge" 0 "Default" ;
VAL_ 577 VCU_TransPmotorparkReq 3 "InValid" 2 "Park Request" 1 "Unpark Request" 0 "NoRequest/Default" ;
VAL_ 577 VCU_eComp_HVIL_Status 3 "Signal Invalid" 2 "Reserved" 1 "Open/Fault" 0 "Closed/No Fault" ;
VAL_ 577 VCU241_Checksum 0 "Default Value" ;
VAL_ 577 VCU241_COUNTER 0 "Default Value" ;
VAL_ 577 VCU_SRSCrashSta 0 "No Request Default Value" 1 "Crash / Request to STOP" ;
VAL_ 822 VCU_AUX_BATTERY_VOLT 255 "Signal Invalid" 0 "Default value" ;
VAL_ 822 VCU_Vehicle_Speed 65535 "Signal Invalid" 0 "Default" ;
VAL_ 822 VCU_STS_IGN 7 "Signal Invalid" 6 "Reserved" 5 "Reserved" 4 "Reserved" 3 "Ignition KL 15/Default value" 2 "Reserved" 1 "Reserved" 0 "Reserved" ;
VAL_ 822 VCU_EPTCoolantTemp 70 "Default Value" 255 "Signal Invalid" ;
VAL_ 822 VCU_EPTCoolantFlow 0 "Default Value" ;
VAL_ 822 VCU_EVReady 3 "Signal Invalid" 2 "Emergency (Blinking)" 1 "Ready" 0 "Not Ready/Default" ;
VAL_ 437 VCU_BMS_ASW_SleepRequest 7 "Reserved" 6 "Reserved" 5 "Reserved" 4 "Reserved" 3 "Reserved" 2 "Reserved" 1 "Initiate Sleep" 0 "Deafult" ;
VAL_ 437 VCU_SmObc_State 0 "Default Value" ;
VAL_ 437 VCU_Wakeup_Reason_internal 15 "Invalid" 14 "Reserved" 13 "Reserved" 12 "Reserved" 11 "Reserved" 10 "Reserved" 9 "Reserved" 8 "Reserved" 7 "Reserved" 6 "DCAN" 5 "CAN Wakeup - VCAN" 4 "CAN Wakeup - EVCAN" 3 "Scheduled wakeup (AUX_UV_VOLT)" 2 "PP" 1 "IGN" 0 "No Wakeup" ;
VAL_ 437 VCU_NoSM_State 0 "Default Value" ;
VAL_ 437 VCU_EVCSI_State 0 "Default Value" ;
VAL_ 437 VCU_CharPD_RawVal 255 "Signl Invalid" ;
VAL_ 437 VCU_CharCP_RawVal 255 "Signl Invalid" ;
VAL_ 601 VCU_StsIslnEvse 3 " Fault" 2 "Warning" 1 "Valid" 0 "Invalid" ;
VAL_ 601 VCU_LV_Battery_Voltage 135 "Default Value" ;
VAL_ 601 VCU_brake2_voltage 0 "Default Value" ;
VAL_ 601 VCU_brake1_voltage 0 "Default Value" ;
VAL_ 601 VCU_Accep2_voltage 0 "Default Value" ;
VAL_ 601 VCU_Accep1_voltage 0 "Default Value" ;
VAL_ 1731 VCU_CharInletTempNeg 65 "Default Value" ;
VAL_ 1731 VCU_PumpSpdFb 127 "Signal Invalid" ;
VAL_ 1731 VCU_PumpSpdCtrl 127 "Signal Invalid" ;
VAL_ 1731 VCU_CoolFanSpdCtrl 127 "Signal Invalid" ;
VAL_ 1731 VCU_CharPlugLockFbSts 1 "Lock" 0 "Unlock" ;
VAL_ 1731 VCU_CharPlugLockCtrlSts 2 "Unlock" 1 "Lock" 0 "Hold" ;
VAL_ 1731 VCU_CharPlugAtLockSwIndSts 1 "ON" 0 "OFF" ;
VAL_ 1731 VCU_CharInletTempPos 65 "Default Value" ;
VAL_ 1481 VCU_COMFLT_MSG_CONTFAIL 3 "Reserved" 2 "MCF DTC Healed State" 1 "MCF DTC Current State" 0 "Default/No DTC" ;
VAL_ 1481 VCU_COMFLT_SGN_CONTFAIL 3 "Reserved" 2 "SCF DTC Healed State" 1 "SCF DTC Current State" 0 "Deault/No DTC" ;
VAL_ 1481 VCU_AUX_BATT_VOLT 0 "Default" ;
VAL_ 1481 VCU_UV_STS 1 "Active" 0 "Inactive/Default" ;
VAL_ 1481 VCU_STS_IGN_NM 1 "IGN on" 0 "IGN Off/Default" ;
VAL_ 1481 VCU_OV_STS 1 "Active" 0 "Inactive/Default" ;
VAL_ 1481 VCU_COMFLT_NODEABS_STS 3 "Reserved" 2 "NA DTC Healed State" 1 "NA DTC Current State" 0 "Default/no DTC" ;
VAL_ 1481 VCU_VARIANT_CODE_ERR_STS 3 "Reserved" 2 "VC DTC in Healed State" 1 "VC DTC in current state" 0 "Default" ;
VAL_ 1481 VCU_NM_ACTIVE_STS 7 "NM Active" 6 "Disabled due to IGN off" 5 "Disabled due to bus off" 4 "Disabled due to over voltage" 3 "Disabled due to under voltage" 2 "Disabled due to Cranking T50/ESS" 1 "Disabled due to VC" 0 "Diabled due to IGN On/Default" ;
VAL_ 1481 VCU_FEATURE_CODE_ERR_STS 3 "Reserved" 2 "FC DTC in Healed State" 1 "FC DTC in current state" 0 "Default" ;
VAL_ 1481 VCU_COMFLT_MSGTOUT_STS 3 "Reserved" 2 "MTO DTC in Healed State" 1 "MTO DTC in current state" 0 "Default/No DTC" ;
VAL_ 988 OBC_VIN_MISMATCH_FAULT 1 "Fault" 0 "No Fault/Default" ;
VAL_ 988 OBC_ECU_RESET_FAULT 1 "Fault" 0 "No Fault/Default" ;
VAL_ 988 OBC_Low_Temp_Shutdown 1 "Fault" 0 "Default/No fault" ;
VAL_ 988 OBC_HVDC_HW_OV 1 "Fault" 0 "Default/No fault" ;
VAL_ 988 OBC_CPVol_Out_of_Range 1 "Fault" 0 "Default/No fault" ;
VAL_ 988 OBC_CPDuty_Out_of_Range 1 "Fault" 0 "Default/No fault" ;
VAL_ 988 OBC_HVDC_HW_OC 1 "Fault" 0 "Default/No fault" ;
VAL_ 988 OBC_PRECHARGE_FAULT_CNT 7 "Signal Invalid" 0 "Default" ;
VAL_ 988 OBC_PFC_BUS_FAULT_CNT 7 "Signal Invalid" 0 "Default" ;
VAL_ 988 OBC_PFC_VOLT_CNTRL_IP 255 "Signal Invalid" 0 "Default" ;
VAL_ 988 OBC_LIne_OC_SW 1 "Fault" 0 "Default/ No fault" ;
VAL_ 988 OBC_VPROG_OUT_OF_RANGE 1 "Fault/Warning" 0 "Default/No Fault" ;
VAL_ 988 OBC_TEMP_SENSOR_FAIL 1 "Fault/Warning" 0 "Default/No Fault" ;
VAL_ 988 OBC_OVER_TEMP 1 "Fault/Warning" 0 "Default/No Fault" ;
VAL_ 988 OBC_INTERNAL_FAIL 1 "Fault/Warning" 0 "Default/No Fault" ;
VAL_ 988 OBC_HIGH_TEMP 1 "Fault/Warning" 0 "Default/No Fault" ;
VAL_ 988 OBC_IPROG_OUT_OF_RANGE 1 "Fault/Warning" 0 "Default/No Fault" ;
VAL_ 988 OBC_EMI_IP_UV 1 "Fault/Warning" 0 "Default/No Fault" ;
VAL_ 988 OBC_EMI_IP_OV 1 "Fault/Warning" 0 "Default/No Fault" ;
VAL_ 988 OBC_EEPROM_FAIL 1 "Fault/Warning" 0 "Default/No Fault" ;
VAL_ 988 OBC_CAN_BUS_OFF 1 "Fault/Warning" 0 "Default/No Fault" ;
VAL_ 988 OBC_TEMP_DERATE 1 "Fault/Warning" 0 "Default/No Fault" ;
VAL_ 988 OBC_PRE_CHARGE_FAULT 1 "Fault/Warning" 0 "Default/No Fault" ;
VAL_ 988 OBC_PFV_OV 1 "Fault/Warning" 0 "Default/No Fault" ;
VAL_ 988 OBC_PFC_UV 1 "Fault/Warning" 0 "Default/No Fault" ;
VAL_ 988 OBC_PFC_OVER_TEMP 1 "Fault/Warning" 0 "Default/No Fault" ;
VAL_ 988 OBC_OP_UV 1 "Fault/Warning" 0 "Default/No Fault" ;
VAL_ 988 OBC_OP_OV 1 "Fault/Warning" 0 "Default/No Fault" ;
VAL_ 988 OBC_OP_OC 1 "Fault/Warning" 0 "Default/No Fault" ;
VAL_ 988 OBC_LV_UNDER_VOLT 1 "Fault/Warning" 0 "Default/No Fault" ;
VAL_ 988 OBC_LV_OVER_VOLT 1 "Fault/Warning" 0 "Default/No Fault" ;
VAL_ 988 OBC_LLC_OVER_TEMP 1 "Fault/Warning" 0 "Default/No Fault" ;
VAL_ 988 OBC_IP_UNDER_VOLT 1 "Fault/Warning" 0 "Default/No Fault" ;
VAL_ 988 OBC_IP_OVER_VOLT 1 "Fault/Warning" 0 "Default/No Fault" ;
VAL_ 988 OBC_IP_OVER_CURR 1 "Fault/Warning" 0 "Default/No Fault" ;
VAL_ 988 OBC_IP_DERATE 1 "Fault/Warning" 0 "Default/No Fault" ;
VAL_ 1480 OBC_COMFLT_SGN_CONTFAIL 3 "Reserved" 2 "SCF DTC Healed State" 1 "SCF DTC Current State" 0 "Deault/No DTC" ;
VAL_ 1480 OBC_UV_STS 1 "Active" 0 "Inactive/Default" ;
VAL_ 1480 OBC_STS_IGN_NM 1 "IGN on" 0 "IGN Off/Default" ;
VAL_ 1480 OBC_OV_STS 1 "Active" 0 "Inactive/Default" ;
VAL_ 1480 OBC_AUX_BATT_VOLT 0 "Default" ;
VAL_ 1480 OBC_COMFLT_MSG_CONTFAIL 3 "Reserved" 2 "MCF DTC Healed State" 1 "MCF DTC Current State" 0 "Default/No DTC" ;
VAL_ 1480 OBC_COMFLT_NODEABS_STS 3 "Reserved" 2 "NA DTC Healed State" 1 "NA DTC Current State" 0 "Default/no DTC" ;
VAL_ 1480 OBC_NM_ACTIVE_STS 7 "NM ACTIVE" 6 "Disabled due to IGN off" 5 "Disabled due to bus off" 4 "Disabled due to over voltage" 3 "Disabled due to under voltage" 2 "Disabled due to Cranking T50/ESS" 1 "Disabled due to VC" 0 "Diabled due to IGN On/Default" ;
VAL_ 1480 OBC_VARIANT_CODE_ERR_STS 3 "Reserved" 2 "VC DTC in Healed State" 1 "VC DTC in current state" 0 "Default" ;
VAL_ 1480 OBC_FEATURE_CODE_ERR_STS 3 "Reserved" 2 "FC DTC in Healed State" 1 "FC DTC in current state" 0 "Default" ;
VAL_ 1480 OBC_COMFLT_MSGTOUT_STS 3 "Reserved" 2 "MTO DTC in Healed State" 1 "MTO DTC in current state" 0 "Default/No DTC" ;
VAL_ 983 MCU_MotorCoolingFlowReq 255 "Default value" ;
VAL_ 983 MCU_Motor_Temp_Indicator 255 "Default Value" ;
VAL_ 983 MCU_Inverter_Temp_Indicator 255 "Default Value" ;
VAL_ 983 MCU_Inverter_CoolingFlowReq 0 "Default Value" 255 "Signal Invalid" ;
VAL_ 280 MCU118_COUNTER 0 "Default Value" ;
VAL_ 280 MCU118_Checksum 0 "Default Value" ;
VAL_ 280 MCU_MotorSpeed 65535 "Default Value" ;
VAL_ 280 MCU_MotorTorqueEstimated 65535 "Default Value" ;
VAL_ 824 VCU_CmdACChargeTargetVolt 16383 "Signal Invalid" 0 "Default Value" ;
VAL_ 824 VCU_CmdEnableOBC 3 "Invalid" 2 "Reserved" 1 "Enable" 0 "Disable / Initial Value/Default" ;
VAL_ 824 VCU_CmdACChargeTargetCurrent 4095 "Signal Invalid" 0 "Default Value" ;
VAL_ 824 VCU_ACChargingReady 3 "Signal Invalid" 2 "Charging Finish" 1 "Ready" 0 "NotReady/Default" ;
VAL_ 1474 VCU_AVAIL_BAT_HEATER_PWR 0 "Default Value" ;
VAL_ 1736 VCU_EConsDistSample4 65535 "Invalid" 0 "Default" ;
VAL_ 1736 VCU_EConsDistSample3 65535 "Invalid" 0 "Default" ;
VAL_ 1736 VCU_EConsDistSample2 65535 "Invalid" 0 "Default" ;
VAL_ 1736 VCU_EConsDistSample1 65535 "Invalid" 0 "Default" ;
VAL_ 1012 VCU_DcChargingSequence 8 "TCP Disconnected" 7 "Session Stop" 6 "Welding Detection" 5 "Charging" 4 "Precharge" 3 "Cable Check" 2 "Initialization" 1 "Connecte" 0 "Disconnected" ;
VAL_ 1012 VCU_SBWS_BuFb_RawVal 127 "Signal Invalid" ;
VAL_ 1012 VCU_SBWS_Bu_RawVal 127 "Signal Invalid" ;
VAL_ 1012 VCU_PumpRlyCtrlSts 1 "ON" 0 "OFF" ;
VAL_ 1006 VCU_QkCharPosRlyFblSts 1 "ON" 0 "OFF" ;
VAL_ 1006 VCU_QkCharPosRlyCtrlSts 1 "ON" 0 "OFF" ;
VAL_ 1006 VCU_QkCharNegRlyFblSts 1 "ON" 0 "OFF" ;
VAL_ 1006 VCU_QkCharNegRlyCtrlSts 1 "ON" 0 "OFF" ;
VAL_ 1006 VCU_CharIndRedCtrlSts 127 "Signal Invalid" ;
VAL_ 1006 VCU_CharIndGrCtrlSts 127 "Signal Invalid" ;
VAL_ 1006 VCU_CharIndBlCtrlSts 127 "Signal Invalid" ;
VAL_ 984 OBC_PFC_Voltage 65535 "Signal invalid" 0 "Default Value" ;
VAL_ 984 OBC_DCVoltageCapable 65535 "Default Value" ;
VAL_ 984 OBC_DCCurrentCapable 65535 "Default Value" ;
VAL_ 1064 OBC_PowerDeratingSta 7 "Signal Invalid" 6 "Reserved" 5 "Reserved" 4 "Reserved" 3 "Reserved" 2 "Power Derating-Input Voltage" 1 "Power Derating-Temperature" 0 "No Power Derating/Default" ;
VAL_ 1064 OBC_OperatingMode 7 "Reserved" 6 "Reserved" 5 "Fault" 4 "Power Derated" 3 "Charging" 2 "Ready / No Charge" 1 "Wake up" 0 "Init Mode/Default" ;
VAL_ 1064 OBC_ACDetectSta 1 "Yes" 0 "No/Default" ;
VAL_ 986 OBC_SecondarySide_Temperature 4095 "Signal Invalid" 820 "Default Value" ;
VAL_ 986 OBC_Transformer_Temperature 4095 "Signal Invalid" 820 "Default Value" ;
VAL_ 986 OBC_CoolingRequest 0 "Default" 255 "Signal Invalid" ;
VAL_ 986 OBC_PrimarySide_Temperature 4095 "Signal Invalid" 820 "Default" ;
VAL_ 986 OBC_LV_PwrSupply 32767 "Signal Invalid" 0 "Default Value" ;
VAL_ 1479 MCU_SW_Version_Internal 0 "Default" ;
VAL_ 1479 MCU_COMFLT_SGN_CONTFAIL 3 "Reserved" 2 "SCF DTC Healed State" 1 "SCF DTC Current State" 0 "Deault/No DTC" ;
VAL_ 1479 MCU_OV_STS 1 "Active" 0 "Inactive/Default" ;
VAL_ 1479 MCU_UV_STS 1 "Active" 0 "Inactive/Default" ;
VAL_ 1479 MCU_STS_IGN 1 "IGN on" 0 "IGN Off/Default" ;
VAL_ 1479 MCU_AUX_BATT_VOLT 0 "Default" ;
VAL_ 1479 MCU_COMFLT_MSG_CONTFAIL 3 "Reserved" 2 "MCF DTC Healed State" 1 "MCF DTC Current State" 0 "Default/No DTC" ;
VAL_ 1479 MCU_NM_ACTIVE_STS 7 "NM Active" 6 "Disabled due to IGN off" 5 "Disabled due to bus off" 4 "Disabled due to over voltage" 3 "Disabled due to under voltage" 2 "Disabled due to Cranking T50/ESS" 1 "Disabled due to VC" 0 "Diabled due to IGN On/Default" ;
VAL_ 1479 MCU_COMFLT_NODEABS_STS 3 "Reserved" 2 "NA DTC Healed State" 1 "NA DTC Current State" 0 "Default/no DTC" ;
VAL_ 1479 MCU_COMFLT_MSGTOUT_STS 3 "Reserved" 2 "MTO DTC in Healed State" 1 "MTO DTC in current state" 0 "Default/No DTC" ;
VAL_ 283 MCU11B_Checksum 0 "Default Value" ;
VAL_ 283 MCU11B_COUNTER 0 "Default Value" ;
VAL_ 283 MCU_ErrorLevel 7 "Invalid" 6 "Reserved" 5 "Lv5" 4 "Lv4" 3 "Lv3" 2 "Lv2" 1 "Lv1" 0 "Lv0 " ;
VAL_ 283 MCU_ActiveDamping 3 "Signal Invalid" 2 "Reserved" 1 "Off" 0 "On/Default" ;
VAL_ 283 MCU_OperationalMode 7 "Signal Invalid" 6 "Reserved" 5 "Reserved" 4 "Reserved" 3 "EV" 2 "Reserved" 1 "Reserved" 0 "Neutral/Default" ;
VAL_ 283 MCU_CommandMode 7 "Invalid Value" 6 "Reserved" 5 "Reserved" 4 "Reserved" 3 "Reserved" 2 "Reserved" 1 "Speed Mode" 0 "Torque Mode/Default" ;
VAL_ 283 MCU_State 15 "Invalid Value" 14 "Reserved" 13 "Reserved" 12 "Reserved" 11 "Reserved" 10 "Reserved" 9 "Reserved" 8 "Reserved" 7 "ReadyToShutdown" 6 "Reserved" 5 "Failure" 4 "Operational" 3 "Reserved" 2 "Reserved" 1 "Standby" 0 "Initialization" ;
VAL_ 283 MCU_ACTV_Discharge_STS 4 "Signal Invalid" 3 "ACT_DIS_complete_without_error" 2 "ACT_DIS_Unsuccessful_with_error" 1 "ACT_DIS_Initiated" 0 "Default" ;
VAL_ 283 MCU_ACTV_Discharge_FAIL 1 "Fail" 0 "No Fail" ;
VAL_ 982 MCU_HighPowerCurrent 2047 "Signal Invallid" 0 "Default Value" ;
VAL_ 982 MCU_HighPowerVoltage 2047 "Default Value" ;
VAL_ 982 MCU_TractionTorqueAvail_quasi 32767 "Default Value" ;
VAL_ 982 MCU_RegenTorqueAvail_quasi 32767 "Default Value" ;
VAL_ 1478 LDC_COMFLT_SGN_CONTFAIL 3 "Reserved" 2 "SCF DTC Healed State" 1 "SCF DTC Current State" 0 "Deault/No DTC" ;
VAL_ 1478 LDC_UV_STS 1 "Active" 0 "Inactive/Default" ;
VAL_ 1478 LDC_OV_STS 1 "Active" 0 "Inactive/Default" ;
VAL_ 1478 LDC_STS_IGN_NM 1 "IGN on" 0 "IGN Off/Default" ;
VAL_ 1478 LDC_AUX_BATT_VOLT 0 "Default" ;
VAL_ 1478 LDC_COMFLT_MSG_CONTFAIL 3 "Reserved" 2 "MCF DTC Healed State" 1 "MCF DTC Current State" 0 "Default/No DTC" ;
VAL_ 1478 LDC_COMFLT_NODEABS_STS 3 "Reserved" 2 "NA DTC Healed State" 1 "NA DTC Current State" 0 "Default/no DTC" ;
VAL_ 1478 LDC_VARIANT_CODE_ERR_STS 3 "Reserved" 2 "VC DTC in Healed State" 1 "VC DTC in current state" 0 "Default" ;
VAL_ 1478 LDC_NM_ACTIVE_STS 7 "NM Active" 6 "Disabled due to IGN off" 5 "Disabled due to bus off" 4 "Disabled due to over voltage" 3 "Disabled due to under voltage" 2 "Disabled due to Cranking T50/ESS" 1 "Disabled due to VC" 0 "Diabled due to IGN On/Default" ;
VAL_ 1478 LDC_FEATURE_CODE_ERR_STS 3 "Reserved" 2 "FC DTC in Healed State" 1 "FC DTC in current state" 0 "Default" ;
VAL_ 1478 LDC_COMFLT_MSGTOUT_STS 3 "Reserved" 2 "MTO DTC in Healed State" 1 "MTO DTC in current state" 0 "Default/No DTC" ;
VAL_ 1477 ETL_COMFLT_SGN_CONTFAIL 3 "Reserved" 2 "SCF DTC Healed State" 1 "SCF DTC Current State" 0 "Deault/No DTC" ;
VAL_ 1477 ETL_OV_STS 1 "Active" 0 "Inactive/Default" ;
VAL_ 1477 ETL_UV_STS 1 "Active" 0 "Inactive/Default" ;
VAL_ 1477 ETL_STS_IGN 1 "IGN on" 0 "IGN Off/Default" ;
VAL_ 1477 ETL_AUX_BATT_VOLT 0 "Default" ;
VAL_ 1477 ETL_COMFLT_MSG_CONTFAIL 3 "Reserved" 2 "MCF DTC Healed State" 1 "MCF DTC Current State" 0 "Default/No DTC" ;
VAL_ 1477 ETL_COMFLT_NODEABS_STS 3 "Reserved" 2 "NA DTC Healed State" 1 "NA DTC Current State" 0 "Default/no DTC" ;
VAL_ 1477 ETL_COMFLT_MSGTOUT_STS 3 "Reserved" 2 "MTO DTC in Healed State" 1 "MTO DTC in current state" 0 "Default/No DTC" ;
VAL_ 578 ETL_Shifting_In_Progress 1 "Shifting" 0 "Not Shifting" ;
VAL_ 578 ETL_Service_WRN_IND 1 "ON" 0 "OFF" ;
VAL_ 578 ETL_Pmotor_Position_Failure 1 "Fault" 0 "No Fault" ;
VAL_ 578 ETL_PmotorPositionStatus 3 "Invalid" 2 "In Between" 1 "N" 0 "P" ;
VAL_ 578 ETL_PmotorErrorLevel 15 "Invalid" 14 "Reserved" 13 "Reserved" 12 "Reserved" 11 "Reserved" 10 "Reserved" 9 "Reserved" 8 "Reserved" 7 "Reserved" 6 "Reserved" 5 "Error Level 5" 4 "Error Level 4" 3 "Error Level 3" 2 "Error Level 2" 1 "Error Level 1" 0 "Error Level 0" ;
VAL_ 578 ETL_OperationMode 4 "Error" 3 "Ready" 2 "Reserved" 1 "Standby (Low Power Mode)" 0 "Sleep/Default" ;
VAL_ 1475 BMS_STS_IGN_NM 1 "IGN on" 0 "IGN Off/Default" ;
VAL_ 1475 BMS_COMFLT_SGN_CONTFAIL 3 "Reserved" 2 "SCF DTC Healed State" 1 "SCF DTC Current State" 0 "Deault/No DTC" ;
VAL_ 1475 BMS_UV_STS 1 "Active" 0 "Inactive/Default" ;
VAL_ 1475 BMS_OV_STS 1 "Active" 0 "Inactive/Default" ;
VAL_ 1475 BMS_AUX_BATT_VOLT 0 "Default" ;
VAL_ 1475 BMS_COMFLT_MSG_CONTFAIL 3 "Reserved" 2 "MCF DTC Healed State" 1 "MCF DTC Current State" 0 "Default/No DTC" ;
VAL_ 1475 BMS_COMFLT_NODEABS_STS 3 "Reserved" 2 "NA DTC Healed State" 1 "NA DTC Current State" 0 "Default/no DTC" ;
VAL_ 1475 BMS_VARIANT_CODE_ERR_STS 3 "Reserved" 2 "VC DTC in Healed State" 1 "VC DTC in current state" 0 "Default" ;
VAL_ 1475 BMS_NM_ACTIVE_STS 7 "NM Active" 6 "Disabled due to IGN off" 5 "Disabled due to bus off" 4 "Disabled due to over voltage" 3 "Disabled due to under voltage" 2 "Disabled due to Cranking T50/ESS" 1 "Disabled due to VC" 0 "Diabled due to IGN On/Default" ;
VAL_ 1475 BMS_FEATURE_CODE_ERR_STS 3 "Reserved" 2 "FC DTC in Healed State" 1 "FC DTC in current state" 0 "Default" ;
VAL_ 1475 BMS_COMFLT_MSGTOUT_STS 3 "Reserved" 2 "MTO DTC in Healed State" 1 "MTO DTC in current state" 0 "Default/No DTC" ;
VAL_ 1002 BMS_Regen_AH 65535 "SIGNAL INVALID" 0 "NO FAULT/DEFAULT VALUE" ;
VAL_ 1002 BMS_KiloWattHour 1 "SIGNAL INVALID" 0 "NO FAULT/DEFAULT" ;
VAL_ 1002 BMS_AmpereHour 65535 "SIGNAL INVALID" 0 "NO FAULT/ DEFAULT VALUE" ;
VAL_ 980 BMS_Batt_Overcurrent_Sta 3 "Signal Invalid" 2 "Reserved" 1 "Overcurrent" 0 "No Overcurrent/Default" ;
VAL_ 980 BMS_DischargePowerAvailable_2 0 "Default Value" 4095 "Signal Invalid" ;
VAL_ 980 BMS_DischargePowerAvailable_10 0 "Default value" 4095 "Signal Invalid" ;
VAL_ 980 BMS_BatteryPackSOE 0 "Default Value" 1023 "Signal Invalid" ;
VAL_ 978 BMS_BHeaterFlt 32 "Reserved" 31 "Reserved" 30 "Reserved" 29 "Reserved" 28 "Reserved" 27 "Reserved" 26 "Reserved" 25 "Reserved" 24 "Reserved" 23 "Reserved" 22 "Reserved" 21 "Reserved" 20 "Reserved" 19 "CLT_SoftwareVersion_Num" 18 "CLT_Fail_IGBTDriverIC" 17 "CLT_Fail_IGBTShort" 16 "CLT_Fail_IGBTOpen" 15 "CLT_Fail_PCBTempSen" 14 "CLT_Fail_OutletTempSen" 13 "CLT_FailHVCurSen" 12 "CLT_FailHVSen" 11 "CLT_Fail_LVSen" 10 "CLT_Fault_LotCtrlMsg" 9 "CLT_Fault_PCBTempOver" 8 "CLT_Fault_OutletTempOver" 7 "CLT_Fault_HVOverCurr" 6 "CLT_Fault_HVOver" 5 "CLT_Fault_HVUnder" 4 "CLT_Fault_LVOver" 3 "CLT_Fault_LVUnder" 2 "CLT_LIN_Com_Err_Flag" 1 "CLT_Fault_Flag" 0 "No Fault/Default" ;
VAL_ 978 BMS_BHeaterOpCoolantTemp 680 "Default Value" 4095 "Signal Invalid" ;
VAL_ 978 BMS_CoolingHeatingSta 7 "Signal Invalid" 6 "Reserved" 5 "Reserved" 4 "Rinsing" 3 "Error" 2 "ON Heating" 1 "ON Cooling" 0 "OFF/Default" ;
VAL_ 978 BMS_ChillerSoleniodSta 3 "Signal Invalid" 2 "Reserved" 1 "ON" 0 "OFF/Default" ;
VAL_ 978 BMS_BatteryPreconditioningSta 3 "Signal Invalid" 2 "HighTempPreCondition ON" 1 "LowTempPreCondition ON" 0 "PreCondition OFF/Default" ;
VAL_ 978 BMS_BatteryOutletCoolantTemp 680 "Default Value" 4095 "Signal Invalid" ;
VAL_ 978 BMS_BatteryInletCoolantTempReq 680 "Default Value" 4095 "Signal Invalid" ;
VAL_ 978 BMS_BatteryInletCoolantTemp 680 "Default value" 4095 "Signal Invalid" ;
VAL_ 626 BMS_BatteryTBatt 680 "Default Value" 4095 "Signal Invalid" ;
VAL_ 626 BMS_BatteryPackVoltage 16383 "Signal Invalid" 0 "Default Value" ;
VAL_ 626 BMS_DisconnectByBMS 1 "Disconnect by BMS overriding VCU" 0 "Default/No Disconect by BMS" ;
VAL_ 626 BMS_BatteryHVILSta 3 "Error State" 2 "Close" 1 "Open" 0 "Default" ;
VAL_ 626 BMS_ModuleActiveDischarge 3 "Signal Invalid" 2 "Active Discharge" 1 "Discharge Not Active" 0 "Init/Default" ;
VAL_ 626 BMS_BContactorOffRequest 1 "Request ON" 0 "Request OFF/Default val" ;
VAL_ 626 BMS_HVILSta 1 "Open" 0 "Close" ;
VAL_ 626 BMS_PilotlineSta 3 "Signal Invalid" 2 "Reserved" 1 "DisConnected" 0 "Connected/Default" ;
VAL_ 626 BMS_IsolationFlt 3 "Signal Invalid" 2 "ON (Red)" 1 "Warning (Yellow)" 0 "OFF (Green)/Default" ;
VAL_ 626 BMS_CrashPyroFuseResponse 3 "Crash+Pyro/fuse Open" 2 "Crash+Pyro/fuse not open" 1 "No Crash+Pyro/fuse Open" 0 "No Crash+Pyro/fuse not Open" ;
VAL_ 337 BMS_BMainMinusContactorState 3 "Signal Invalid" 2 "CONTACTOR FAIL" 1 "Contactor ON(Closed)" 0 "Contactor OFF(Open)/Default" ;
VAL_ 337 BMS_PreChargeContactorSta 3 "Signal Invalid" 2 "Contactor Fail" 1 "Contactor ON (Closed)" 0 "Contactor OFF(Open) / Default" ;
VAL_ 337 BMS_BMainPlusContactorState 3 "Signal Invalid" 2 "CONTACTOR FAILED" 1 "Contactor ON(Closed)" 0 "Contactor OFF(Open)/Default" ;
VAL_ 337 BMS_Current2sensorReading 6000 "Default value" 16383 "Signal Invalid" ;
VAL_ 337 BMS_Current1sensorReading 6000 "Default value" 16383 "Signal Invalid" ;
VAL_ 1720 NM_VIN_CHECK_STS 1 "Check done" 0 "Check not done/Default" ;
VAL_ 1720 NM_MCF_DTC_STS 3 "Reserved" 2 "MCF DTC Healed State" 1 "MCF DTC Current State" 0 "Default/No DTC" ;
VAL_ 1720 NM_VIN_DTC_STS 3 "Reserved" 2 "VIN DTC Healed State" 1 "VIN DTC Current State" 0 "No DTC / Default" ;
VAL_ 1720 NM_VC_DTC_STS 3 "Reserved" 2 "VC DTC in Healed State" 1 "VC DTC in Current State" 0 "Default" ;
VAL_ 1720 NM_VBATT 0 "Default" ;
VAL_ 1720 NM_UV_STS 1 "Active" 0 "Inactive / Default" ;
VAL_ 1720 NM_STS_IGN 1 "IGN ON" 0 "IGN OFF / Default" ;
VAL_ 1720 NM_SCF_DTC_STS 3 "Reserved" 2 "SCF DTC Healed State" 1 "SCF DTC Current State" 0 "Default /No DTC" ;
VAL_ 1720 NM_OV_STS 1 "Active" 0 "Inactive / Default" ;
VAL_ 1720 NM_NA_DTC_STS 3 "Reserved" 2 "NA DTC Healed State" 1 "NA DTC Current State" 0 "Default / no DTC " ;
VAL_ 1720 NM_MTO_DTC_STS 3 "Reserved" 2 "MTO DTC in Healed State" 1 "MTO DTC in Current State" 0 "Default / No DTC" ;
VAL_ 1720 NM_FC_DTC_STS 3 "Reserved" 2 "FC DTC in Healed State" 1 "FC DTC in Current State" 0 "Default" ;
VAL_ 1720 NM_ACTIVE_STS 7 "NM ACTIVE" 6 "NM OFF at Ignition OFF" 5 "NM OFF due to Busoff" 4 "NM OFF due to OV" 3 "NM OFF due to UV" 2 "NM OFF due to Cranking T50/ESS" 1 "NM OFF due to VC" 0 "NM OFF at Ignition ON / Default" ;
VAL_ 1655 CLOCK_AM_PM 1 "AM" 0 "PM" ;
VAL_ 1655 CLOCK_FORMAT_TGU 1 "24 Hour mode" 0 "12 Hour mode / Default" ;
VAL_ 339 TGU_CHARGINGENDTIME_FORMAT 1 "PM" 0 "AM" ;
VAL_ 339 TGU_CHARGINGSTARTTIME_FORMAT 1 "PM" 0 "AM" ;
VAL_ 339 TGU_CHRG_STRT_TIME_HOURS 0 "Default" ;
VAL_ 339 TGU_ENERGYCONS 0 "Default" ;
VAL_ 339 TGU_EV_CHRG_PARAM_INDEX 1 "Index 1" 0 "Index 0" ;
VAL_ 339 TGU_CHARGINGSTARTTIME_DATE 0 "Default" ;
VAL_ 339 TGU_CHRG_START_TIME_MIN 0 "Default" ;
VAL_ 339 TGU_CHARGINGSTARTTIME_MONTH 0 "Default" ;
VAL_ 339 TGU_CHARGINGSTARTTIME_YEAR 0 "Default" ;
VAL_ 339 TGU_CHARGINGENDTIME_MIN 0 "Default" ;
VAL_ 339 TGU_CHRGING_DURATION_MIN 0 "Default" ;
VAL_ 339 TGU_CHARGINGENDTIME_YEAR 0 "Default" ;
VAL_ 339 TGU_CHRGING_DURATION_HOURS 0 "Default" ;
VAL_ 338 TGU_TRIPSTARTTIME_FORMAT 1 "PM" 0 "AM" ;
VAL_ 338 TGU_TRIPENDTIME_FORMAT 1 "PM" 0 "AM" ;
VAL_ 338 TGU_TRIPSTARTTIME_YEAR 0 "Default" ;
VAL_ 338 TGU_TRIPSTARTTIME_MIN 0 "Default" ;
VAL_ 338 TGU_TRIP_START_TIME_HOURS 0 "Default" ;
VAL_ 338 TGU_TRIPENDTIME_YEAR 0 "Default" ;
VAL_ 338 TGU_TRIPENDTIME_MONTH 0 "Default" ;
VAL_ 338 TGU_TRIPENDTIME_MIN 0 "Default" ;
VAL_ 338 TGU_TRIPENDTIME_DATE 0 "Default" ;
VAL_ 338 TGU_TRIPEFFICIENCY 3 "High" 2 "Medium" 1 "Low" 0 "Default" ;
VAL_ 338 TGU_TRIPAVGVEHICLESPEED 0 "Default" ;
VAL_ 338 TGU_TRIP_TOP_SPEED 0 "Default" ;
VAL_ 338 TGU_TRIP_START_TIME_MONTH 0 "Default" ;
VAL_ 338 TGU_TRIP_START_TIME_DATE 0 "Default" ;
VAL_ 338 TGU_TRIP_END_TIME_HOURS 0 "Default" ;
VAL_ 338 TGU_TRIP_DURATION_MIN 0 "Default" ;
VAL_ 338 TGU_TRIP_DURATION_HOURS 0 "Default" ;
VAL_ 338 TGU_TRIP_DISTANCE 0 "Default" ;
VAL_ 338 TGU_TREES_SAVED 0 "Default" ;
VAL_ 338 TGU_CO2 0 "Default" ;
VAL_ 338 TGU_EV_KILOMETERS 0 "Default" ;
VAL_ 338 TGU_FRESHDATAFLAG 1 "FreshData" 0 "Default" ;
VAL_ 338 TGU_EV_PARAM_INDEX 4 "Index 4" 3 "Index 3" 2 "Index 2" 1 "Index 1" 0 "Index 0" ;
VAL_ 1761 NM_VIN_CHECK_STS_TGU 1 "Check done" 0 "Check not done/Default" ;
VAL_ 1761 NM_VIN_DTC_STS_TGU 3 "Reserved" 2 "VIN DTC Healed State" 1 "VIN DTC Current State" 0 "No DTC / Default" ;
VAL_ 1761 NM_VC_DTC_STS_TGU 3 "Reserved" 2 "VC DTC in Healed State" 1 "VC DTC in Current State" 0 "Default" ;
VAL_ 1761 NM_MCF_DTC_STS_TGU 3 "Reserved" 2 "MCF DTC Healed State" 1 "MCF DTC Current State" 0 "Default/No DTC" ;
VAL_ 1761 NM_VBATT_TGU 0 "Default" ;
VAL_ 1761 NM_UV_STS_TGU 1 "Active" 0 "Inactive / Default" ;
VAL_ 1761 NM_STS_IGN_TGU 1 "IGN ON" 0 "IGN OFF / Default" ;
VAL_ 1761 NM_SCF_DTC_STS_TGU 3 "Reserved" 2 "SCF DTC Healed State" 1 "SCF DTC Current State" 0 "Default /No DTC" ;
VAL_ 1761 NM_OV_STS_TGU 1 "Active" 0 "Inactive / Default" ;
VAL_ 1761 NM_NA_DTC_STS_TGU 3 "Reserved" 2 "NA DTC Healed State" 1 "NA DTC Current State" 0 "Default / no DTC " ;
VAL_ 1761 NM_MTO_DTC_STS_TGU 3 "Reserved" 2 "MTO DTC in Healed State" 1 "MTO DTC in Current State" 0 "Default / No DTC" ;
VAL_ 1761 NM_FC_DTC_STS_TGU 3 "Reserved" 2 "FC DTC in Healed State" 1 "FC DTC in Current State" 0 "Default" ;
VAL_ 1761 NM_ACTIVE_STS_TGU 7 "NM ACTIVE" 6 "NM OFF at Ignition OFF" 5 "NM OFF due to Busoff" 4 "NM OFF due to OV" 3 "NM OFF due to UV" 2 "NM OFF due to Cranking T50/ESS" 1 "NM OFF due to VC" 0 "NM OFF at Ignition ON / Default" ;
VAL_ 999 BMS_BatteryMaxCellVoltage 16383 "Invalid Value" 3650 "Default Value" ;
VAL_ 999 BMS_BatteryMinCellVoltage 16383 "Invalid Value" 3650 "Default Value" ;
VAL_ 999 BMS_BatteryDisconnectSta 15 "Reserved" 14 "Reserved" 13 "Reserved" 12 "Reserved" 11 "Reserved" 10 "Reserved" 9 "Reserved" 8 "Fail - Over Battery pack current" 7 "Fail - HV diag failed" 6 "Fail - Precharge diag failed" 5 "Pass - Emergency out" 4 "Fail - Both weld" 3 "Pass - -ve weld only" 2 "Pass - +ve weld only" 1 "Pass - No Weld" 0 "Init/Default" ;
VAL_ 999 BMS_BatteryConnectSta 15 "Reserved" 14 "Reserved" 13 "Reserved" 12 "Pass - Positive & Negative OK" 11 "Fail  - Precharge closure fail" 10 "Fail - Negative contactor weld" 9 "Fail - Positive contactor weld" 8 "Fail - Both contactor weld" 7 "Fail - Fuse Open" 6 "Fail - System Related fault" 5 "Fail - HVIl " 4 "Fail - pilot line" 3 "Fail - Battery Temp Out of Range" 2 "Fail - HV coil diag fail  " 1 "Fail - Precharge coil diag fail" 0 "Init/Default" ;
VAL_ 999 BMS_BatteryAvgCellVoltage 16383 "Signal Invalid" 3650 "Default Value" ;
VAL_ 1000 BMS_BatteryPackSOH 0 "Default Value" 1023 "Signal Invalid" ;
VAL_ 1000 BMS_BatteryPackRSOC 0 "Default Value" 1023 "Signal Invalid" ;
VAL_ 1000 BMS_BatteryPackASOC 0 "Default Value" 1023 "Signal Invalid" ;
VAL_ 1652 REMOTE_HV_CONNECT_REQ_TGU 3 "Reserved" 2 "HV Connected" 1 "HV Disconnected" 0 "Default" ;
VAL_ 1652 REQ_AC_TGU 1 "ON" 0 "OFF/Default" ;
VAL_ 1652 REQ_TEMP_TGU 7 "Reserved" 6 "Reserved" 5 "Reserved" 4 "Max Heating Request" 3 "Low Heating Request" 2 "Max Cooling Request" 1 "Low Cooling Request" 0 "No Request/Default" ;
VAL_ 1652 VEH_SEARCH_REQ 3 "Search OFF" 2 "Search with Siren OFF" 1 "Search with Siren ON" 0 "No Request" ;
VAL_ 1652 CHARGING_ON_OFF_REQ 0 "DEFAULT" 1 "CHARGING ENABLE" 2 "CHARGING DISABLE" 3 "INVALID" ;
VAL_ 1652 TGU_REVIVE_REQ 0 "NO REQUEST/DEFAULT" 1 "REVIVE REQUEST" ;
VAL_ 1652 REMOTE_DOOR_LOCK_UNLOCK 3 "RESERVED" 2 "DOOR UNLOCK REQUEST" 1 "DOOR LOCK REQUEST" 0 "DEFAULT MODE" ;
VAL_ 374 ENGINE_STOP_AMT 1 "Request to stop Engine" 0 "No Request / Default" ;
VAL_ 374 TGS_MODE_AMT 3 "Signal Invalid" 2 "Warm Up" 1 "Manual" 0 "Normal / Default Value" ;
VAL_ 374 TCU_SHIFT_MODE 3 "Signal Invalid" 2 "Reserved" 1 "Automatic Mode" 0 "MAnual Mode / Default" ;
VAL_ 374 GEAR_ACTUAL_AMT 15 "Signal Invalid" 14 "Drive Lock Out (Neutral)" 13 "Drive Limp Home (4th)" 12 "Reverse Lock Out (Neutral)" 11 "Reverse Limp Home" 10 "Reverse (Electronic Engagement)" 9 "Manual 1st (+ve/-ve Torque)" 8 "Reserved" 7 "Reserved" 6 "6th" 5 "5th" 4 "4th" 3 "3rd" 2 "2nd" 1 "1st (Positive torque only)" 0 "Neutral / Default Value" ;
VAL_ 264 ALTERNATOR_CUTOFF_REQ 1 "Active" 0 "Not Active / Default" ;
VAL_ 264 ODO_ERROR_FLAG_EMS 1 "Error" 0 "No Error/Default" ;
VAL_ 264 STS_ESS_INDC 7 "Signal Invalid" 6 "Reserved" 5 "Reserved" 4 "LAmp Blink before Engine Start" 3 "Lamp blink due to Voltage Mon" 2 "Lamp blink before Engine stop" 1 "Lamp ON after Engine Stop" 0 "Lamp OFF/Default" ;
VAL_ 264 ENG_TRQ_AFTR_RED 2047 "Signal Invalid" 0 "Default" ;
VAL_ 264 INTAKE_AIR_TEMP 255 "Signal Invalid" 0 "Default" ;
VAL_ 264 STS_DPF_REGENERATION 1 "Regeneration active" 0 "Regeneration inactive/default" ;
VAL_ 264 STS_ENG_LIMP_HOME 1 "Active" 0 "Inactive/Default" ;
VAL_ 264 DRIVER_DEMAND_TRQ 2047 "Signal Invalid" 0 "Default" ;
VAL_ 264 BARO_PRS 255 "Signal Invalid" 104 "Default" ;
VAL_ 264 CLUTCH_STS 7 "Signal Invalid" 6 "Reserved" 5 "Reserved" 4 "Reserved" 3 "Reserved" 2 "90% Pressed" 1 "10% Pressed" 0 "Not Pressed / Default" ;
VAL_ 579 VCU_EVCAN_WAKEUPREASON 5 "Reserved" 4 "LV Battery Charge" 3 "Wakeup for Fast Charging" 2 "RTC Based Wake Up Trigger" 1 "Wakeup for Normal Charging" 0 "Key On /Ignition " ;
VAL_ 336 BMS_TotalCycle_Time 65535 "SIGNAL INVALID" 0 "DEFAULT VALUE" ;
VAL_ 336 BMS_DischargeCycle_Time 65535 "SIGNAL INVALID" 0 "DEFAULT VALUE" ;
VAL_ 336 BMS_ChargeCycle_Time 65535 "Signal Invalid" 0 "Default Value" ;
VAL_ 336 BMS_CycleNumber 65535 "SIGNAL INVALID" 0 "DEFAULT VALUE" ;
VAL_ 285 BMS_BattPack_PwrLimitErr_Common 1 "Fault" 0 "Default/No Fault" ;
VAL_ 285 BMS_Bat_I_OvrExtCurr_Flt_Dischrg 1 "Fault" 0 "Default/No Fault" ;
VAL_ 285 BMS_Bat_I_OverCurr_Flt_Discharge 1 "Fault" 0 "Default/No Fault" ;
VAL_ 285 BMS_BattOverVolt_Cutoff_Charge 1 "Fault" 0 "Default/No Fault" ;
VAL_ 285 BMS_ClntInlet_High_Temp_Charge 1 "Fault" 0 "Default/No Fault" ;
VAL_ 285 BMS_ClntInlet_Low_Temp_Charge 1 "Fault" 0 "Default/No Fault" ;
VAL_ 285 BMS_ClntOutlet_Low_Temp_Charge 1 "Fault" 0 "Default/No Fault" ;
VAL_ 285 BMS_Clntoutlet_High_Temp_Charge 1 "Fault" 0 "Default/No Fault" ;
VAL_ 285 BMS_BattOver_Temp_Cutoff_common 1 "Fault" 0 "Default/No Fault" ;
VAL_ 285 BMS_BattUnder_Temp_Cutoff_common 1 "Fault" 0 "Default/No Fault" ;
VAL_ 285 BMS_ClntSen_Thres_Fault_Charge 1 "Fault" 0 "Default/No Fault" ;
VAL_ 285 BMS_ReverseCurrDetect_Charge 1 "Fault" 0 "Default/No Fault" ;
VAL_ 285 BMS_PLP_Stop_Charge 1 "Fault" 0 "Default/No Fault" ;
VAL_ 285 BMS_CellUnderVolt_Cutoff_Common 1 "Fault" 0 "Default/No Fault" ;
VAL_ 285 BMS_BattUnderVolt_Cutoff_Common 1 "Fault" 0 "Default/No Fault" ;
VAL_ 285 BMS_ModuleOverTemp_Cutoff_Common 1 "Fault" 0 "Default/No Fault" ;
VAL_ 285 BMS_MdleUnderTemp_Cutoff_Common 1 "Fault" 0 "Default/No Fault" ;
VAL_ 285 BMS_ShortCircuitCurr_Flt_Common 1 "Fault" 0 "Default/No Fault" ;
VAL_ 285 BMS_Sensor_Failure_Common 1 "Fault" 0 "Default/No Fault" ;
VAL_ 285 BMS_Ibatt_392_25sec_Common 1 "Fault" 0 "Default/No Fault" ;
VAL_ 285 BMS_PilotLine_Detect_Common 1 "Fault" 0 "Default/No Fault" ;
VAL_ 285 BMS_Revive_Common 1 "Fault" 0 "Default/No Fault" ;
VAL_ 285 BMS_HeaterSys_Flt_Common 1 "Fault" 0 "Default/No Fault" ;
VAL_ 285 BMS_Clnt_TempSens_Flt_Common 1 "Fault" 0 "Default/No Fault" ;
VAL_ 285 BMS_Heater_Flt_Common 1 "Fault" 0 "Default/No Fault" ;
VAL_ 285 BMS_IsoFLt_Red_Discharge 1 "Fault" 0 "Default/No Fault" ;
VAL_ 285 BMS_LowSOC_Cutoff_Discharge 1 "Fault" 0 "Default/No Fault" ;
VAL_ 285 BMS_Bat_I_ExtCurr_Flt_Dischrg 1 "Fault" 0 "Default/No Fault" ;
VAL_ 285 BMS_MTM_ActvLimit_Common 1 "Fault" 0 "Default/No Fault" ;
VAL_ 285 BMS_ClntSys_Flt_Common 1 "Fault" 0 "Default/No Fault" ;
VAL_ 285 BMS_Pump_DryRun_Err_Common 1 "Fault" 0 "Default/No Fault" ;
VAL_ 285 BMS_CrashDtct_P_F_Open_Common 1 "Fault" 0 "Default/No Fault" ;
VAL_ 285 BMS_HVIL_Err_Dischrg 1 "Fault" 0 "Default/No Fault" ;
VAL_ 285 BMS_No_Cntctr_Close 1 "Fault" 0 "Default/No Fault" ;
VAL_ 285 BMS_CntctrOpen_Rqst_VCU_Dischrg 1 "Fault" 0 "Default/No Fault" ;
VAL_ 285 BMS_CntctrOpen_Rqst_VCU_Chrg 1 "Fault" 0 "Default/No Fault" ;
VAL_ 285 BMS_InitCntctrOpen_Dischrg 1 "Fault" 0 "Default/No Fault" ;
VAL_ 285 BMS_InitCntctrOpen_Charge 1 "Fault" 0 "Default/No Fault" ;
VAL_ 285 BMS_FSBIM_bAcvDrtdMode 1 "Fault" 0 "Default/No Fault" ;
VAL_ 285 BMS_FSPLP_bAcvDrtdMode 1 "Fault" 0 "Default/No Fault" ;
VAL_ 285 BMS_ILC_AcvDrtdCdn 1 "Fault" 0 "Default/No Fault" ;
VAL_ 285 BMS_IDMStsIsInErr_Yellow 1 "Fault" 0 "Default/No Fault" ;
VAL_ 285 BMS_FSPLP_bAcvPackOverUDrtd 1 "Fault" 0 "Default/No Fault" ;
VAL_ 285 BMS_BIM_bAcvHighRateDchaDrdt2 1 "Fault" 0 "Default/No Fault" ;
VAL_ 285 BMS_FSPLP_bAcvPackUnderUDrtd 1 "Fault" 0 "Default/No Fault" ;
VAL_ 285 BMS_BIMbAcvReqDrtdMode 1 "Fault" 0 "Default/No Fault" ;
VAL_ 285 BMS_BTFD_bAcvReqDrtdMode 1 "Fault" 0 "Default/No Fault" ;
VAL_ 285 BMS_CUM_bAcvOwDrtd 1 "Fault" 0 "Default/No Fault" ;
VAL_ 285 BMS_CellOverVolt_Cutoff_Charge 1 "Fault" 0 "Default/No Fault" ;
VAL_ 285 BMS_Reason_HV_Disconnected 5 "CRASH info VIA CAN" 4 "Battery Thermal Runaway" 3 "CRASH_DETECT_P/F_OPEN" 2 "Battery_I_Extreme_Current_Fault" 1 "Battery_I_Ovr_Extreme_Crnt_Fault" 0 "Reserved" ;
VAL_ 285 BMS_Reason_HV_Disconnect_Request 28 "PCB TEMPERATURE_BEYOND_LIMIT" 27 "BMSReversecurrent detetction DTC" 26 "Current_sensor_1_&&2_fail" 25 "BMS short circuit current fault" 24 "BMS_Charge time out" 23 "BMS_Precharge Fail" 22 "Isolation_Fault_Red" 21 "HVIL_OUT_THRESH_Cheater" 20 "HVIL_Cheater_STG" 19 "HVIL_Cheater_STB" 18 "HVIL_OUT_THRESH_Bheater" 17 "HVIL_Bheater_STG" 16 "HVIL_Bheater_STB" 15 "HVIL_OUT_THRESH_BBOX" 14 "HVIL_BBOX_STG" 13 "HVIL_BBOX_STB" 12 "PILOT_PWM,_ERROR" 11 "PUMP_DRY_RUN_ERROR" 10 "BMS LOW SOC CUTOFF" 9 "Module under temperature cutoff" 8 "Module Overtemperature cutoff" 7 "Battery_I_Over_Current_Fault" 6 "Battery Under Temperature cutoff" 5 "Battery Over Temperature cutoff" 4 "Battery Under voltage Cutoff" 3 "Battery Over voltage Cutoff" 2 "Cell_Under_Voltage _Cutoff" 1 " Cell_Over_Voltage _Cutoff" 0 "Reserved" ;
VAL_ 285 BMS_Reason_Derating 31 "CCLM DERATE  " 30 "TPS FAULT" 29 "LIN timeout Failure" 28 "BMScell vlt snsr fail cutoff BMU" 27 "Battery Disconnect Fail" 26 "BATTER PACK POWER LIMIT ERROR" 25 "Isolation_Fault_yellow" 24 " Isolation_Time_Out" 23 "Coolant sensor threshold fault" 22 "PUMP_OVERLOAD_PROTECTION" 21 "PUMP_UNDER_AND_OVER_VOLTAGE" 20 "PUMP_OVER_TEMP_SHUTDOWN" 19 "PUMP_OVER_TEMPERATURE_DERATED" 18 "PUMP_OVER_CURRENT_DERATED" 17 "COOLANT_OUTLET_LOW_TEMP" 16 "COOLANT_OUTLET_HIGH_TEMP" 15 "COOLANT_INLET_LOW_TEMP" 14 "COOLANT_INLET_HIGH_TEMP" 13 "BMS_CELL_WAER_DETECTION_FAULT" 12 "BMU OPEN WIRE FAULT" 11 "Module under temperature derate" 10 "Module Over temperature derate" 9 "MOD_TEMP_DIFF" 8 "MULTI_MOD_2_TEMP_FAULT" 7 "1_MOD_2_TEMP_FAULT" 6 "Battery Under Temp Derated" 5 "Battery Over Temperature derated" 4 "Battery Under voltage Derated" 3 "Battery Over voltage Derated" 2 "Cell Under Voltage Derate" 1 "Cell Over Voltage Derate" 0 "Reserved" ;
VAL_ 920 STS_HIGHBEAM_BOOSTER 1 "HIGHBEAM BOOSTER ON" 0 "HIGHBEAM BOOSTER OFF" ;
VAL_ 920 HEADLAMP_AUTO_LEVEL 1 "HL Auto level Enable" 0 "HL Auto level Disbabl/DV" ;
VAL_ 921 STS_HIGHBEAM_BOOSTER_1 1 "HIGHBEAM BOOSTER ON" 0 "HIGHBEAM BOOSTER OFF" ;
VAL_ 771 PASSIVE_VENT_FATC_STS 1 "Passive Ventilation Active" 0 "Passive Vent not active / DV" ;
VAL_ 771 DISP_AMBT_TEMP_FATC 0 "Default Value" 255 "Invalid value" ;
VAL_ 1711 FOD_ALERT 1 "Foreign Object Detected" 0 "No Foreign objct detctd/ Default" ;
VAL_ 1711 TIME_TO_CHARGE 255 "Signal Invalid" 252 "NFC Card Protection Alert" 251 "Low Vehicle Battery Alert" 250 "Mobile Device Placement Error" 249 "Negotiation Failure" 248 "Mobile Device Battery Failure" 247 "Mobile Device Over Voltage" 246 "Mobile Device Over Temperature" 245 "Mobile Device Internal Fault" 244 "Mobile Device Unkown Error" 243 "Over heat Shutdown" 242 "Forgotten Device" 241 "No Device / Default" 1 "Phone Charging" 0 "Full Charge" 2 "WLC OFF" ;
VAL_ 768 STS_IONIZER 1 "ON" 0 "OFF" ;
VAL_ 768 AC_SWT_STS 1 "ON" 0 "OFF / Default" ;
VAL_ 768 AUTO_RECIRC 1 "Enable" 0 "Disable/Default" ;
VAL_ 768 AUTO_DEFROST 1 "Enable" 0 "Disable/Default" ;
VAL_ 768 STS_REAR_AC 1 "ON" 0 "OFF / Default" ;
VAL_ 768 MEM_DISP 4 "Signal Invalid" 3 "'3'" 2 "'2'" 1 "'1'" 0 "Default Value / MEM LED OFF" ;
VAL_ 768 FRONT_LEFT_SET_TEMP 255 "Signal Invalid" 0 "Default Value" ;
VAL_ 768 FRESH_RECIRC 3 "Signal Invalid" 2 "Reserved" 1 "Recirculation" 0 "Fresh / Default" ;
VAL_ 768 FATC_ECON 3 "Signal Invalid" 2 "Not Used" 1 "ECON ON" 0 "ECON OFF/ Default" ;
VAL_ 768 FATC_AUTO 3 "Signal Invalid" 2 "Reserved" 1 "AUTO ON" 0 "AUTO OFF/Default" ;
VAL_ 768 FRONT_RIGHT_SET_TEMP 255 "Signal Invalid" 0 "Default value" ;
VAL_ 768 DISP_OFF 3 "Signal Invalid" 2 "FATC system OFF(Blower OFF)" 1 "ON" 0 "OFF / Default" ;
VAL_ 768 DISP_MODE 15 "Signal Invalid" 14 "Reserved" 13 "Reserved" 12 "Reserved" 11 "Reserved" 10 "Reserved" 9 "Reserved" 8 "Reserved" 7 "Reserved" 6 "Reserved" 5 "Def" 4 "Floor / Def" 3 "Floor" 2 "Vent / Floor" 1 "Vent" 0 "OFF / Default" ;
VAL_ 768 DISP_DUAL 3 "Signal Invalid" 2 "Not Used" 1 "Dual ON" 0 "Dual OFF/Single Zone / Default" ;
VAL_ 768 DISP_AC 3 "Signal Invalid" 2 "Not Used" 1 "AC ON" 0 "AC OFF / Default" ;
VAL_ 768 INCAR_TEMP 255 "Signal Invalid" 0 "Default Value" ;
VAL_ 768 DISP_BLOWER 15 "Signal Invalid" 14 "Reserved" 13 "Reserved" 12 "Reserved" 11 "Reserved" 10 "Reserved" 9 "8-Step" 8 "7-Step" 7 "6-Step" 6 "5-Step" 5 "4-Step" 4 "3-Step" 3 "2-Step" 2 "1-Step" 1 "0-Step" 0 "OFF/Default" ;
VAL_ 1588 GP_CLOSE_RES_AC 1 "OK" 0 "Not OK / Default" ;
VAL_ 1588 SET_TIRE_FILL_ASST_IC 1 "Enable/Default" 0 "Disable" ;
VAL_ 1588 TPMS_AUTOLEARN 1 "Enable/Default" 0 "Disable" ;
VAL_ 1588 GP_CLOSE_RES_RAIN 1 "OK" 0 "Not OK / Default" ;
VAL_ 1588 SET_VACATION_MODE_IC 1 "Enable" 0 "Disable/Default Value" ;
VAL_ 1586 SEAT_HEAT_VENT_LEVEL_SCM 3 "Level 3" 2 "Level 2" 1 "Level 1" 0 " Default" ;
VAL_ 1586 STS_HEATER 1 "Heater On" 0 "Heater Off / DV" ;
VAL_ 1586 SEAT_POSITION_FEEDBACK 7 "Reserved" 6 "Decline Operation" 5 "Recline Operation" 4 "Down Operation" 3 "UP Operation" 2 "Backward Operation" 1 "Forward Operation" 0 " Default Value" ;
VAL_ 1586 SCM_MEMORY_STS 3 "Reserved" 2 "Succeed" 1 "Failed" 0 "Default" ;
VAL_ 1586 SCM_MEMORY_MODE 7 "Reserved" 6 "Reserved" 5 "Memory Clear" 4 "Manual operation running" 3 "Easy Entry/Exit Running" 2 "Memory read/ Recall" 1 "Memory Write" 0 "Default" ;
VAL_ 1586 HEATER_TEMP 0 "Default Value" 255 "Invalid value" ;
VAL_ 1586 POWER_SEAT_MEMORY_STORE 3 "Position 3" 2 "Position 2" 1 "Position 1" 0 "Default Value" ;
VAL_ 1586 POWER_SEAT_MEMORY_RECALL 3 "Position 3" 2 "Position 2" 1 "Position 1" 0 "Default Value" ;
VAL_ 828 RLS_WINDOW_CLOSE_REQ 1 "Window Close Request" 0 "No Request / Default" ;
VAL_ 828 RLS_SOLAR_RIGHT 255 "Signal Invalid" 254 "Default" ;
VAL_ 828 RLS_SOLAR_LEFT 255 "Signal Invalid" 254 "Default" ;
VAL_ 828 RLS_IR_BRIGHTNESS 255 "Signal Invalid" 254 "Default" ;
VAL_ 828 RLS_FW_BRIGHTNESS 1023 "Signal Invalid" 1022 "Default" ;
VAL_ 828 RLS_AMB_BRIGHTNESS 1023 "Signal Invalid" 1022 "Default" ;
VAL_ 806 FPAS_ACTIVE_STS 1 "TRUE" 0 "FLASE / Default" ;
VAL_ 806 FPAS_SWT_STS 1 "ON" 0 "OFF/DEFAULT" ;
VAL_ 806 RPAS_ERROR 0 "Default value" ;
VAL_ 806 RPAS_DISP_DIST 255 "Signal Invalid" 254 "Default value or No Object" 253 "Reserved" 252 "Reserved" 251 "Reserved" ;
VAL_ 806 RPAS_ACTIVE_STS 1 "TRUE" 0 "FLASE / Default" ;
VAL_ 806 BAR_ZONE_RRC 15 "Bar Zone 15 ON" 14 "Bar Zone 14 ON" 13 "Bar Zone 13 ON" 12 "Bar Zone 12 ON" 11 "Bar Zone 11 ON" 10 "Bar Zone 10 ON" 9 "Bar Zone 9 ON" 8 "Bar Zone 8 ON" 7 "Bar Zone 7 ON" 6 "Bar Zone 6 ON" 5 "Bar Zone 5 ON" 4 "Bar Zone 4 ON" 3 "Bar Zone 3 ON" 2 "Bar Zone 2 ON" 1 "Bar Zone 1 ON" 0 "No warning/Default" ;
VAL_ 806 BAR_ZONE_RR 15 "Bar Zone 15 ON" 14 "Bar Zone 14 ON" 13 "Bar Zone 13 ON" 12 "Bar Zone 12 ON" 11 "Bar Zone 11 ON" 10 "Bar Zone 10 ON" 9 "Bar Zone 9 ON" 8 "Bar Zone 8 ON" 7 "Bar Zone 7 ON" 6 "Bar Zone 6 ON" 5 "Bar Zone 5 ON" 4 "Bar Zone 4 ON" 3 "Bar Zone 3 ON" 2 "Bar Zone 2 ON" 1 "Bar Zone 1 ON" 0 "No warning/Default" ;
VAL_ 806 BAR_ZONE_RLC 15 "Bar Zone 15 ON" 14 "Bar Zone 14 ON" 13 "Bar Zone 13 ON" 12 "Bar Zone 12 ON" 11 "Bar Zone 11 ON" 10 "Bar Zone 10 ON" 9 "Bar Zone 9 ON" 8 "Bar Zone 8 ON" 7 "Bar Zone 7 ON" 6 "Bar Zone 6 ON" 5 "Bar Zone 5 ON" 4 "Bar Zone 4 ON" 3 "Bar Zone 3 ON" 2 "Bar Zone 2 ON" 1 "Bar Zone 1 ON" 0 "No warning/Default" ;
VAL_ 806 BAR_ZONE_RL 15 "Bar Zone 15 ON" 14 "Bar Zone 14 ON" 13 "Bar Zone 13 ON" 12 "Bar Zone 12 ON" 11 "Bar Zone 11 ON" 10 "Bar Zone 10 ON" 9 "Bar Zone 9 ON" 8 "Bar Zone 8 ON" 7 "Bar Zone 7 ON" 6 "Bar Zone 6 ON" 5 "Bar Zone 5 ON" 4 "Bar Zone 4 ON" 3 "Bar Zone 3 ON" 2 "Bar Zone 2 ON" 1 "Bar Zone 1 ON" 0 "No warning/Default" ;
VAL_ 806 FPAS_DISP_DIST 255 "Signal Invalid" 254 "Default value or No Object" 253 "Reserved" 252 "Reserved" 251 "Reserved" ;
VAL_ 806 BAR_ZONE_FRC 15 "Bar Zone 15 ON" 14 "Bar Zone 14 ON" 13 "Bar Zone 13 ON" 12 "Bar Zone 12 ON" 11 "Bar Zone 11 ON" 10 "Bar Zone 10 ON" 9 "Bar Zone 9 ON" 8 "Bar Zone 8 ON" 7 "Bar Zone 7 ON" 6 "Bar Zone 6 ON" 5 "Bar Zone 5 ON" 4 "Bar Zone 4 ON" 3 "Bar Zone 3 ON" 2 "Bar Zone 2 ON" 1 "Bar Zone 1 ON" 0 "No warning/Default" ;
VAL_ 806 BAR_ZONE_FLC 15 "Bar Zone 15 ON" 14 "Bar Zone 14 ON" 13 "Bar Zone 13 ON" 12 "Bar Zone 12 ON" 11 "Bar Zone 11 ON" 10 "Bar Zone 10 ON" 9 "Bar Zone 9 ON" 8 "Bar Zone 8 ON" 7 "Bar Zone 7 ON" 6 "Bar Zone 6 ON" 5 "Bar Zone 5 ON" 4 "Bar Zone 4 ON" 3 "Bar Zone 3 ON" 2 "Bar Zone 2 ON" 1 "Bar Zone 1 ON" 0 "No warning/Default" ;
VAL_ 806 FPAS_ERROR 0 "Default value" ;
VAL_ 806 BAR_ZONE_FR 15 "Bar Zone 15 ON" 14 "Bar Zone 14 ON" 13 "Bar Zone 13 ON" 12 "Bar Zone 12 ON" 11 "Bar Zone 11 ON" 10 "Bar Zone 10 ON" 9 "Bar Zone 9 ON" 8 "Bar Zone 8 ON" 7 "Bar Zone 7 ON" 6 "Bar Zone 6 ON" 5 "Bar Zone 5 ON" 4 "Bar Zone 4 ON" 3 "Bar Zone 3 ON" 2 "Bar Zone 2 ON" 1 "Bar Zone 1 ON" 0 "No warning/Default" ;
VAL_ 806 BAR_ZONE_FL 15 "Bar Zone 15 ON" 14 "Bar Zone 14 ON" 13 "Bar Zone 13 ON" 12 "Bar Zone 12 ON" 11 "Bar Zone 11 ON" 10 "Bar Zone 10 ON" 9 "Bar Zone 9 ON" 8 "Bar Zone 8 ON" 7 "Bar Zone 7 ON" 6 "Bar Zone 6 ON" 5 "Bar Zone 5 ON" 4 "Bar Zone 4 ON" 3 "Bar Zone 3 ON" 2 "Bar Zone 2 ON" 1 "Bar Zone 1 ON" 0 "No warning/Default" ;
VAL_ 536 RR_TYRE_TEMP 255 "Signal invalid" 0 "Default Value" ;
VAL_ 536 RR_TYRE_PRESSURE 255 "Signal invalid" 0 "Default Value" ;
VAL_ 536 RL_TYRE_TEMP 255 "Signal invalid" 0 "Default Value" ;
VAL_ 536 RL_TYRE_PRESSURE 255 "Signal invalid" 0 "Default Value" ;
VAL_ 536 FR_TYRE_TEMP 255 "Signal invalid" 0 "Default Value" ;
VAL_ 536 FR_TYRE_PRESSURE 255 "Signal invalid" 0 "Default Value" ;
VAL_ 536 FL_TYRE_TEMP 255 "Signal invalid" 0 "Default Value" ;
VAL_ 536 FL_TYRE_PRESSURE 255 "Signal invalid" 0 "Default Value" ;
VAL_ 1056 CABIN_HVAC_STS_CCM 3 "Reserved" 2 "Cabin Heating ON" 1 "Cabin Cooling ON" 0 "OFF/Default" ;
VAL_ 1056 HEATER_INPUT_DC_VOLT 65535 "Signal Invalid" 0 "Default Value" ;
VAL_ 1056 CABIN_HEATER_POWER_CONSUMPTION 255 "Signal Invalid" 0 "Default Value" ;
VAL_ 1056 AC_OFF_CODE 6 "DISP_AC OFF/INVALID" 17 "Cabin Preheating is ON" 16 "Cabin Precooling became OFF" 15 "
Cabin Heating is ON" 14 "EVAP sig faulty/temp outofrange" 13 "Battery Over voltage" 11 "CRITICAL_HV_LOAD_CUTOFF=1" 10 "Battery Under voltage" 9 "NONCRITICAL_HV_LOAD_CUTOFF=1" 4 "Suction Pressure faulty" 3 "Discharge Pressure - Under prsr
" 2 "Blwr OFF/faulty/lvl outofrange" 1 "Discharge Pressure - Over prsr" 0 "AC preconditions OK." ;
VAL_ 1056 REMOTE_HVAC_STS_CCM 3 "Reserved" 2 "Remote Heating ON" 1 "Remote Cooling ON" 0 "OFF/Default" ;
VAL_ 1001 BMS_ChargeVoltageLimit 16383 "Signal Invalid" 3650 "Default value" ;
VAL_ 1001 BMS_ChargeCurrentLimit 16383 "Signal Invalid" 0 "Default value" ;
VAL_ 1001 BMS_DischargeCurrentlimit 16383 "Signal Invalid" 0 "Default value" ;
VAL_ 1168 REMOTE_HV_CONNECT_FB 3 "Reserved" 2 "HV Connected" 1 "HV Disconnected" 0 "Default" ;
VAL_ 1168 LIMIT_POWER_CCM 6 "Signal Invalid" 5 "Limti 6/Default" 4 "Limit 5" 3 "Limit 4" 2 "Limit 3" 1 "Limit 2" 0 "Limit 1" ;
VAL_ 1168 BATTERY_INLET_COOLANT_TEMP_REQ 2047 "Signal Invalid" 280 "Default Value" ;
VAL_ 1168 BATTERY_INLET_COOLANT_TEMP 2047 "Signal Invalid" 280 "Default value" ;
VAL_ 1168 NONCRITICAL_LV_LOAD_CUTOFF 1 "Cut off/Disable Load" 0 "Default/No Cutoff req/Enable" ;
VAL_ 1168 CRITICAL_LV_LOAD_CUTOFF 1 "Cut off/Disable Load" 0 "Default/No Cutoff req/Enable" ;
VAL_ 1168 NONCRITICAL_HV_LOAD_CUTOFF 1 "Cut off/Disable Load" 0 "Default/No Cutoff req/Enable" ;
VAL_ 1168 EPT_RADIATORFAN_SPEED_REQ 1 "NO SPEED REQUEST/DEFAULT" 2 "LOW SPEED ON" 3 "HIGH SPEED ON" ;
VAL_ 1168 STS_EPT_RADIATORFAN 3 "Signal Invalid" 2 "Reserved" 0 "RADIATOR FAN OFF/DEFAULT" 1 "RADIATOR FAN ON" ;
VAL_ 1168 BATT_COOLING_REQ 1 "Cooling ON request" 0 "No request/Default Value" ;
VAL_ 1168 BATT_COMPRES_SPD_REQ 65535 "Invalid Value" 0 "Default Value" ;
VAL_ 1168 CRITICAL_HV_LOAD_CUTOFF 1 "Cut off/Disable Load" 0 "Default/No Cutoff req/Enable" ;
VAL_ 743 REQUEST_RESPONSE_REVIVE 15 "Reserved" 14 "Reserved" 13 "Reserved" 12 "Reserved" 11 "Unsuccess - No of Attempts" 10 "Reserved" 9 "Reserved" 8 "Reserved" 7 "Unsuccess - Not in Neutral" 6 "Unsuccess - Drive Stop" 5 "Reserved" 4 "Unsuccess - Already Activated" 3 "Unsuccess - SOC" 2 "Unsucess - Immo Auth Fail" 1 "Busy" 0 "REVIVE SUCCESSFUL/DEFAULT VALUE" ;
VAL_ 743 MOTOR_PWR 32768 "Default Value" 65535 "Signal Invalid" ;
VAL_ 743 STS_REGEN 1 "Regeneration is active" 0 "No regeneration /Default" ;
VAL_ 743 RECUP_CTRL_STATE 3 "Reserved" 2 "Inhibit failed/Recup cant stop" 1 "Inhibit success/Recup Disabld" 0 "default value" ;
VAL_ 743 ACT_REGEN_TORQUE_APPLIED 2047 "Signal Invalid" 2046 "Default value" ;
VAL_ 743 ENERGY_EFFICIENCY 255 "Signal Invalid" 0 "Default Value" ;
VAL_ 743 BRAKE_PEDAL_VALUE 255 "Signal Invalid" 0 "Default" ;
VAL_ 743 POWER_REGEN_METER 100 "Default Value" 255 "Signal Invalid" ;
VAL_ 1416 WLC_ENABLE_SETTING_IS 1 "Disable" 0 "Default / Enable" ;
VAL_ 1416 IRVM_AUTO_DIMMING_IS 1 "Disable" 0 "Enable / Default" ;
VAL_ 1416 SUNROOF_WINDOW_OPEN_IS 1 "Enable" 0 "Disable / Default" ;
VAL_ 1416 POWER_SEAT_RECALL_IS 3 "Restore Position 3" 2 "Restore Position 2" 1 "Restore Position 1" 0 "Default Value" ;
VAL_ 1416 SET_AUTO_BRAKE_LAMP_IS 1 "enable" 0 "default value/disable" ;
VAL_ 1416 DYNAMIC_TRAJ_LINES_RPAS 1 "OFF" 0 "ON/Default Value" ;
VAL_ 1416 DYNAMIC_TRAJ_LINE_FPAS_APA 1 "OFF" 0 "ON/Default Value" ;
VAL_ 1416 AUTO_TOPVIEW_ON_PAS_FRONT 1 "Disable" 0 "Default Value/Enable" ;
VAL_ 1416 RVC_TTS 1 "Mute" 0 "Unmute/Default Value" ;
VAL_ 1416 SET_PARKBRAKE_AUTO_ACT_IS 1 "ON" 0 "Default Value/Off" ;
VAL_ 1416 AVM_CONTROL_IS 1 "ON" 0 "OFF" ;
VAL_ 1416 FOGLAMP_CONTROL_IS 3 "Reserved" 2 "OFF" 1 "ON" 0 "Default Value/No Request" ;
VAL_ 1416 AUTO_TOPVIEW_ON_PAS_REAR 1 "Disable" 0 "Default Value/Enable" ;
VAL_ 1416 SET_SERVICE_MODE_IS 1 "Disable" 0 "Default Value/Enable" ;
VAL_ 1416 STS_PROFILE_LOCK_IS 1 "enable" 0 "Default/disable" ;
VAL_ 1416 SET_SMART_ENERGY_IS 1 "Enable" 0 "Disable/DV" ;
VAL_ 1416 HEADLAMP_CONTROL_IS 3 "Reserved" 2 "OFF" 1 "ON" 0 "Default Value/No Request" ;
VAL_ 1416 AMBIENT_LIGHT_CONTROL_IS 3 "Reserved" 2 "ON" 1 "Off" 0 "Default Value" ;
VAL_ 1416 SUNROOF_CONTROL_IS 3 "Reserved" 2 "Sunroof Close" 1 "Sunroof Open" 0 "Default Value" ;
VAL_ 1416 PWR_WINDOW_CONTROL_IS 3 "Reserved" 2 "Power Window Open" 1 "Power Window Close" 0 "Default Value" ;
VAL_ 1416 DOOR_LOCK_CONTROL_IS 3 "Reserved" 2 "Reserved" 1 "Lock" 0 "Default Value/No Request" ;
VAL_ 1416 SET_REMOTE_ENG_STARTSTOP 1 "Disable" 0 "Defaul Value/Enable" ;
VAL_ 1416 SET_WALK_AWAY_LCK_IS 1 "Enable" 0 "Disable/Default Value" ;
VAL_ 1416 SET_APPROACH_UNLCK_IS 1 "Disable" 0 "Enable/Default Value" ;
VAL_ 1408 STS_EPB 1 "Available" 0 "Not Available / Default" ;
VAL_ 1408 AVH_FUNCTION_STS 1 "Available" 0 "Not Available / Default" ;
VAL_ 1408 AVH_ACTIVE_STS 3 "Invalid" 2 "Released" 1 "Applied" 0 "Stand-By / Default" ;
VAL_ 1408 EPB_ALERT 7 "Reserved" 6 "Reserved" 5 "drvdoor close & seat belt fasted" 4 "EPB Automatically Released" 3 "EPB Automatically locked" 2 "Shift to N or P" 1 "Press Brake" 0 "No Alert / Default" ;
VAL_ 1408 PARK_BRK_ACTIVE_STS 3 "Invalid Status" 2 "In-Progress" 1 "Released " 0 "Applied / Default" ;
VAL_ 1408 RR_PARK_BRK_ACTIVE_STS 3 "Invalid Status" 2 "In-Progress" 1 "Released " 0 "Applied / Default" ;
VAL_ 1408 RL_PARK_BRK_ACTIVE_STS 3 "Invalid Status" 2 "In-Progress" 1 "Released " 0 "Applied / Default" ;
VAL_ 977 POT_HOLE_SPD_BRK_ALERT 3 "Reserved" 2 "Speed Brake" 1 "Pothole" 0 "No Alert / Default" ;
VAL_ 977 CABIN_HVAC_REQ 3 "Reserved" 2 "CABIN HVAC REQUEST" 1 "Reserved" 0 "NO REQUEST/ DEFAULT" ;
VAL_ 977 OVER_SPD_MCM 1 "over speed Alert" 0 "No Alert / Default" ;
VAL_ 977 REQ_REAR_DEFOG_MCM 3 "Signal invalid" 2 " Default value" 1 "ON" 0 "OFF" ;
VAL_ 977 SET_TEMP_MCM 254 "Default value" 255 "Signal invalid" ;
VAL_ 977 AIR_PURIFIER_AUTO_MCM 1 "On Request" 0 "Default Value/OFF" ;
VAL_ 977 MCMTRG_R 1 "Invalid/Default Value" 0 "Valid" ;
VAL_ 977 REMOTE_VEH_IMMOB_MCM 3 "Reserve" 2 "Remote Veh Immobilization Rel" 1 "Remote Veh Immobilization Req" 0 "No Action" ;
VAL_ 977 DISP_MODE_MCM 3 "Signal invalid" 2 "Default Value" 1 "Front Defrost ON request" 0 "Front Defrost OFF request" ;
VAL_ 532 VEH_THEFT_STS 1 "Theft" 0 "Not Theft /Default" ;
VAL_ 532 STS_DRL 1 "DRL ON" 0 "DRL OFF / Default" ;
VAL_ 532 TPMS_SYSTEM_FAULT 0 "Default value" ;
VAL_ 532 TPMS_SIGNAL_MISSING 0 "Default value" ;
VAL_ 532 TPMS_PROG_MODE 15 "signal invalid" 8 "Learning not completed" 7 "All tyre learning completed" 6 "Spare tyre Learned" 5 "Learning Spare tyre" 4 "Learning RL tyre" 3 "Learning RR tyre" 2 "Learning FR tyre" 1 "Learning FL Tyre" 0 "Normal mode / default" ;
VAL_ 532 TPMS_LEAKAGE_ALERT 0 "Default value" ;
VAL_ 532 TPMS_ID_NOT_LEARNT 31 "All tyre ssor nt learn" 30 "(FR+RR+RL+spare) tyre ssor nt le" 29 "(FL+RR+RL+spare) tyre ssor nt le" 28 "(RR+RL+spare) tyre ssor nt learn" 27 "(FL+FR+RL+spare) tyre ssor nt le" 26 "(FR+RL+spare) tyre ssor nt learn" 25 "(FL+RL+spare) tyre ssor nt learn" 24 "(RL+spare) tyre sensor not learn" 23 "(FL+FR+RR+Spare) tyre ssor nt le" 22 "(FR+RR+Spare) tyre sensor not le" 21 "(FL+RR+Spare) tyre snsor not lea" 20 "(RR+Spare) tyre sensor not lea" 19 "(FL+FR+Spare) tyre snsor not lea" 18 "(FR+Spare) tyre sensor not learn" 17 "(FL+Spare) tyre sensor not learn" 16 "Spare tyre sensor not learned" 15 "(FL+FR+RR +RL)tyre snsor not lea" 14 "(FR+RR +RL)tyre sensor not lea" 13 "(FL+RR +RL)tyre sensor not lea" 12 "(RR +RL)tyre sensor not learned" 11 "(FL+FR +RL)tyre sensor not lea" 10 "(FR +RL)tyre sensor not learned" 9 "(FL +RL)tyre sensor not learned" 8 "RL tyre sensor not learned" 7 "(FL+FR +RR)tyre sensor not le" 6 "(FR +RR)tyre sensor not learned" 5 "(FL +RR)tyre sensor not learned" 4 "RR tyre sensor not learned" 3 "(FL +FR)tyre sensor not learned" 2 "FR tyre sensor not learned" 1 "FL tyre sensor not learned" 0 "All sensor learned / Default" ;
VAL_ 532 STS_TPMS_LED 7 "Reserved" 6 "Reserved" 5 "Reserved" 4 "Reserved" 3 "Continously ON" 2 "Blinking pattern 2" 1 "Blinking pattern 1" 0 "OFF / Default value" ;
VAL_ 532 SPARE_TYRE_SWAP 7 "Signal Invalid" 4 "RL tyre swapped" 3 "RR tyre swapped" 2 "FR tyre swapped" 1 "FL tyre swapped" 0 "No spare tyre swap / default " ;
VAL_ 532 REQ_TFA_PATTERN 5 "Pattern 5" 4 "Pattern 4" 3 "Pattern 3" 2 "Pattern 2" 1 "Pattern 1" 0 "Default" ;
VAL_ 532 REQ_TFA_DISPLAY 1 "TFA display request" 0 "No Request / Default" ;
VAL_ 532 LOW_TYRE_PRESSURE 31 "All tyre low pressure" 30 "(FR+RR+RL+spare) tyre low press" 29 "(FL+RR+RL+spare) tyre low press" 28 "(RR+RL+spare) tyre low pressure" 27 "(FL+FR+RL+spare) tyre low press" 26 "(FR+RL+spare) tyre low pressure" 25 "(FL+RL+spare) tyre low pressure" 24 "(RL+spare) tyre low pressure" 23 "(FL+FR+RR+Spare) tyre low press" 22 "(FR+RR+Spare) tyre low press" 21 "(FL+RR+Spare) tyre low pressure" 20 "(RR+Spare) tyre low pressure" 19 "(FL+FR+Spare) tyre low pressure" 18 "(FR+Spare) tyre low pressure" 17 "(FL+Spare) tyre low pressure" 16 "Spare tyre low pressure" 15 "(FL+FR+RR +RL)tyre low pressure" 14 "(FR+RR +RL)tyre low pressure" 13 "(FL+RR +RL)tyre low pressure" 12 "(RR +RL)tyre low pressure" 11 "(FL+FR +RL)tyre low pressure" 10 "(FR +RL)tyre low pressure" 9 "(FL +RL)tyre low pressure" 8 "RL tyre low pressure" 7 "(FL+FR +RR)tyre low pressure" 6 "(FR +RR)tyre low pressure" 5 "(FL +RR)tyre low pressure" 4 "RR tyre low pressure" 3 "(FL +FR)tyre low pressure" 2 "FR tyre low pressure" 1 "FL tyre low pressure" 0 "All tyre normal / Default value" ;
VAL_ 532 HIGH_TYRE_TEMPERATURE 31 "All tyre high  temp" 30 "(FR+RR+RL+spare) tyre high  temp" 29 "(FL+RR+RL+spare) tyre high  temp" 28 "(RR+RL+spare) tyre high  temp" 27 "(FL+FR+RL+spare) tyre high  temp" 26 "(FR+RL+spare) tyre high  temp" 25 "(FL+RL+spare) tyre high  temp" 24 "(RL+spare) tyre high  temp" 23 "(FL+FR+RR+Spare) tyre high  temp" 22 "(FR+RR+Spare) tyre high  temp" 21 "(FL+RR+Spare) tyre high  temp" 20 "(RR+Spare) tyre high  temp" 19 "(FL+FR+Spare) tyre high  temp" 18 "(FR+Spare) tyre high  temp" 17 "(FL+Spare) tyre high  temp" 16 "Spare tyre high  temp" 15 "(FL+FR+RR +RL)tyre high  temp" 14 "(FR+RR +RL)tyre high  temp" 13 "(FL+RR +RL)tyre high  temp" 12 "(RR +RL)tyre high  temp" 11 "(FL+FR +RL)tyre high  temp" 10 "(FR +RL)tyre high  temp" 9 "(FL +RL)tyre high  temp" 8 "RL tyre high  temp" 7 "(FL+FR +RR)tyre high  temp" 6 "(FR +RR)tyre high  temp" 5 "(FL +RR)tyre high  temp" 4 "RR tyre high  temp" 3 "(FL +FR)tyre high  temp" 2 "FR tyre high temp" 1 "FL tyre high temp" 0 "All tyre normal / Default value" ;
VAL_ 532 HIGH_TYRE_PRESSURE 31 "All tyre high pressure" 30 "(FR+RR+RL+spare) tyre high press" 29 "(FL+RR+RL+spare) tyre high press" 28 "(RR+RL+spare) tyre high pressure" 27 "(FL+FR+RL+spare) tyre high press" 26 "(FR+RL+spare) tyre high pressure" 25 "(FL+RL+spare) tyre high pressure" 24 "(RL+spare) tyre high pressure" 23 "(FL+FR+RR+Spare) tyre high press" 22 "(FR+RR+Spare) tyre high press" 21 "(FL+RR+Spare) tyre high pressure" 20 "(RR+Spare) tyre high pressure" 19 "(FL+FR+Spare) tyre high pressure" 18 "(FR+Spare) tyre high pressure" 17 "(FL+Spare) tyre high pressure" 16 "Spare tyre high pressure" 15 "(FL+FR+RR +RL)tyre high pressure" 14 "(FR+RR +RL)tyre high pressure" 13 "(FL+RR +RL)tyre high pressure" 12 "(RR +RL)tyre high pressure" 11 "(FL+FR +RL)tyre high pressure" 10 "(FR +RL)tyre high pressure" 9 "(FL +RL)tyre high pressure" 8 "RL tyre high pressure" 7 "(FL+FR +RR)tyre high pressure" 6 "(FR +RR)tyre high pressure" 5 "(FL +RR)tyre high pressure" 4 "RR tyre high pressure" 3 "(FL +FR)tyre high pressure" 2 "FR tyre high pressure" 1 "FL tyre high pressure" 0 "All tyre normal / Default value" ;
VAL_ 532 STS_DOOR_LATCH 3 "Signal Invalid" 2 "Reserved" 1 "Locked" 0 "Unlocked" ;
VAL_ 843 ESCL_STEER_WHL_JAM_WRN 1 "steering column not jammed" 0 "steering column jammed" ;
VAL_ 843 ESCL_WRN_SFTY 1 "Failure Detected" 0 "No Failure" ;
VAL_ 843 ESCL_WRN_FUNC 1 "Failure Detected" 0 "No Failure" ;
VAL_ 843 ESCL_NOT_LEARNED_WRN 1 "ESCL Not Learned" 0 "ESCL Learned" ;
VAL_ 843 ESCL_NOT_LOCK_WRN 1 " Active" 0 "not Active" ;
